VERSION "V5.0.0"

NS_ :

BS_:

BU_: SGW_SG CGW_SG

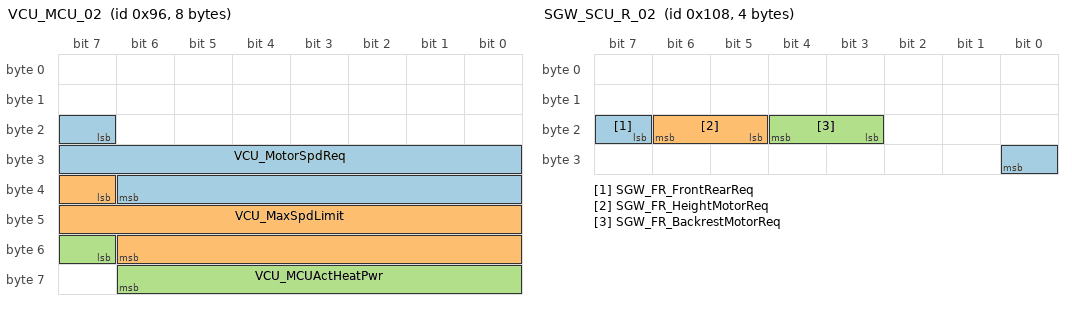
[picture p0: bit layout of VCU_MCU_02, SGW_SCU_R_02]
BO_ 150 VCU_MCU_02: 8 CGW_SG
 SG_ VCU_MotorSpdReq : 23|16@1+ (1,-32767) [-32767|32767] ""  SGW_SG
 SG_ VCU_MaxSpdLimit : 39|16@1+ (1,-32767) [-32767|32767] ""  SGW_SG
 SG_ VCU_MCUActHeatPwr : 55|8@1+ (0,0) [0|10] "kW"  SGW_SG

BO_ 194 BMS_status_02: 9 CGW_SG
 SG_ BMS_BattVolt : 23|14@1+ (0,0) [0|1000] "V"  SGW_SG
 SG_ BMS_BattCurr : 39|15@1+ (0,-1024) [-1024|1023] "A"  SGW_SG
 SG_ BMS_Heatcurrent : 55|16@1+ (0,-1024) [-1024|1023] "A"  SGW_SG

BO_ 257 CBM_request_01: 4 SGW_SG
 SG_ CBM_BLE_CarSearchReq : 26|1@1+ (1,0) [0|1] ""  CGW_SG

BO_ 259 SGW_SCU_L_01: 9 SGW_SG
 SG_ IVI_L_DsSeatBackPos : 23|8@1+ (1,0) [0|100] "percent"  CGW_SG
 SG_ IVI_L_DsSeatHeightPos : 31|8@1+ (1,0) [0|100] "percent"  CGW_SG
 SG_ IVI_L_DsSeatSlidePos : 39|8@1+ (1,0) [0|100] "percent"  CGW_SG
 SG_ IVI_DrSeatHeatLevelSet : 51|3@1+ (1,0) [0|7] ""  CGW_SG
 SG_ IVI_DrSeatWelcomeLevelSet : 63|2@1+ (1,0) [0|3] ""  CGW_SG

BO_ 260 SGW_SCU_R_01: 9 SGW_SG
 SG_ IVI_R_DsSeatSlidePos : 23|8@1+ (1,0) [0|100] "percent"  CGW_SG
 SG_ IVI_R_DsSeatHeightPos : 31|8@1+ (1,0) [0|100] "percent"  CGW_SG
 SG_ IVI_R_DsSeatBackPos : 39|8@1+ (1,0) [0|100] "percent"  CGW_SG
 SG_ IVI_PassSeatHeatLevelSet : 51|3@1+ (1,0) [0|7] ""  CGW_SG
 SG_ IVI_PsSeatWelcomeLevelSet : 63|2@1+ (1,0) [0|3] ""  CGW_SG

BO_ 262 SGW_RemoteCmd_02: 5 SGW_SG
 SG_ IVI_HUDScreenBrightnessSet : 31|5@1+ (1,0) [0|31] ""  CGW_SG

BO_ 264 SGW_SCU_R_02: 4 SGW_SG
 SG_ SGW_FR_FrontRearReq : 23|2@1+ (1,0) [0|2] ""  CGW_SG
 SG_ SGW_FR_HeightMotorReq : 21|2@1+ (1,0) [0|2] ""  CGW_SG
 SG_ SGW_FR_BackrestMotorReq : 19|2@1+ (1,0) [0|2] ""  CGW_SG

BO_ 267 BCM_10: 5 CGW_SG
 SG_ BCM_CentralLockFeedback : 38|2@1+ (1,0) [0|3] ""  SGW_SG
 SG_ BCM_LVonReqKeyNotInCar : 36|1@1+ (1,0) [0|1] ""  SGW_SG

BO_ 268 SGW_10: 9 SGW_SG
 SG_ SGW_PENFCAuthSt : 5|1@1+ (1,0) [0|1] ""  CGW_SG
 SG_ SGW_GetNFCKeyCardsReq : 4|1@1+ (1,0) [0|1] ""  CGW_SG
 SG_ SGW_NFCPairModeReq : 3|1@1+ (1,0) [0|1] ""  CGW_SG
 SG_ SGW_SecOCFV_10C : 23|16@1+ (1,0) [0|65535] ""  CGW_SG
 SG_ SGW_SecOCMAC_10C : 39|32@1+ (1,0) [0|4294967295] ""  CGW_SG

BO_ 271 Switches_03: 1 CGW_SG
 SG_ Switches_L_SWipe_Cmd : 0|4@1+ (1,0) [0|15] ""  SGW_SG

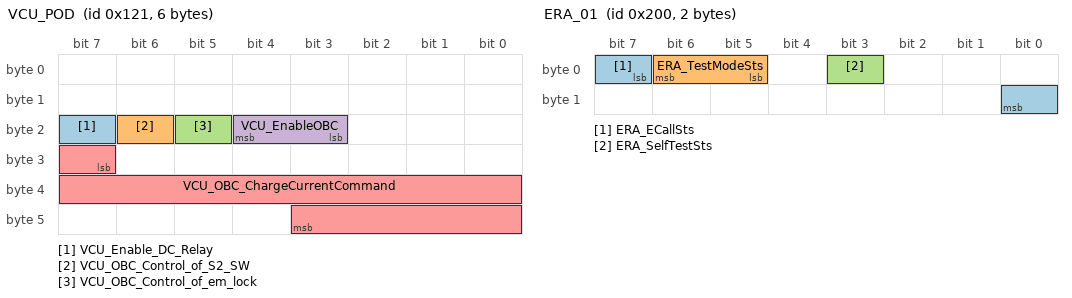
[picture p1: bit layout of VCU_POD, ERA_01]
BO_ 289 VCU_POD: 6 CGW_SG
 SG_ VCU_Enable_DC_Relay : 23|1@1+ (1,0) [0|1] ""  SGW_SG
 SG_ VCU_OBC_Control_of_S2_SW : 22|1@1+ (1,0) [0|1] ""  SGW_SG
 SG_ VCU_OBC_Control_of_em_lock : 21|1@1+ (1,0) [0|1] ""  SGW_SG
 SG_ VCU_EnableOBC : 19|2@1+ (1,0) [0|3] ""  SGW_SG
 SG_ VCU_OBC_ChargeCurrentCommand : 31|13@1+ (0,0) [0|500] "A"  SGW_SG

BO_ 311 DCM_RL_02: 1 CGW_SG
 SG_ DCM_RL_PriorSoundReq : 7|1@1+ (1,0) [0|1] ""  SGW_SG

BO_ 312 DCM_RR_02: 1 CGW_SG
 SG_ DCM_RR_PriorSoundReq : 7|1@1+ (1,0) [0|1] ""  SGW_SG

BO_ 316 SGW_RemoteCmd_04: 9 SGW_SG
 SG_ SGW_L_MirrorMainHorizontalPos : 7|8@1+ (1,0) [0|100] "percent"  CGW_SG
 SG_ SGW_L_MirrorMainVerticalPos : 15|8@1+ (1,0) [0|100] "percent"  CGW_SG
 SG_ SGW_R_MirrorMainHorizontalPos : 23|8@1+ (1,0) [0|100] "percent"  CGW_SG
 SG_ SGW_R_MirrorMainVerticalPos : 31|8@1+ (1,0) [0|100] "percent"  CGW_SG
 SG_ SGW_L_MirrorTiltHorizontalPos : 39|8@1+ (1,0) [0|100] "percent"  CGW_SG
 SG_ SGW_L_MirrorTiltVerticalPos : 47|8@1+ (1,0) [0|100] "percent"  CGW_SG
 SG_ SGW_R_MirrorTiltHorizontalPos : 55|8@1+ (1,0) [0|100] "percent"  CGW_SG
 SG_ SGW_R_MirrorTiltVerticalPos : 63|8@1+ (1,0) [0|100] "percent"  CGW_SG

BO_ 317 BCM_SynReq_01: 4 CGW_SG
 SG_ BCM_SynRequest : 7|24@1+ (1,0) [0|16777215] ""  SGW_SG

BO_ 319 VCU_SynReq_01: 4 CGW_SG
 SG_ VCU_SynRequest : 7|24@1+ (1,0) [0|16777215] ""  SGW_SG

BO_ 512 ERA_01: 2 SGW_SG
 SG_ ERA_ECallSts : 7|2@1+ (1,0) [0|3] ""  CGW_SG
 SG_ ERA_TestModeSts : 5|2@1+ (1,0) [0|3] ""  CGW_SG
 SG_ ERA_SelfTestSts : 3|1@1+ (1,0) [0|1] ""  CGW_SG

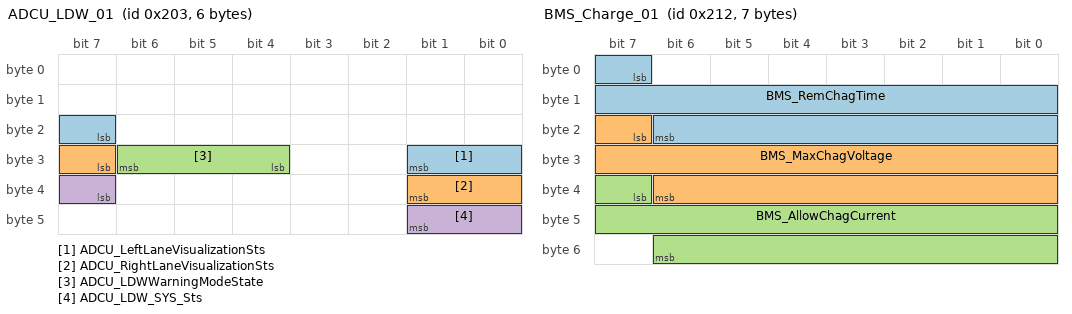
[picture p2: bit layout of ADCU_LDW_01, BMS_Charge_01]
BO_ 515 ADCU_LDW_01: 6 CGW_SG
 SG_ ADCU_LeftLaneVisualizationSts : 23|3@1+ (1,0) [0|5] ""  CGW_SG
 SG_ ADCU_RightLaneVisualizationSts : 31|3@1+ (1,0) [0|5] ""  CGW_SG
 SG_ ADCU_LDWWarningModeState : 28|3@1+ (1,0) [0|7] ""  CGW_SG
 SG_ ADCU_LDW_SYS_Sts : 39|3@1+ (1,0) [0|7] ""  SGW_SG

BO_ 530 BMS_Charge_01: 7 CGW_SG
 SG_ BMS_RemChagTime : 7|16@1+ (1,0) [0|3600] "min"  SGW_SG
 SG_ BMS_MaxChagVoltage : 23|16@1+ (0,0) [0|6553] "V"  SGW_SG
 SG_ BMS_AllowChagCurrent : 39|16@1+ (0,-1000) [-1000|1000] "A"  SGW_SG

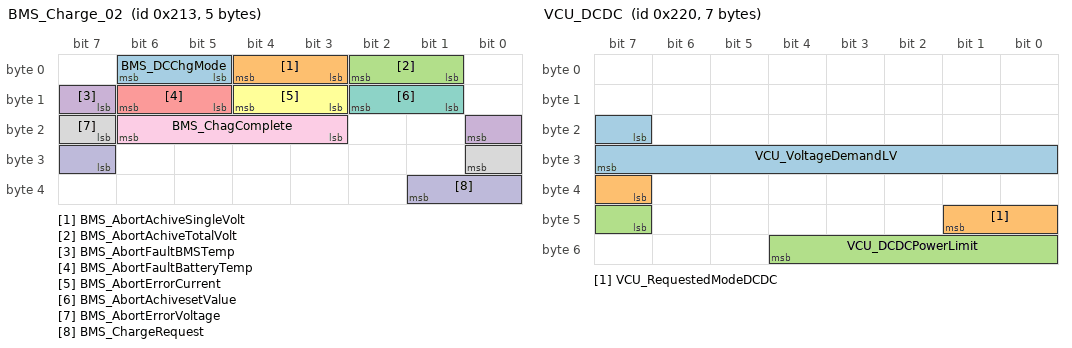
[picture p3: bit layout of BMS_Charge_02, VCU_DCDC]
BO_ 531 BMS_Charge_02: 5 CGW_SG
 SG_ BMS_DCChgMode : 5|2@1+ (1,0) [0|2] ""  SGW_SG
 SG_ BMS_AbortAchiveSingleVolt : 3|2@1+ (1,0) [0|2] ""  SGW_SG
 SG_ BMS_AbortAchiveTotalVolt : 1|2@1+ (1,0) [0|2] ""  SGW_SG
 SG_ BMS_AbortFaultBMSTemp : 15|2@1+ (1,0) [0|2] ""  SGW_SG
 SG_ BMS_AbortFaultBatteryTemp : 13|2@1+ (1,0) [0|2] ""  SGW_SG
 SG_ BMS_AbortErrorCurrent : 11|2@1+ (1,0) [0|2] ""  SGW_SG
 SG_ BMS_AbortAchivesetValue : 9|2@1+ (1,0) [0|2] ""  SGW_SG
 SG_ BMS_AbortErrorVoltage : 23|2@1+ (1,0) [0|2] ""  SGW_SG
 SG_ BMS_ChagComplete : 19|4@1+ (1,0) [0|3] ""  SGW_SG
 SG_ BMS_ChargeRequest : 31|3@1+ (1,0) [0|4] ""  SGW_SG

BO_ 532 BMS_status_03: 9 CGW_SG
 SG_ BMS_PackVoltage : 7|16@1+ (0,0) [0|6553] "V"  SGW_SG
 SG_ BMS_LinkVoltage : 23|16@1+ (0,0) [0|6553] "V"  SGW_SG
 SG_ BMS_SOC : 39|16@1+ (0,0) [0|100] "percent"  SGW_SG
 SG_ BMS_DisplaySOC : 55|16@1+ (0,0) [0|100] "percent"  SGW_SG

BO_ 536 BMS_CellTemp: 9 CGW_SG
 SG_ BMS_ThermometerProbes : 7|8@1+ (1,0) [0|255] ""  SGW_SG
 SG_ BMS_AverageCellTemp : 15|8@1+ (1,-40) [-40|215] "celsius"  SGW_SG
 SG_ BMS_MaxCellTemp : 23|8@1+ (1,-40) [-40|215] "celsius"  SGW_SG
 SG_ BMS_MinCellTemp : 31|8@1+ (1,-40) [-40|215] "celsius"  SGW_SG
 SG_ BMS_MaxCellTempModuleNO : 39|8@1+ (1,0) [0|255] ""  SGW_SG
 SG_ BMS_MinCellTempModuleNO : 47|8@1+ (1,0) [0|255] ""  SGW_SG
 SG_ BMS_MaxCellTempNO : 55|8@1+ (1,0) [0|255] ""  SGW_SG
 SG_ BMS_MinCellTempNO : 63|8@1+ (1,0) [0|255] ""  SGW_SG

BO_ 544 VCU_DCDC: 7 CGW_SG
 SG_ VCU_VoltageDemandLV : 23|9@1+ (0,0) [0|63] "V"  SGW_SG
 SG_ VCU_RequestedModeDCDC : 39|3@1+ (1,0) [0|2] ""  SGW_SG
 SG_ VCU_DCDCPowerLimit : 47|6@1+ (0,0) [0|6] "kW"  SGW_SG

BO_ 547 VCU_04: 2 CGW_SG
 SG_ VCU_ForwardVmaxlimitStatus : 15|1@1+ (1,0) [0|1] ""  SGW_SG
 SG_ VCU_ManuallyUnlockComment : 14|1@1+ (1,0) [0|1] ""  SGW_SG

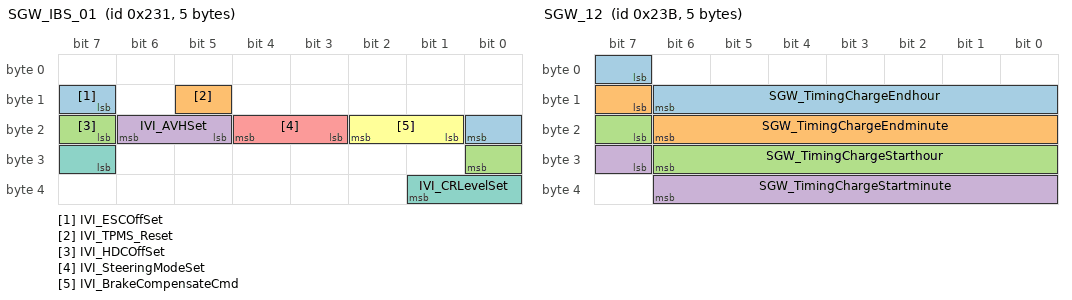
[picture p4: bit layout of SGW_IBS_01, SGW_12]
BO_ 561 SGW_IBS_01: 5 SGW_SG
 SG_ IVI_ESCOffSet : 15|2@1+ (1,0) [0|3] ""  CGW_SG
 SG_ IVI_TPMS_Reset : 13|1@1+ (1,0) [0|1] ""  CGW_SG
 SG_ IVI_HDCOffSet : 23|2@1+ (1,0) [0|3] ""  CGW_SG
 SG_ IVI_AVHSet : 21|2@1+ (1,0) [0|3] ""  CGW_SG
 SG_ IVI_SteeringModeSet : 19|2@1+ (1,0) [0|3] ""  CGW_SG
 SG_ IVI_BrakeCompensateCmd : 17|2@1+ (1,0) [0|3] ""  CGW_SG
 SG_ IVI_CRLevelSet : 31|3@1+ (1,0) [0|7] ""  CGW_SG

BO_ 569 SGW_BCM_03: 9 SGW_SG
 SG_ SGW_RoleAccessSts : 7|1@1+ (1,0) [0|1] ""  CGW_SG
 SG_ SGW_FaceIDAuthenticationSuccess : 5|1@1+ (1,0) [0|1] ""  CGW_SG
 SG_ SGW_ImmobilizingEnable : 1|2@1+ (1,0) [0|2] ""  CGW_SG
 SG_ SGW_SecOCFV_239 : 23|16@1+ (1,0) [0|65535] ""  CGW_SG
 SG_ SGW_SecOCMAC_239 : 39|32@1+ (1,0) [0|4294967295] ""  CGW_SG

BO_ 571 SGW_12: 5 SGW_SG
 SG_ SGW_TimingChargeEndhour : 7|8@1+ (1,0) [0|31] "h"  CGW_SG
 SG_ SGW_TimingChargeEndminute : 15|8@1+ (1,0) [0|63] "min"  CGW_SG
 SG_ SGW_TimingChargeStarthour : 23|8@1+ (1,0) [0|31] "h"  CGW_SG
 SG_ SGW_TimingChargeStartminute : 31|8@1+ (1,0) [0|63] "min"  CGW_SG

BO_ 574 SGW_DCM_02: 9 SGW_SG
 SG_ IVI_FLDoorLockSet : 45|2@1+ (1,0) [0|3] ""  CGW_SG
 SG_ IVI_FRDoorLockSet : 43|2@1+ (1,0) [0|3] ""  CGW_SG
 SG_ IVI_RLDoorLockSet : 41|2@1+ (1,0) [0|3] ""  CGW_SG
 SG_ IVI_RRDoorLockSet : 55|2@1+ (1,0) [0|3] ""  CGW_SG
 SG_ IVI_PassWindowLockSet : 63|2@1+ (1,0) [0|3] ""  CGW_SG
 SG_ IVI_ModeEnterReq : 35|4@1+ (1,0) [0|15] ""  CGW_SG

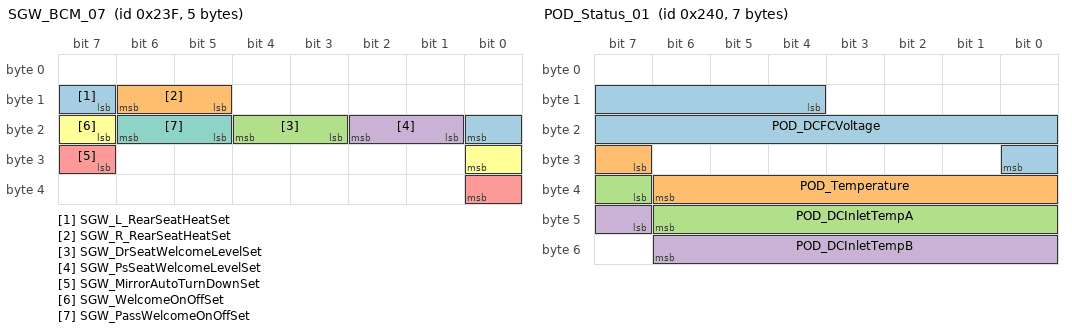
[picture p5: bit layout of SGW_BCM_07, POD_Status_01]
BO_ 575 SGW_BCM_07: 5 SGW_SG
 SG_ SGW_L_RearSeatHeatSet : 15|2@1+ (1,0) [0|3] ""  CGW_SG
 SG_ SGW_R_RearSeatHeatSet : 13|2@1+ (1,0) [0|3] ""  CGW_SG
 SG_ SGW_DrSeatWelcomeLevelSet : 19|2@1+ (1,0) [0|3] ""  CGW_SG
 SG_ SGW_PsSeatWelcomeLevelSet : 17|2@1+ (1,0) [0|3] ""  CGW_SG
 SG_ SGW_MirrorAutoTurnDownSet : 31|2@1+ (1,0) [0|3] ""  CGW_SG
 SG_ SGW_WelcomeOnOffSet : 23|2@1+ (1,0) [0|3] ""  CGW_SG
 SG_ SGW_PassWelcomeOnOffSet : 21|2@1+ (1,0) [0|3] ""  CGW_SG

BO_ 576 POD_Status_01: 7 CGW_SG
 SG_ POD_DCFCVoltage : 12|13@1+ (0,0) [0|819] "V"  SGW_SG
 SG_ POD_Temperature : 31|8@1+ (1,-40) [-40|215] "celsius"  SGW_SG
 SG_ POD_DCInletTempA : 39|8@1+ (1,-40) [-40|215] "celsius"  SGW_SG
 SG_ POD_DCInletTempB : 47|8@1+ (1,-40) [-40|215] "celsius"  SGW_SG

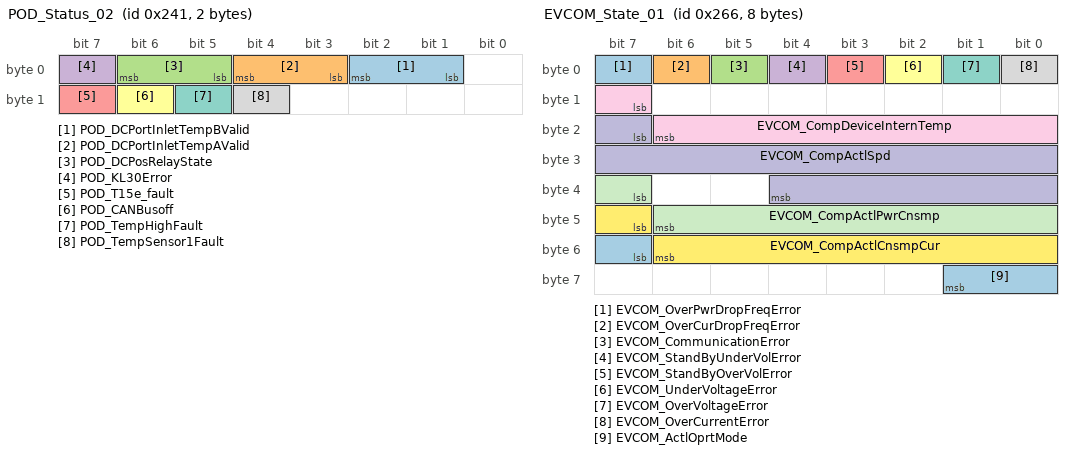
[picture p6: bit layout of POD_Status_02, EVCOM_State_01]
BO_ 577 POD_Status_02: 2 CGW_SG
 SG_ POD_DCPortInletTempBValid : 1|2@1+ (1,0) [0|2] ""  SGW_SG
 SG_ POD_DCPortInletTempAValid : 3|2@1+ (1,0) [0|2] ""  SGW_SG
 SG_ POD_DCPosRelayState : 5|2@1+ (1,0) [0|2] ""  SGW_SG
 SG_ POD_KL30Error : 7|1@1+ (1,0) [0|1] ""  SGW_SG
 SG_ POD_T15e_fault : 15|1@1+ (1,0) [0|1] ""  SGW_SG
 SG_ POD_CANBusoff : 14|1@1+ (1,0) [0|1] ""  SGW_SG
 SG_ POD_TempHighFault : 13|1@1+ (1,0) [0|1] ""  SGW_SG
 SG_ POD_TempSensor1Fault : 12|1@1+ (1,0) [0|1] ""  SGW_SG

BO_ 578 POD_DCDC_01: 9 CGW_SG
 SG_ POD_DCDC_HVInputVoltage : 9|13@1+ (0,0) [0|800] "V"  SGW_SG
 SG_ POD_DCDC_WorkMode : 28|3@1+ (1,0) [0|4] ""  SGW_SG
 SG_ POD_DCDC_LVOutputCurrent : 39|12@1+ (0,0) [0|400] "A"  SGW_SG
 SG_ POD_DCDC_HVInputCurrent : 55|8@1+ (0,0) [0|25] "A"  SGW_SG
 SG_ POD_DCDC_LVOutputVoltage : 63|8@1+ (0,0) [0|25] "V"  SGW_SG

BO_ 580 POD_OBC_STATUS_02: 9 CGW_SG
 SG_ POD_OBC_ChrgOutpPwrAvl : 7|8@1+ (0,-7) [-7|13] "kW"  SGW_SG
 SG_ POD_OBC_OutputDCChargeCurrent : 15|13@1+ (0,-250) [-250|250] "A"  SGW_SG
 SG_ POD_OBC_ACPortTempA : 31|8@1+ (1,-40) [-40|215] "celsius"  SGW_SG
 SG_ POD_OBC_ACPortTempB : 39|8@1+ (1,-40) [-40|215] "celsius"  SGW_SG
 SG_ POD_OBC_ACFrequencyStatus : 47|8@1+ (1,0) [0|255] "Hz"  SGW_SG
 SG_ POD_OBC_OutputDCChargeVoltage : 55|14@1+ (0,-800) [-800|800] "V"  SGW_SG

BO_ 610 TCU_03: 4 CGW_SG
 SG_ TCU_CabinTemperature : 23|8@1+ (1,-50) [-50|205] "celsius"  SGW_SG
 SG_ TCU_CabinTemperatureValid : 31|1@1+ (1,0) [0|1] ""  SGW_SG

BO_ 614 EVCOM_State_01: 8 CGW_SG
 SG_ EVCOM_OverPwrDropFreqError : 7|1@1+ (1,0) [0|1] ""  SGW_SG
 SG_ EVCOM_OverCurDropFreqError : 6|1@1+ (1,0) [0|1] ""  SGW_SG
 SG_ EVCOM_CommunicationError : 5|1@1+ (1,0) [0|1] ""  SGW_SG
 SG_ EVCOM_StandByUnderVolError : 4|1@1+ (1,0) [0|1] ""  SGW_SG
 SG_ EVCOM_StandByOverVolError : 3|1@1+ (1,0) [0|1] ""  SGW_SG
 SG_ EVCOM_UnderVoltageError : 2|1@1+ (1,0) [0|1] ""  SGW_SG
 SG_ EVCOM_OverVoltageError : 1|1@1+ (1,0) [0|1] ""  SGW_SG
 SG_ EVCOM_OverCurrentError : 0|1@1+ (1,0) [0|1] ""  SGW_SG
 SG_ EVCOM_CompDeviceInternTemp : 15|8@1+ (1,-40) [-40|215] "celsius"  SGW_SG
 SG_ EVCOM_CompActlSpd : 23|14@1+ (1,0) [0|9200] "rpm"  SGW_SG
 SG_ EVCOM_CompActlPwrCnsmp : 39|8@1+ (0,0) [0|10] "KW"  SGW_SG
 SG_ EVCOM_CompActlCnsmpCur : 47|8@1+ (0,0) [0|51] "A"  SGW_SG
 SG_ EVCOM_ActlOprtMode : 55|3@1+ (1,0) [0|7] ""  SGW_SG

BO_ 624 BCM_ALM: 1 CGW_SG
 SG_ BCM_ALM1_MusicFrequencySts : 5|1@1+ (1,0) [0|1] ""  SGW_SG
 SG_ BCM_ALM2_MusicFrequencySts : 4|1@1+ (1,0) [0|1] ""  SGW_SG

BO_ 626 BCM_11: 9 CGW_SG
 SG_ BCM_Immo_State : 7|1@1+ (1,0) [0|1] ""  SGW_SG
 SG_ BCM_SecOCFV_272 : 23|16@1+ (1,0) [0|65535] ""  SGW_SG
 SG_ BCM_SecOCMAC_272 : 39|32@1+ (1,0) [0|4294967295] ""  SGW_SG

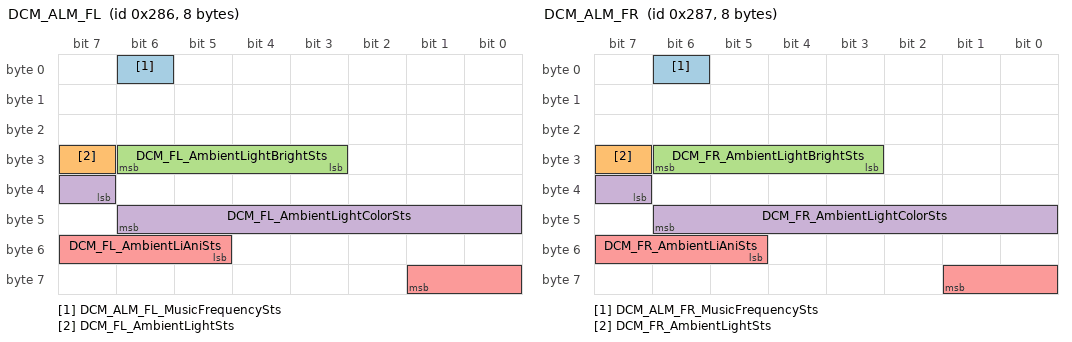
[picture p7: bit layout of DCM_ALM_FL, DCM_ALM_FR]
BO_ 646 DCM_ALM_FL: 8 CGW_SG
 SG_ DCM_ALM_FL_MusicFrequencySts : 6|1@1+ (1,0) [0|1] ""  SGW_SG
 SG_ DCM_FL_AmbientLightSts : 31|1@1+ (1,0) [0|1] ""  SGW_SG
 SG_ DCM_FL_AmbientLightBrightSts : 27|4@1+ (1,0) [0|10] ""  SGW_SG
 SG_ DCM_FL_AmbientLightColorSts : 39|8@1+ (1,0) [0|255] ""  SGW_SG
 SG_ DCM_FL_AmbientLiAniSts : 53|5@1+ (1,0) [0|25] ""  SGW_SG

BO_ 647 DCM_ALM_FR: 8 CGW_SG
 SG_ DCM_ALM_FR_MusicFrequencySts : 6|1@1+ (1,0) [0|1] ""  SGW_SG
 SG_ DCM_FR_AmbientLightSts : 31|1@1+ (1,0) [0|1] ""  SGW_SG
 SG_ DCM_FR_AmbientLightBrightSts : 27|4@1+ (1,0) [0|10] ""  SGW_SG
 SG_ DCM_FR_AmbientLightColorSts : 39|8@1+ (1,0) [0|255] ""  SGW_SG
 SG_ DCM_FR_AmbientLiAniSts : 53|5@1+ (1,0) [0|25] ""  SGW_SG

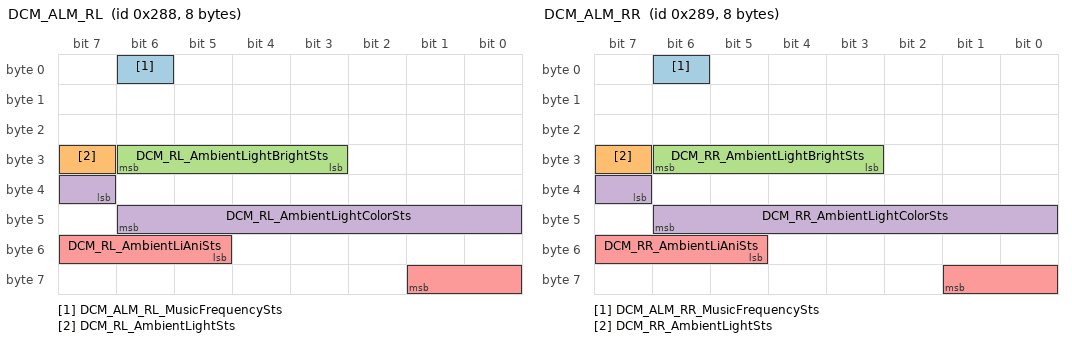
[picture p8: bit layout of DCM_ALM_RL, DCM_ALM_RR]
BO_ 648 DCM_ALM_RL: 8 CGW_SG
 SG_ DCM_ALM_RL_MusicFrequencySts : 6|1@1+ (1,0) [0|1] ""  SGW_SG
 SG_ DCM_RL_AmbientLightSts : 31|1@1+ (1,0) [0|1] ""  SGW_SG
 SG_ DCM_RL_AmbientLightBrightSts : 27|4@1+ (1,0) [0|10] ""  SGW_SG
 SG_ DCM_RL_AmbientLightColorSts : 39|8@1+ (1,0) [0|255] ""  SGW_SG
 SG_ DCM_RL_AmbientLiAniSts : 53|5@1+ (1,0) [0|25] ""  SGW_SG

BO_ 649 DCM_ALM_RR: 8 CGW_SG
 SG_ DCM_ALM_RR_MusicFrequencySts : 6|1@1+ (1,0) [0|1] ""  SGW_SG
 SG_ DCM_RR_AmbientLightSts : 31|1@1+ (1,0) [0|1] ""  SGW_SG
 SG_ DCM_RR_AmbientLightBrightSts : 27|4@1+ (1,0) [0|10] ""  SGW_SG
 SG_ DCM_RR_AmbientLightColorSts : 39|8@1+ (1,0) [0|255] ""  SGW_SG
 SG_ DCM_RR_AmbientLiAniSts : 53|5@1+ (1,0) [0|25] ""  SGW_SG

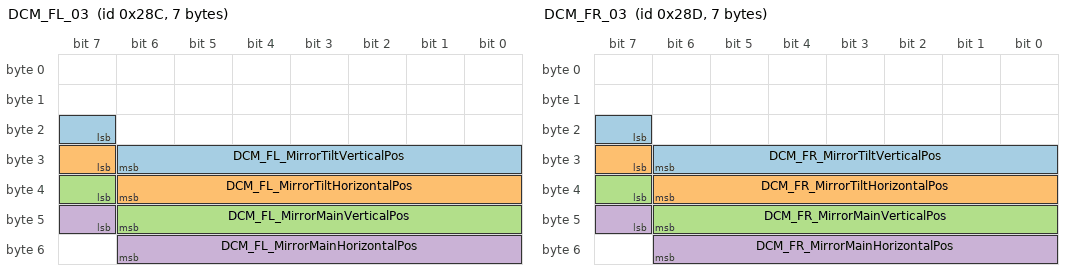
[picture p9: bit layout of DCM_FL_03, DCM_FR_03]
BO_ 652 DCM_FL_03: 7 CGW_SG
 SG_ DCM_FL_MirrorTiltVerticalPos : 23|8@1+ (1,0) [0|100] "percent"  SGW_SG
 SG_ DCM_FL_MirrorTiltHorizontalPos : 31|8@1+ (1,0) [0|100] "percent"  SGW_SG
 SG_ DCM_FL_MirrorMainVerticalPos : 39|8@1+ (1,0) [0|100] "percent"  SGW_SG
 SG_ DCM_FL_MirrorMainHorizontalPos : 47|8@1+ (1,0) [0|100] "percent"  SGW_SG

BO_ 653 DCM_FR_03: 7 CGW_SG
 SG_ DCM_FR_MirrorTiltVerticalPos : 23|8@1+ (1,0) [0|100] "percent"  SGW_SG
 SG_ DCM_FR_MirrorTiltHorizontalPos : 31|8@1+ (1,0) [0|100] "percent"  SGW_SG
 SG_ DCM_FR_MirrorMainVerticalPos : 39|8@1+ (1,0) [0|100] "percent"  SGW_SG
 SG_ DCM_FR_MirrorMainHorizontalPos : 47|8@1+ (1,0) [0|100] "percent"  SGW_SG

BO_ 663 WCBS_01: 1 CGW_SG
 SG_ WCBS1_Reminder : 0|1@1+ (1,0) [0|1] ""  SGW_SG
 SG_ WCBS1_ReminderSts : 1|1@1+ (1,0) [0|1] ""  SGW_SG

BO_ 664 WCBS_02: 1 CGW_SG
 SG_ WCBS2_Reminder : 0|1@1+ (1,0) [0|1] ""  SGW_SG
 SG_ WCBS2_ReminderSts : 1|1@1+ (1,0) [0|1] ""  SGW_SG

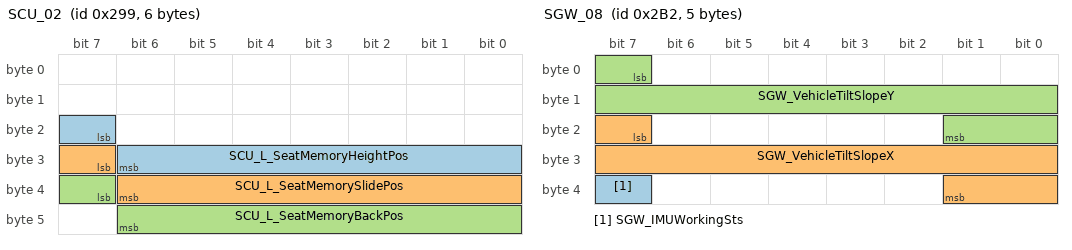
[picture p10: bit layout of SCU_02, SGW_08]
BO_ 665 SCU_02: 6 CGW_SG
 SG_ SCU_L_SeatMemoryHeightPos : 23|8@1+ (1,0) [0|100] "percent"  SGW_SG
 SG_ SCU_L_SeatMemorySlidePos : 31|8@1+ (1,0) [0|100] "percent"  SGW_SG
 SG_ SCU_L_SeatMemoryBackPos : 39|8@1+ (1,0) [0|100] "percent"  SGW_SG

BO_ 689 SGW_HUD_01: 3 SGW_SG
 SG_ IVI_HUDALTITUDESet : 7|8@1+ (1,0) [0|255] ""  CGW_SG
 SG_ IVI_HUDOnOffSet : 15|2@1+ (1,0) [0|3] ""  CGW_SG

BO_ 690 SGW_08: 5 SGW_SG
 SG_ SGW_IMUWorkingSts : 39|1@1+ (1,0) [0|1] ""  CGW_SG
 SG_ SGW_VehicleTiltSlopeX : 23|11@1+ (0,-1) [-1|1] ""  CGW_SG
 SG_ SGW_VehicleTiltSlopeY : 7|11@1+ (0,-1) [-1|1] ""  CGW_SG

BO_ 692 SGW_16: 5 SGW_SG
 SG_ IVI_MirrorInterfaceMode : 21|1@1+ (1,0) [0|1] ""  CGW_SG
 SG_ IVI_VrState : 33|1@1+ (1,0) [0|1] ""  CGW_SG

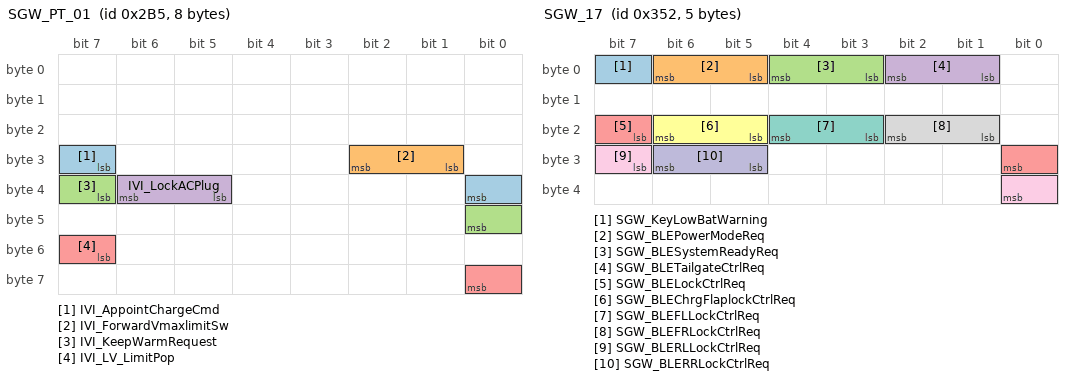
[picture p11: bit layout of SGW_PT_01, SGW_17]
BO_ 693 SGW_PT_01: 8 SGW_SG
 SG_ IVI_AppointChargeCmd : 31|2@1+ (1,0) [0|2] ""  CGW_SG
 SG_ IVI_ForwardVmaxlimitSw : 25|2@1+ (1,0) [0|3] ""  CGW_SG
 SG_ IVI_KeepWarmRequest : 39|2@1+ (1,0) [0|2] ""  CGW_SG
 SG_ IVI_LockACPlug : 37|2@1+ (1,0) [0|2] ""  CGW_SG
 SG_ IVI_LV_LimitPop : 55|2@1+ (1,0) [0|2] ""  CGW_SG

BO_ 694 IVI_01: 3 CGW_SG
 SG_ IVI_GearRequest : 15|3@1+ (1,0) [0|5] ""  SGW_SG

BO_ 710 SGW_SteerWhPos: 6 SGW_SG
 SG_ IVI_StWAnglePos : 31|8@1+ (1,-100) [-100|100] "percent"  CGW_SG
 SG_ IVI_StWLengthPos : 39|8@1+ (1,-100) [-100|100] "percent"  CGW_SG

BO_ 721 CBM_13: 9 SGW_SG
 SG_ CBM_PhoneLocation : 15|8@1+ (1,0) [0|8] ""  CGW_SG
 SG_ CBM_BlePairingSetSts : 7|2@1+ (1,0) [0|2] ""  CGW_SG
 SG_ CBM_SecOCFV_2D1 : 23|16@1+ (1,0) [0|65535] ""  CGW_SG
 SG_ CBM_SecOCMAC_2D1 : 39|32@1+ (1,0) [0|4294967295] ""  CGW_SG

BO_ 795 VCU_HMIsignals_03: 5 CGW_SG
 SG_ VCU_Display_voltage : 23|10@1+ (1,0) [0|1023] "V"  SGW_SG

BO_ 850 SGW_17: 5 SGW_SG
 SG_ SGW_KeyLowBatWarning : 7|1@1+ (1,0) [0|1] ""  CGW_SG
 SG_ SGW_BLEPowerModeReq : 5|2@1+ (1,0) [0|3] ""  CGW_SG
 SG_ SGW_BLESystemReadyReq : 3|2@1+ (1,0) [0|3] ""  CGW_SG
 SG_ SGW_BLETailgateCtrlReq : 1|2@1+ (1,0) [0|3] ""  CGW_SG
 SG_ SGW_BLELockCtrlReq : 23|2@1+ (1,0) [0|3] ""  CGW_SG
 SG_ SGW_BLEChrgFlaplockCtrlReq : 21|2@1+ (1,0) [0|3] ""  CGW_SG
 SG_ SGW_BLEFLLockCtrlReq : 19|2@1+ (1,0) [0|3] ""  CGW_SG
 SG_ SGW_BLEFRLockCtrlReq : 17|2@1+ (1,0) [0|3] ""  CGW_SG
 SG_ SGW_BLERLLockCtrlReq : 31|2@1+ (1,0) [0|3] ""  CGW_SG
 SG_ SGW_BLERRLockCtrlReq : 29|2@1+ (1,0) [0|3] ""  CGW_SG

BO_ 857 SGW_06: 3 SGW_SG
 SG_ SGW_SGWSts : 0|1@1+ (1,0) [0|1] ""  CGW_SG
 SG_ SGW_CGWSts : 1|1@1+ (1,0) [0|1] ""  CGW_SG
 SG_ SGW_CBMSts : 2|1@1+ (1,0) [0|1] ""  CGW_SG
 SG_ SGW_DCM_FLSts : 3|1@1+ (1,0) [0|1] ""  CGW_SG
 SG_ SGW_DCM_FRSts : 4|1@1+ (1,0) [0|1] ""  CGW_SG
 SG_ SGW_DCM_RLSts : 5|1@1+ (1,0) [0|1] ""  CGW_SG
 SG_ SGW_DCM_RRSts : 6|1@1+ (1,0) [0|1] ""  CGW_SG
 SG_ SGW_SCU_LSts : 7|1@1+ (1,0) [0|1] ""  CGW_SG
 SG_ SGW_SCU_RSts : 8|1@1+ (1,0) [0|1] ""  CGW_SG
 SG_ SGW_HLRSts : 9|1@1+ (1,0) [0|1] ""  CGW_SG
 SG_ SGW_HLLSts : 10|1@1+ (1,0) [0|1] ""  CGW_SG
 SG_ SGW_MFP_RCSts : 11|1@1+ (1,0) [0|1] ""  CGW_SG
 SG_ SGW_MFP_FCSts : 12|1@1+ (1,0) [0|1] ""  CGW_SG
 SG_ SGW_IVISts : 13|1@1+ (1,0) [0|1] ""  CGW_SG
 SG_ SGW_ADCUSts : 14|1@1+ (1,0) [0|1] ""  CGW_SG
 SG_ SGW_VCUSts : 15|1@1+ (1,0) [0|1] ""  CGW_SG
 SG_ SGW_BMSSts : 16|1@1+ (1,0) [0|1] ""  CGW_SG
 SG_ SGW_BCMSts : 17|1@1+ (1,0) [0|1] ""  CGW_SG
 SG_ SGW_SWPSts : 18|1@1+ (1,0) [0|1] ""  CGW_SG
 SG_ SGW_HOD_HeatingSts : 19|1@1+ (1,0) [0|1] ""  CGW_SG
 SG_ SGW_SwichesSts : 20|1@1+ (1,0) [0|1] ""  CGW_SG
 SG_ SGW_PRNDSts : 21|1@1+ (1,0) [0|1] ""  CGW_SG

BO_ 858 CGW_02: 3 CGW_SG
 SG_ CGW_SGWSts : 0|1@1+ (1,0) [0|1] ""  SGW_SG
 SG_ CGW_CGWSts : 1|1@1+ (1,0) [0|1] ""  SGW_SG
 SG_ CGW_CBMSts : 2|1@1+ (1,0) [0|1] ""  SGW_SG
 SG_ CGW_DCM_FLSts : 3|1@1+ (1,0) [0|1] ""  SGW_SG
 SG_ CGW_DCM_FRSts : 4|1@1+ (1,0) [0|1] ""  SGW_SG
 SG_ CGW_DCM_RLSts : 5|1@1+ (1,0) [0|1] ""  SGW_SG
 SG_ CGW_DCM_RRSts : 6|1@1+ (1,0) [0|1] ""  SGW_SG
 SG_ CGW_SCU_LSts : 7|1@1+ (1,0) [0|1] ""  SGW_SG
 SG_ CGW_SCU_RSts : 8|1@1+ (1,0) [0|1] ""  SGW_SG
 SG_ CGW_HLRSts : 9|1@1+ (1,0) [0|1] ""  SGW_SG
 SG_ CGW_HLLSts : 10|1@1+ (1,0) [0|1] ""  SGW_SG
 SG_ CGW_MFP_RCSts : 11|1@1+ (1,0) [0|1] ""  SGW_SG
 SG_ CGW_MFP_FCSts : 12|1@1+ (1,0) [0|1] ""  SGW_SG
 SG_ CGW_IVISts : 13|1@1+ (1,0) [0|1] ""  SGW_SG
 SG_ CGW_ADCUSts : 14|1@1+ (1,0) [0|1] ""  SGW_SG
 SG_ CGW_VCUSts : 15|1@1+ (1,0) [0|1] ""  SGW_SG
 SG_ CGW_BMSSts : 16|1@1+ (1,0) [0|1] ""  SGW_SG
 SG_ CGW_BCMSts : 17|1@1+ (1,0) [0|1] ""  SGW_SG
 SG_ CGW_SWPSts : 18|1@1+ (1,0) [0|1] ""  SGW_SG
 SG_ CGW_HOD_HeatingSts : 19|1@1+ (1,0) [0|1] ""  SGW_SG
 SG_ CGW_SwichesSts : 20|1@1+ (1,0) [0|1] ""  SGW_SG
 SG_ CGW_PRNDSts : 21|1@1+ (1,0) [0|1] ""  SGW_SG

BO_ 880 DCM_FL_SDS_01: 3 CGW_SG
 SG_ DCM_SDS_FL_SensorWorksts : 15|3@1+ (1,0) [0|5] ""  SGW_SG

BO_ 881 DCM_FR_SDS_01: 3 CGW_SG
 SG_ DCM_SDS_FR_SensorWorksts : 15|3@1+ (1,0) [0|5] ""  SGW_SG

BO_ 882 DCM_RL_SDS_01: 3 CGW_SG
 SG_ DCM_SDS_RL_SensorWorksts : 15|3@1+ (1,0) [0|5] ""  SGW_SG

BO_ 883 DCM_RR_SDS_01: 3 CGW_SG
 SG_ DCM_SDS_RR_SensorWorksts : 15|3@1+ (1,0) [0|5] ""  SGW_SG

BO_ 896 CGW_VIN1: 9 CGW_SG
 SG_ CGW_VIN0 : 7|8@1+ (1,0) [0|255] ""  SGW_SG
 SG_ CGW_VIN1 : 15|8@1+ (1,0) [0|255] ""  SGW_SG
 SG_ CGW_VIN2 : 23|8@1+ (1,0) [0|255] ""  SGW_SG
 SG_ CGW_VIN3 : 31|8@1+ (1,0) [0|255] ""  SGW_SG
 SG_ CGW_VIN4 : 39|8@1+ (1,0) [0|255] ""  SGW_SG
 SG_ CGW_VIN5 : 47|8@1+ (1,0) [0|255] ""  SGW_SG
 SG_ CGW_VIN6 : 55|8@1+ (1,0) [0|255] ""  SGW_SG
 SG_ CGW_VIN7 : 63|8@1+ (1,0) [0|255] ""  SGW_SG

BO_ 897 CGW_VIN2: 9 CGW_SG
 SG_ CGW_VIN8 : 7|8@1+ (1,0) [0|255] ""  SGW_SG
 SG_ CGW_VIN9 : 15|8@1+ (1,0) [0|255] ""  SGW_SG
 SG_ CGW_VIN10 : 23|8@1+ (1,0) [0|255] ""  SGW_SG
 SG_ CGW_VIN11 : 31|8@1+ (1,0) [0|255] ""  SGW_SG
 SG_ CGW_VIN12 : 39|8@1+ (1,0) [0|255] ""  SGW_SG
 SG_ CGW_VIN13 : 47|8@1+ (1,0) [0|255] ""  SGW_SG
 SG_ CGW_VIN14 : 55|8@1+ (1,0) [0|255] ""  SGW_SG
 SG_ CGW_VIN15 : 63|8@1+ (1,0) [0|255] ""  SGW_SG

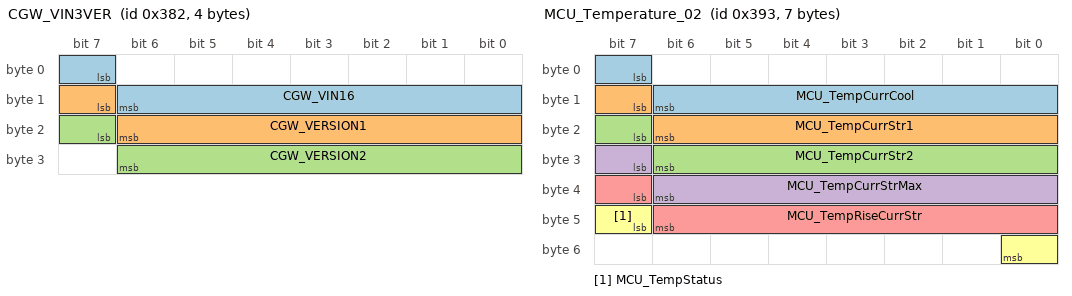
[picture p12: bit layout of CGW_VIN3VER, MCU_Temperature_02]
BO_ 898 CGW_VIN3VER: 4 CGW_SG
 SG_ CGW_VIN16 : 7|8@1+ (1,0) [0|255] ""  SGW_SG
 SG_ CGW_VERSION1 : 15|8@1+ (1,0) [0|5] ""  SGW_SG
 SG_ CGW_VERSION2 : 23|8@1+ (1,0) [0|255] ""  SGW_SG

BO_ 914 MCU_Temperature_01: 9 CGW_SG
 SG_ MCU_IGBTTempU : 7|8@1+ (1,-50) [-50|200] ""  SGW_SG
 SG_ MCU_IGBTTempV : 15|8@1+ (1,-50) [-50|200] ""  SGW_SG
 SG_ MCU_IGBTTempW : 23|8@1+ (1,-50) [-50|200] ""  SGW_SG
 SG_ MCU_IGBTTempMax : 31|8@1+ (1,-50) [-50|200] ""  SGW_SG
 SG_ MCU_IGBTTempRiseU : 39|8@1+ (1,0) [0|200] ""  SGW_SG
 SG_ MCU_IGBTTempRiseV : 47|8@1+ (1,0) [0|200] ""  SGW_SG
 SG_ MCU_IGBTTempRiseW : 55|8@1+ (1,0) [0|200] ""  SGW_SG
 SG_ MCU_IGBTTempRiseMax : 63|8@1+ (1,0) [0|200] ""  SGW_SG

BO_ 915 MCU_Temperature_02: 7 CGW_SG
 SG_ MCU_TempCurrCool : 7|8@1+ (1,-50) [-50|200] ""  SGW_SG
 SG_ MCU_TempCurrStr1 : 15|8@1+ (1,-50) [-50|200] ""  SGW_SG
 SG_ MCU_TempCurrStr2 : 23|8@1+ (1,-50) [-50|200] ""  SGW_SG
 SG_ MCU_TempCurrStrMax : 31|8@1+ (1,-50) [-50|200] ""  SGW_SG
 SG_ MCU_TempRiseCurrStr : 39|8@1+ (1,0) [0|250] ""  SGW_SG
 SG_ MCU_TempStatus : 47|2@1+ (1,0) [0|3] ""  SGW_SG

BO_ 928 MCU_SoftwareNumber: 9 CGW_SG
 SG_ MCU_CodeVer : 7|16@1+ (1,0) [0|65535] ""  SGW_SG
 SG_ MCU_DataVer : 23|16@1+ (1,0) [0|65535] ""  SGW_SG
 SG_ MCU_CpldVer : 39|16@1+ (1,0) [0|65535] ""  SGW_SG
 SG_ MCU_HvMcuVer : 55|16@1+ (1,0) [0|65535] ""  SGW_SG

BO_ 929 MCU_HardwareNumber: 3 CGW_SG
 SG_ MCU_HwVer : 7|16@1+ (1,0) [0|65535] ""  SGW_SG

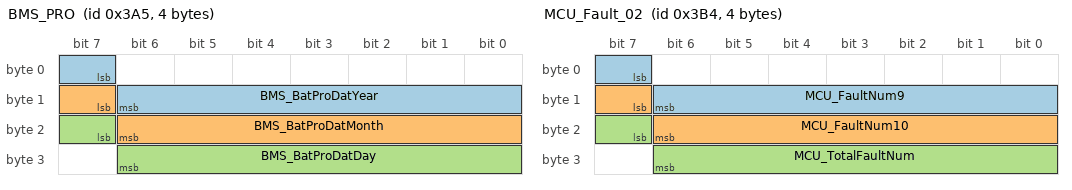
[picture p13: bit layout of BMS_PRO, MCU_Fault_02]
BO_ 933 BMS_PRO: 4 CGW_SG
 SG_ BMS_BatProDatYear : 7|8@1+ (1,0) [0|1] ""  SGW_SG
 SG_ BMS_BatProDatMonth : 15|8@1+ (1,0) [0|1] ""  SGW_SG
 SG_ BMS_BatProDatDay : 23|8@1+ (1,0) [0|1] ""  SGW_SG

BO_ 934 BMS_BatInfor_01: 9 CGW_SG
 SG_ BMS_BatType : 7|8@1+ (1,0) [0|255] ""  CGW_SG
 SG_ BMS_CellNumbers : 15|8@1+ (1,0) [0|255] ""  SGW_SG
 SG_ BMS_RatCapacity : 23|16@1+ (0,0) [0|6553] "Ah"  CGW_SG
 SG_ BMS_RatEnergy : 39|16@1+ (0,0) [0|6553] "KWH"  CGW_SG
 SG_ BMS_RatBatVoltage : 55|16@1+ (0,0) [0|6553] "V"  CGW_SG

BO_ 945 SGW_OdometerInfor_02: 6 SGW_SG
 SG_ SGW_OdometerInfor : 23|24@1+ (0,0) [0|999999] ""  CGW_SG
 SG_ SGW_OdometerInforValid : 47|1@1+ (1,0) [0|1] ""  CGW_SG

BO_ 946 SGW_OdometerInfor_03: 9 SGW_SG
 SG_ SGW_VIN : 7|64@1+ (1,0) [0|6510615555426899968] ""  CGW_SG

BO_ 947 MCU_Fault_01: 9 CGW_SG
 SG_ MCU_FaultNum1 : 7|8@1+ (1,0) [0|255] ""  SGW_SG
 SG_ MCU_FaultNum2 : 15|8@1+ (1,0) [0|255] ""  SGW_SG
 SG_ MCU_FaultNum3 : 23|8@1+ (1,0) [0|255] ""  SGW_SG
 SG_ MCU_FaultNum4 : 31|8@1+ (1,0) [0|255] ""  SGW_SG
 SG_ MCU_FaultNum5 : 39|8@1+ (1,0) [0|255] ""  SGW_SG
 SG_ MCU_FaultNum6 : 47|8@1+ (1,0) [0|255] ""  SGW_SG
 SG_ MCU_FaultNum7 : 55|8@1+ (1,0) [0|255] ""  SGW_SG
 SG_ MCU_FaultNum8 : 63|8@1+ (1,0) [0|255] ""  SGW_SG

BO_ 948 MCU_Fault_02: 4 CGW_SG
 SG_ MCU_FaultNum9 : 7|8@1+ (1,0) [0|255] ""  SGW_SG
 SG_ MCU_FaultNum10 : 15|8@1+ (1,0) [0|255] ""  SGW_SG
 SG_ MCU_TotalFaultNum : 23|8@1+ (1,0) [0|255] ""  SGW_SG

BO_ 960 SGW_FVSynchronization_01: 9 SGW_SG
 SG_ SGW_TripCounter : 7|24@1+ (1,0) [0|16777215] ""  CGW_SG
 SG_ SGW_ResetCounter : 31|16@1+ (1,0) [0|65535] ""  CGW_SG
 SG_ SGW_SynMsgAuthenticator : 47|24@1+ (1,0) [0|16777215] ""  CGW_SG

BO_ 992 BMS_SGW_01: 6 CGW_SG
 SG_ BMS_FeedEnergySts : 7|17@1+ (0,0) [0|9999] ""  SGW_SG
 SG_ BMS_DirveDiscSts : 31|17@1+ (0,0) [0|9999] ""  SGW_SG

BO_ 1025 BCM1_DiagInfor: 2 CGW_SG
 SG_ BCM1_DTC_Number : 7|8@1+ (1,0) [0|255] ""  SGW_SG

BO_ 1026 CGW_DiagInfor: 2 CGW_SG
 SG_ CGW_DTC_Number : 7|8@1+ (1,0) [0|255] ""  SGW_SG

BO_ 1027 SGW_DiagInfor: 2 SGW_SG
 SG_ SGW_DTC_Number : 7|8@1+ (1,0) [0|255] ""  CGW_SG

BO_ 1029 ERA_DiagInfor: 2 SGW_SG
 SG_ ERA_DTC_Number : 7|8@1+ (1,0) [0|255] ""  CGW_SG

BO_ 1030 Switches_DiagInfor: 2 CGW_SG
 SG_ Switches_DTC_Number : 7|8@1+ (1,0) [0|255] ""  SGW_SG

BO_ 1031 SWP_DiagInfor: 2 CGW_SG
 SG_ SWP_DTC_Number : 7|8@1+ (1,0) [0|255] ""  SGW_SG

BO_ 1032 NDT_DiagInfor: 2 CGW_SG
 SG_ NDT_DTC_Number : 7|8@1+ (1,0) [0|255] ""  SGW_SG

BO_ 1033 HOD_heating_DiagInfor: 2 CGW_SG
 SG_ HOD_heating_DTC_Number : 7|8@1+ (1,0) [0|255] ""  SGW_SG

BO_ 1034 CBM_DiagInfor: 2 SGW_SG
 SG_ CBM_DTC_Number : 7|8@1+ (1,0) [0|255] ""  CGW_SG

BO_ 1037 HUD_DiagInfor: 2 CGW_SG
 SG_ HUD_DTC_Number : 7|8@1+ (1,0) [0|255] ""  SGW_SG

BO_ 1038 DIM_DiagInfor: 2 CGW_SG
 SG_ DIM_DTC_Number : 7|8@1+ (1,0) [0|255] ""  SGW_SG

BO_ 1043 BMS_DiagInfor: 2 CGW_SG
 SG_ BMS_DTC_Number : 7|8@1+ (1,0) [0|255] ""  SGW_SG

BO_ 1046 MFP_FC_DiagInfor: 2 CGW_SG
 SG_ MFP_FC_DTC_Number : 7|8@1+ (1,0) [0|255] ""  SGW_SG

BO_ 1049 MFP_RC_DiagInfor: 2 CGW_SG
 SG_ MFP_RC_DTC_Number : 7|8@1+ (1,0) [0|255] ""  SGW_SG

BO_ 1050 BCM2_DiagInfor: 2 CGW_SG
 SG_ BCM2_DTC_Number : 7|8@1+ (1,0) [0|255] ""  SGW_SG

BO_ 1051 SCUL_DiagInfor: 2 CGW_SG
 SG_ SCUL_DTC_Number : 7|8@1+ (1,0) [0|255] ""  SGW_SG

BO_ 1052 SCUR_DiagInfor: 2 CGW_SG
 SG_ SCUR_DTC_Number : 7|8@1+ (1,0) [0|255] ""  SGW_SG

BO_ 1053 HLL_DiagInfor: 2 CGW_SG
 SG_ HLL_DTC_Number : 7|8@1+ (1,0) [0|255] ""  SGW_SG

BO_ 1055 WCBS1_DiagInfor: 2 CGW_SG
 SG_ WCBS1_DTC_Number : 7|8@1+ (1,0) [0|255] ""  SGW_SG

BO_ 1056 WCBS2_DiagInfor: 2 CGW_SG
 SG_ WCBS2_DTC_Number : 7|8@1+ (1,0) [0|255] ""  SGW_SG

BO_ 1062 IBS_DiagInfor: 2 CGW_SG
 SG_ IBS_DTC_Number : 7|8@1+ (1,0) [0|255] ""  SGW_SG

BO_ 1065 EPS_DiagInfor: 2 CGW_SG
 SG_ EPS_DTC_Number : 7|8@1+ (1,0) [0|255] ""  SGW_SG

BO_ 1067 PAT_DiagInfor: 2 CGW_SG
 SG_ PAT_DTC_Number : 7|8@1+ (1,0) [0|255] ""  SGW_SG

BO_ 1068 VCU_DiagInfor: 2 CGW_SG
 SG_ VCU_DTC_Number : 7|8@1+ (1,0) [0|255] ""  SGW_SG

BO_ 1071 DCM_FL_DiagInfor: 2 CGW_SG
 SG_ DCM_FL_DTC_Number : 7|8@1+ (1,0) [0|255] ""  SGW_SG

BO_ 1079 DCM_RL_DiagInfor: 2 CGW_SG
 SG_ DCM_RL_DTC_Number : 7|8@1+ (1,0) [0|255] ""  SGW_SG

BO_ 1083 DCM_FR_DiagInfor: 2 CGW_SG
 SG_ DCM_FR_DTC_Number : 7|8@1+ (1,0) [0|255] ""  SGW_SG

BO_ 1084 DCM_RR_DiagInfor: 2 CGW_SG
 SG_ DCM_RR_DTC_Number : 7|8@1+ (1,0) [0|255] ""  SGW_SG

BO_ 1086 HLR_DiagInfor: 2 CGW_SG
 SG_ HLR_DTC_Number : 7|8@1+ (1,0) [0|255] ""  SGW_SG

BO_ 1088 ADCU_DiagInfor: 2 CGW_SG
 SG_ ADCU_DTC_Number : 7|8@1+ (1,0) [0|255] ""  SGW_SG

BO_ 1090 MCU_DiagInfor: 2 CGW_SG
 SG_ MCU_DTC_Number : 7|8@1+ (1,0) [0|255] ""  SGW_SG

BO_ 1091 AVAS_DiagInfor: 2 CGW_SG
 SG_ AVAS_DTC_Number : 7|8@1+ (1,0) [0|255] ""  SGW_SG

BO_ 1092 IVI_DiagInfor: 2 CGW_SG
 SG_ IVI_DTC_Number : 7|8@1+ (1,0) [0|255] ""  SGW_SG

BO_ 1095 POD_DiagInfor: 2 CGW_SG
 SG_ POD_DTC_Number : 7|8@1+ (1,0) [0|255] ""  SGW_SG

BO_ 1096 TCU_DiagInfor: 2 CGW_SG
 SG_ TCU_DTC_Number : 7|8@1+ (1,0) [0|255] ""  SGW_SG

BO_ 1097 EVCOM_DiagInfor: 2 CGW_SG
 SG_ EVCOM_DTC_Number : 7|8@1+ (1,0) [0|255] ""  SGW_SG

BO_ 1102 APTC_DiagInfor: 2 CGW_SG
 SG_ AIRPTC_DTC_Number : 7|8@1+ (1,0) [0|255] ""  SGW_SG

BO_ 1103 PRND_DiagInfor: 2 CGW_SG
 SG_ PRND_DTC_Number : 7|8@1+ (1,0) [0|255] ""  SGW_SG

BO_ 1273 ACU_DiagInfor: 2 CGW_SG
 SG_ ACU_DTC_Number : 7|8@1+ (1,0) [0|255] ""  SGW_SG

BO_ 1282 NM_CGW: 8 CGW_SG
 SG_ CGW_RMR : 8|1@1+ (1,0) [0|1] ""  SGW_SG
 SG_ CGW_AWB : 12|1@1+ (1,0) [0|1] ""  SGW_SG
 SG_ CGW_PNI : 14|1@1+ (1,0) [0|1] ""  SGW_SG
 SG_ CGW_PNC0 : 24|1@1+ (1,0) [0|1] ""  SGW_SG
 SG_ CGW_PNC1 : 25|1@1+ (1,0) [0|1] ""  SGW_SG
 SG_ CGW_PNC2 : 26|1@1+ (1,0) [0|1] ""  SGW_SG
 SG_ CGW_PNC3 : 27|1@1+ (1,0) [0|1] ""  SGW_SG
 SG_ CGW_PNC4 : 28|1@1+ (1,0) [0|1] ""  SGW_SG
 SG_ CGW_PNC5 : 29|1@1+ (1,0) [0|1] ""  SGW_SG
 SG_ CGW_PNC6 : 30|1@1+ (1,0) [0|1] ""  SGW_SG
 SG_ CGW_PNC7 : 31|1@1+ (1,0) [0|1] ""  SGW_SG
 SG_ CGW_PNC8 : 32|1@1+ (1,0) [0|1] ""  SGW_SG
 SG_ CGW_PNC9 : 33|1@1+ (1,0) [0|1] ""  SGW_SG
 SG_ CGW_PNC10 : 34|1@1+ (1,0) [0|1] ""  SGW_SG
 SG_ CGW_PNC11 : 35|1@1+ (1,0) [0|1] ""  SGW_SG
 SG_ CGW_PNC12 : 36|1@1+ (1,0) [0|1] ""  SGW_SG
 SG_ CGW_PNC13 : 37|1@1+ (1,0) [0|1] ""  SGW_SG
 SG_ CGW_PNC14 : 38|1@1+ (1,0) [0|1] ""  SGW_SG
 SG_ CGW_PNC15 : 39|1@1+ (1,0) [0|1] ""  SGW_SG
 SG_ CGW_PNC16 : 40|1@1+ (1,0) [0|1] ""  SGW_SG
 SG_ CGW_PNC17 : 41|1@1+ (1,0) [0|1] ""  SGW_SG
 SG_ CGW_PNC18 : 42|1@1+ (1,0) [0|1] ""  SGW_SG
 SG_ CGW_PNC19 : 43|1@1+ (1,0) [0|1] ""  SGW_SG
 SG_ CGW_PNC20 : 44|1@1+ (1,0) [0|1] ""  SGW_SG
 SG_ CGW_PNC21 : 45|1@1+ (1,0) [0|1] ""  SGW_SG
 SG_ CGW_PNC22 : 46|1@1+ (1,0) [0|1] ""  SGW_SG
 SG_ CGW_PNC23 : 47|1@1+ (1,0) [0|1] ""  SGW_SG
 SG_ CGW_PNC24 : 48|1@1+ (1,0) [0|1] ""  SGW_SG
 SG_ CGW_PNC25 : 49|1@1+ (1,0) [0|1] ""  SGW_SG
 SG_ CGW_PNC26 : 50|1@1+ (1,0) [0|1] ""  SGW_SG
 SG_ CGW_PNC27 : 51|1@1+ (1,0) [0|1] ""  SGW_SG
 SG_ CGW_PNC28 : 52|1@1+ (1,0) [0|1] ""  SGW_SG
 SG_ CGW_PNC29 : 53|1@1+ (1,0) [0|1] ""  SGW_SG
 SG_ CGW_PNC30 : 54|1@1+ (1,0) [0|1] ""  SGW_SG
 SG_ CGW_PNC31 : 55|1@1+ (1,0) [0|1] ""  SGW_SG
 SG_ CGW_PNC32 : 56|1@1+ (1,0) [0|1] ""  SGW_SG
 SG_ CGW_PNC33 : 57|1@1+ (1,0) [0|1] ""  SGW_SG
 SG_ CGW_PNC34 : 58|1@1+ (1,0) [0|1] ""  SGW_SG
 SG_ CGW_PNC35 : 59|1@1+ (1,0) [0|1] ""  SGW_SG
 SG_ CGW_PNC36 : 60|1@1+ (1,0) [0|1] ""  SGW_SG
 SG_ CGW_PNC37 : 61|1@1+ (1,0) [0|1] ""  SGW_SG
 SG_ CGW_PNC38 : 62|1@1+ (1,0) [0|1] ""  SGW_SG
 SG_ CGW_PNC39 : 63|1@1+ (1,0) [0|1] ""  SGW_SG

BO_ 1283 NM_SGW: 8 SGW_SG
 SG_ SGW_RMR : 8|1@1+ (1,0) [0|1] ""  CGW_SG
 SG_ SGW_AWB : 12|1@1+ (1,0) [0|1] ""  CGW_SG
 SG_ SGW_PNI : 14|1@1+ (1,0) [0|1] ""  CGW_SG
 SG_ SGW_PNC0 : 24|1@1+ (1,0) [0|1] ""  CGW_SG
 SG_ SGW_PNC1 : 25|1@1+ (1,0) [0|1] ""  CGW_SG
 SG_ SGW_PNC2 : 26|1@1+ (1,0) [0|1] ""  CGW_SG
 SG_ SGW_PNC3 : 27|1@1+ (1,0) [0|1] ""  CGW_SG
 SG_ SGW_PNC4 : 28|1@1+ (1,0) [0|1] ""  CGW_SG
 SG_ SGW_PNC5 : 29|1@1+ (1,0) [0|1] ""  CGW_SG
 SG_ SGW_PNC6 : 30|1@1+ (1,0) [0|1] ""  CGW_SG
 SG_ SGW_PNC7 : 31|1@1+ (1,0) [0|1] ""  CGW_SG
 SG_ SGW_PNC8 : 32|1@1+ (1,0) [0|1] ""  CGW_SG
 SG_ SGW_PNC9 : 33|1@1+ (1,0) [0|1] ""  CGW_SG
 SG_ SGW_PNC10 : 34|1@1+ (1,0) [0|1] ""  CGW_SG
 SG_ SGW_PNC11 : 35|1@1+ (1,0) [0|1] ""  CGW_SG
 SG_ SGW_PNC12 : 36|1@1+ (1,0) [0|1] ""  CGW_SG
 SG_ SGW_PNC13 : 37|1@1+ (1,0) [0|1] ""  CGW_SG
 SG_ SGW_PNC14 : 38|1@1+ (1,0) [0|1] ""  CGW_SG
 SG_ SGW_PNC15 : 39|1@1+ (1,0) [0|1] ""  CGW_SG
 SG_ SGW_PNC16 : 40|1@1+ (1,0) [0|1] ""  CGW_SG
 SG_ SGW_PNC17 : 41|1@1+ (1,0) [0|1] ""  CGW_SG
 SG_ SGW_PNC18 : 42|1@1+ (1,0) [0|1] ""  CGW_SG
 SG_ SGW_PNC19 : 43|1@1+ (1,0) [0|1] ""  CGW_SG
 SG_ SGW_PNC20 : 44|1@1+ (1,0) [0|1] ""  CGW_SG
 SG_ SGW_PNC21 : 45|1@1+ (1,0) [0|1] ""  CGW_SG
 SG_ SGW_PNC22 : 46|1@1+ (1,0) [0|1] ""  CGW_SG
 SG_ SGW_PNC23 : 47|1@1+ (1,0) [0|1] ""  CGW_SG
 SG_ SGW_PNC24 : 48|1@1+ (1,0) [0|1] ""  CGW_SG
 SG_ SGW_PNC25 : 49|1@1+ (1,0) [0|1] ""  CGW_SG
 SG_ SGW_PNC26 : 50|1@1+ (1,0) [0|1] ""  CGW_SG
 SG_ SGW_PNC27 : 51|1@1+ (1,0) [0|1] ""  CGW_SG
 SG_ SGW_PNC28 : 52|1@1+ (1,0) [0|1] ""  CGW_SG
 SG_ SGW_PNC29 : 53|1@1+ (1,0) [0|1] ""  CGW_SG
 SG_ SGW_PNC30 : 54|1@1+ (1,0) [0|1] ""  CGW_SG
 SG_ SGW_PNC31 : 55|1@1+ (1,0) [0|1] ""  CGW_SG
 SG_ SGW_PNC32 : 56|1@1+ (1,0) [0|1] ""  CGW_SG
 SG_ SGW_PNC33 : 57|1@1+ (1,0) [0|1] ""  CGW_SG
 SG_ SGW_PNC34 : 58|1@1+ (1,0) [0|1] ""  CGW_SG
 SG_ SGW_PNC35 : 59|1@1+ (1,0) [0|1] ""  CGW_SG
 SG_ SGW_PNC36 : 60|1@1+ (1,0) [0|1] ""  CGW_SG
 SG_ SGW_PNC37 : 61|1@1+ (1,0) [0|1] ""  CGW_SG
 SG_ SGW_PNC38 : 62|1@1+ (1,0) [0|1] ""  CGW_SG
 SG_ SGW_PNC39 : 63|1@1+ (1,0) [0|1] ""  CGW_SG

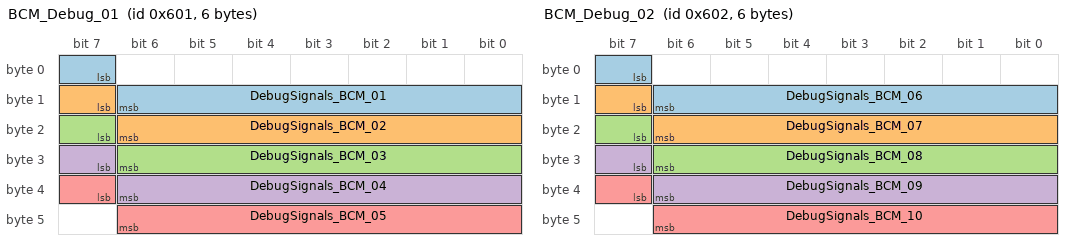
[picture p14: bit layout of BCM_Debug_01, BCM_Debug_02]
BO_ 1537 BCM_Debug_01: 6 CGW_SG
 SG_ DebugSignals_BCM_01 : 7|8@1+ (1,0) [0|255] ""  SGW_SG
 SG_ DebugSignals_BCM_02 : 15|8@1+ (1,0) [0|255] ""  SGW_SG
 SG_ DebugSignals_BCM_03 : 23|8@1+ (1,0) [0|255] ""  SGW_SG
 SG_ DebugSignals_BCM_04 : 31|8@1+ (1,0) [0|255] ""  SGW_SG
 SG_ DebugSignals_BCM_05 : 39|8@1+ (1,0) [0|255] ""  SGW_SG

BO_ 1538 BCM_Debug_02: 6 CGW_SG
 SG_ DebugSignals_BCM_06 : 7|8@1+ (1,0) [0|255] ""  SGW_SG
 SG_ DebugSignals_BCM_07 : 15|8@1+ (1,0) [0|255] ""  SGW_SG
 SG_ DebugSignals_BCM_08 : 23|8@1+ (1,0) [0|255] ""  SGW_SG
 SG_ DebugSignals_BCM_09 : 31|8@1+ (1,0) [0|255] ""  SGW_SG
 SG_ DebugSignals_BCM_10 : 39|8@1+ (1,0) [0|255] ""  SGW_SG

BO_ 1793 DiagResp_BCM1: 9 CGW_SG
 SG_ BCM1_DiagResp : 7|64@1+ (1,0) [0|1] ""  SGW_SG

BO_ 1794 DiagResp_CGW: 9 CGW_SG
 SG_ CGW_DiagResp : 7|64@1+ (1,0) [0|1] ""  SGW_SG

BO_ 1796 DiagResp_IVI: 9 CGW_SG
 SG_ IVI_DiagResp : 7|64@1+ (1,0) [0|1] ""  SGW_SG

BO_ 1798 DiagResp_Switches: 9 CGW_SG
 SG_ Switches_DiagResp : 7|64@1+ (1,0) [0|1] ""  SGW_SG

BO_ 1799 DiagResp_SWP: 9 CGW_SG
 SG_ SWP_DiagResp : 7|64@1+ (1,0) [0|1] ""  SGW_SG

BO_ 1800 DiagResp_NDT: 9 CGW_SG
 SG_ NDT_DiagResp : 7|64@1+ (1,0) [0|1] ""  SGW_SG

BO_ 1801 DiagResp_HOD_heating: 9 CGW_SG
 SG_ HOD_heating_DiagResp : 7|64@1+ (1,0) [0|1] ""  SGW_SG

BO_ 1805 DiagResp_HUD: 9 CGW_SG
 SG_ HUD_DiagResp : 7|64@1+ (1,0) [0|1] ""  SGW_SG

BO_ 1806 DiagResp_DIM: 9 CGW_SG
 SG_ DIM_DiagResp : 7|64@1+ (1,0) [0|1] ""  SGW_SG

BO_ 1811 DiagResp_BMS: 9 CGW_SG
 SG_ BMS_DiagResp : 7|64@1+ (1,0) [0|1] ""  SGW_SG

BO_ 1812 DiagResp_Switches2: 9 CGW_SG
 SG_ Switches2_DiagResp : 7|64@1+ (1,0) [0|1] ""  SGW_SG

BO_ 1814 DiagResp_MFP_FC: 9 CGW_SG
 SG_ MFP_FC_DiagResp : 7|64@1+ (1,0) [0|1] ""  SGW_SG

BO_ 1817 DiagResp_MFP_RC: 9 CGW_SG
 SG_ MFP_RC_DiagResp : 7|64@1+ (1,0) [0|1] ""  SGW_SG

BO_ 1818 DiagResp_BCM2: 9 CGW_SG
 SG_ BCM2_DiagResp : 7|64@1+ (1,0) [0|1] ""  SGW_SG

BO_ 1819 DiagResp_SCUL: 9 CGW_SG
 SG_ SCUL_DiagResp : 7|64@1+ (1,0) [0|1] ""  SGW_SG

BO_ 1820 DiagResp_SCUR: 9 CGW_SG
 SG_ SCUR_DiagResp : 7|64@1+ (1,0) [0|1] ""  SGW_SG

BO_ 1821 DiagResp_HLL: 9 CGW_SG
 SG_ HLL_DiagResp : 7|64@1+ (1,0) [0|1] ""  SGW_SG

BO_ 1822 DiagResp_HLR: 9 CGW_SG
 SG_ HLR_DiagResp : 7|64@1+ (1,0) [0|1] ""  SGW_SG

BO_ 1823 DiagResp_WCBS1: 9 CGW_SG
 SG_ WCBS1_DiagResp : 7|64@1+ (1,0) [0|1] ""  SGW_SG

BO_ 1824 DiagResp_WCBS2: 9 CGW_SG
 SG_ WCBS2_DiagResp : 7|64@1+ (1,0) [0|1] ""  SGW_SG

BO_ 1830 DiagResp_IBS: 9 CGW_SG
 SG_ IBS_DiagResp : 7|64@1+ (1,0) [0|1] ""  SGW_SG

BO_ 1833 DiagResp_EPS: 9 CGW_SG
 SG_ EPS_DiagResp : 7|64@1+ (1,0) [0|1] ""  SGW_SG

BO_ 1835 DiagResp_PAT: 9 CGW_SG
 SG_ PAT_DiagResp : 7|64@1+ (1,0) [0|1] ""  SGW_SG

BO_ 1836 DiagResp_VCU: 9 CGW_SG
 SG_ VCU_DiagResp : 7|64@1+ (1,0) [0|1] ""  SGW_SG

BO_ 1839 DiagResp_DCM_FL: 9 CGW_SG
 SG_ DCM_FL_DiagResp : 7|64@1+ (1,0) [0|1] ""  SGW_SG

BO_ 1843 DiagReq_OBD: 9 SGW_SG
 SG_ OBD_DiagReq : 7|64@1+ (1,0) [0|1] ""  CGW_SG

BO_ 1847 DiagResp_DCM_FR: 9 CGW_SG
 SG_ DCM_FR_DiagResp : 7|64@1+ (1,0) [0|1] ""  SGW_SG

BO_ 1851 DiagResp_DCM_RL: 9 CGW_SG
 SG_ DCM_RL_DiagResp : 7|64@1+ (1,0) [0|1] ""  SGW_SG

BO_ 1852 DiagResp_DCM_RR: 9 CGW_SG
 SG_ DCM_RR_DiagResp : 7|64@1+ (1,0) [0|1] ""  SGW_SG

BO_ 1856 DiagResp_ADCU: 9 CGW_SG
 SG_ ADCU_DiagResp : 7|64@1+ (1,0) [0|1] ""  SGW_SG

BO_ 1858 DiagResp_MCU: 9 CGW_SG
 SG_ MCU_DiagResp : 7|64@1+ (1,0) [0|1] ""  SGW_SG

BO_ 1859 DiagResp_AVAS: 9 CGW_SG
 SG_ AVAS_DiagResp : 7|64@1+ (1,0) [0|1] ""  SGW_SG

BO_ 1863 DiagResp_POD: 9 CGW_SG
 SG_ POD_DiagResp : 7|64@1+ (1,0) [0|1] ""  SGW_SG

BO_ 1864 DiagResp_TCU: 9 CGW_SG
 SG_ TCU_DiagResp : 7|64@1+ (1,0) [0|1] ""  SGW_SG

BO_ 1865 DiagResp_EVCOM: 9 CGW_SG
 SG_ EVCOM_DiagResp : 7|64@1+ (1,0) [0|1] ""  SGW_SG

BO_ 1870 DiagResp_APTC: 9 CGW_SG
 SG_ AIRPTC_DiagResp : 7|64@1+ (1,0) [0|1] ""  SGW_SG

BO_ 1871 DiagResp_PRND: 9 CGW_SG
 SG_ PRND_DiagResp : 7|64@1+ (1,0) [0|1] ""  SGW_SG

BO_ 1921 DiagReq_BCM1: 9 SGW_SG
 SG_ BCM1_DiagReq : 7|64@1+ (1,0) [0|1] ""  CGW_SG

BO_ 1922 DiagReq_CGW: 9 SGW_SG
 SG_ CGW_DiagReq : 7|64@1+ (1,0) [0|1] ""  CGW_SG

BO_ 1924 DiagReq_IVI: 9 SGW_SG
 SG_ IVI_DiagReq : 7|64@1+ (1,0) [0|1] ""  CGW_SG

BO_ 1926 DiagReq_Switches: 9 SGW_SG
 SG_ Switches_DiagReq : 7|64@1+ (1,0) [0|1] ""  CGW_SG

BO_ 1927 DiagReq_SWP: 9 SGW_SG
 SG_ SWP_DiagReq : 7|64@1+ (1,0) [0|1] ""  CGW_SG

BO_ 1928 DiagReq_NDT: 9 SGW_SG
 SG_ NDT_DiagReq : 7|64@1+ (1,0) [0|1] ""  CGW_SG

BO_ 1929 DiagReq_HOD_heating: 9 SGW_SG
 SG_ HOD_heating_DiagReq : 7|64@1+ (1,0) [0|1] ""  CGW_SG

BO_ 1933 DiagReq_HUD: 9 SGW_SG
 SG_ HUD_DiagReq : 7|64@1+ (1,0) [0|1] ""  CGW_SG

BO_ 1934 DiagReq_DIM: 9 SGW_SG
 SG_ DIM_DiagReq : 7|64@1+ (1,0) [0|1] ""  CGW_SG

BO_ 1939 DiagReq_BMS: 9 SGW_SG
 SG_ BMS_DiagReq : 7|64@1+ (1,0) [0|1] ""  CGW_SG

BO_ 1940 DiagReq_Switches2: 9 SGW_SG
 SG_ Switches2_DiagReq : 7|64@1+ (1,0) [0|1] ""  CGW_SG

BO_ 1942 DiagReq_MFP_FC: 9 SGW_SG
 SG_ MFP_FC_DiagReq : 7|64@1+ (1,0) [0|1] ""  CGW_SG

BO_ 1945 DiagReq_MFP_RC: 9 SGW_SG
 SG_ MFP_RC_DiagReq : 7|64@1+ (1,0) [0|1] ""  CGW_SG

BO_ 1946 DiagReq_BCM2: 9 SGW_SG
 SG_ BCM2_DiagReq : 7|64@1+ (1,0) [0|1] ""  CGW_SG

BO_ 1947 DiagReq_SCUL: 9 SGW_SG
 SG_ SCUL_DiagReq : 7|64@1+ (1,0) [0|1] ""  CGW_SG

BO_ 1948 DiagReq_SCUR: 9 SGW_SG
 SG_ SCUR_DiagReq : 7|64@1+ (1,0) [0|1] ""  CGW_SG

BO_ 1949 DiagReq_HLL: 9 SGW_SG
 SG_ HLL_DiagReq : 7|64@1+ (1,0) [0|1] ""  CGW_SG

BO_ 1950 DiagReq_HLR: 9 SGW_SG
 SG_ HLR_DiagReq : 7|64@1+ (1,0) [0|1] ""  CGW_SG

BO_ 1951 DiagReq_WCBS_01: 9 SGW_SG
 SG_ WCBS1_DiagReq : 7|64@1+ (1,0) [0|1] ""  CGW_SG

BO_ 1952 DiagReq_WCBS_02: 9 SGW_SG
 SG_ WCBS2_DiagReq : 7|64@1+ (1,0) [0|1] ""  CGW_SG

BO_ 1958 DiagReq_IBS: 9 SGW_SG
 SG_ IBS_DiagReq : 7|64@1+ (1,0) [0|1] ""  CGW_SG

BO_ 1961 DiagReq_EPS: 9 SGW_SG
 SG_ EPS_DiagReq : 7|64@1+ (1,0) [0|1] ""  CGW_SG

BO_ 1963 DiagReq_PAT: 9 SGW_SG
 SG_ PAT_DiagReq : 7|64@1+ (1,0) [0|1] ""  CGW_SG

BO_ 1964 DiagReq_VCU: 9 SGW_SG
 SG_ VCU_DiagReq : 7|64@1+ (1,0) [0|1] ""  CGW_SG

BO_ 1967 DiagReq_DCM_FL: 9 SGW_SG
 SG_ DCM_FL_DiagReq : 7|64@1+ (1,0) [0|1] ""  CGW_SG

BO_ 1975 DiagReq_DCM_FR: 9 SGW_SG
 SG_ DCM_FR_DiagReq : 7|64@1+ (1,0) [0|1] ""  CGW_SG

BO_ 1979 DiagReq_DCM_RL: 9 SGW_SG
 SG_ DCM_RL_DiagReq : 7|64@1+ (1,0) [0|1] ""  CGW_SG

BO_ 1980 DiagReq_DCM_RR: 9 SGW_SG
 SG_ DCM_RR_DiagReq : 7|64@1+ (1,0) [0|1] ""  CGW_SG

BO_ 1984 DiagReq_ADCU: 9 SGW_SG
 SG_ ADCU_DiagReq : 7|64@1+ (1,0) [0|1] ""  CGW_SG

BO_ 1986 DiagReq_MCU: 9 SGW_SG
 SG_ MCU_DiagReq : 7|64@1+ (1,0) [0|1] ""  CGW_SG

BO_ 1987 DiagReq_AVAS: 9 SGW_SG
 SG_ AVAS_DiagReq : 7|64@1+ (1,0) [0|1] ""  CGW_SG

BO_ 1991 DiagReq_POD: 9 SGW_SG
 SG_ POD_DiagReq : 7|64@1+ (1,0) [0|1] ""  CGW_SG

BO_ 1992 DiagReq_TCU: 9 SGW_SG
 SG_ TCU_DiagReq : 7|64@1+ (1,0) [0|1] ""  CGW_SG

BO_ 1993 DiagReq_EVCOM: 9 SGW_SG
 SG_ EVCOM_DiagReq : 7|64@1+ (1,0) [0|1] ""  CGW_SG

BO_ 1998 DiagReq_AIRPTC: 9 SGW_SG
 SG_ AIRPTC_DiagReq : 7|64@1+ (1,0) [0|1] ""  CGW_SG

BO_ 1999 DiagReq_PRND: 9 SGW_SG
 SG_ PRND_DiagReq : 7|64@1+ (1,0) [0|1] ""  CGW_SG

BO_ 2015 DiagReq_FUN: 9 SGW_SG
 SG_ FUN_DiagReq : 7|64@1+ (1,0) [0|1] ""  CGW_SG

BO_ 2016 DiagReq_VCU_OBD: 9 SGW_SG
 SG_ VCU_OBD_DiagReq : 7|64@1+ (1,0) [0|1] ""  CGW_SG

BO_ 2024 DiagResp_VCU_OBD: 9 CGW_SG
 SG_ VCU_OBD_DiagResp : 7|64@1+ (1,0) [0|1] ""  SGW_SG

BO_ 2025 DiagReq_BD: 9 SGW_SG
 SG_ BD_DiagReq : 7|64@1+ (1,0) [0|1] ""  CGW_SG

BO_ 2026 DiagReq_PT: 9 SGW_SG
 SG_ PT_DiagReq : 7|64@1+ (1,0) [0|1] ""  CGW_SG

BO_ 2027 DiagReq_CH: 9 SGW_SG
 SG_ CH_DiagReq : 7|64@1+ (1,0) [0|1] ""  CGW_SG

BO_ 2029 DiagReq_ET: 9 SGW_SG
 SG_ ET_DiagReq : 7|64@1+ (1,0) [0|1] ""  CGW_SG

BO_ 2033 DiagReq_ACU: 9 SGW_SG
 SG_ ACU_DiagReq : 7|64@1+ (1,0) [0|1] ""  CGW_SG

BO_ 2041 DiagResp_ACU: 9 CGW_SG
 SG_ ACU_DiagResp : 7|64@1+ (1,0) [0|1] ""  SGW_SG

BO_ 2047 DiagReq_ALL: 9 SGW_SG
 SG_ ALL_DiagReq : 7|64@1+ (1,0) [0|1] ""  CGW_SG

CM_ SG_ 150 VCU_MCUActHeatPwr "Desired heating power of electric machine";
CM_ SG_ 150 VCU_MaxSpdLimit "Upper limit output speed of electric machine";
CM_ SG_ 150 VCU_MotorSpdReq "Desired speed electric machine";
CM_ SG_ 194 BMS_Heatcurrent "Heat current";
CM_ SG_ 194 BMS_BattCurr "the current of dclink from BMS side";
CM_ SG_ 194 BMS_BattVolt "the voltage of dclink from BMS side";
CM_ SG_ 257 CBM_BLE_CarSearchReq "Bluetooth remote search request";
CM_ SG_ 259 IVI_DrSeatWelcomeLevelSet "Driver Seat welcome position level setting";
CM_ SG_ 259 IVI_DrSeatHeatLevelSet "Driver seat heating level setting signal";
CM_ SG_ 259 IVI_L_DsSeatSlidePos "Driver seat slide percentage request";
CM_ SG_ 259 IVI_L_DsSeatHeightPos "Driver seat height percentage request";
CM_ SG_ 259 IVI_L_DsSeatBackPos "Driver seat backrest percentage request";
CM_ SG_ 260 IVI_PsSeatWelcomeLevelSet "Passenger Seat welcome position level setting";
CM_ SG_ 260 IVI_PassSeatHeatLevelSet "passenger seat heating control signal";
CM_ SG_ 260 IVI_R_DsSeatBackPos "Passenger seat backrest percentage request";
CM_ SG_ 260 IVI_R_DsSeatHeightPos "Passenger seat height percentage request";
CM_ SG_ 260 IVI_R_DsSeatSlidePos "Passenger seat slide percentage request";
CM_ SG_ 262 IVI_HUDScreenBrightnessSet "Set HUD Screen backlight brightness";
CM_ SG_ 264 SGW_FR_FrontRearReq "Passenger forward and backward request";
CM_ SG_ 264 SGW_FR_HeightMotorReq "Passenger height request";
CM_ SG_ 264 SGW_FR_BackrestMotorReq "Passenger backrest request";
CM_ SG_ 267 BCM_CentralLockFeedback "Feedback of the central locking or unlocking result";
CM_ SG_ 267 BCM_LVonReqKeyNotInCar "DK is not in the car when powered on";
CM_ SG_ 268 SGW_SecOCMAC_10C "Message authentication code";
CM_ SG_ 268 SGW_SecOCFV_10C "Freshness value";
CM_ SG_ 268 SGW_PENFCAuthSt "NFC authorizes state event";
CM_ SG_ 268 SGW_GetNFCKeyCardsReq "SGW get all NFC ket card info request";
CM_ SG_ 268 SGW_NFCPairModeReq "NFC Paring mode Request";
CM_ SG_ 271 Switches_L_SWipe_Cmd "Left sliding signal of steering wheel";
CM_ SG_ 289 VCU_OBC_ChargeCurrentCommand "OBC output charging current according to this signal.";
CM_ SG_ 289 VCU_Enable_DC_Relay "enable: Request for closing DC charging relay";
CM_ SG_ 289 VCU_OBC_Control_of_S2_SW "OBC should accept the control signal from VCU to switch the S2 inside the OBC";
CM_ SG_ 289 VCU_OBC_Control_of_em_lock "OBC should accept the control signal from VCU to lock or unlock the actuator in the Inlet for locking or unlocking the charging plug";
CM_ SG_ 289 VCU_EnableOBC "When VCU receiving OBC Charge Status= Ready and detecting the status of S2 is closed,VCU send enable
When VCU detect that the stop charging condition is met, VUC send disable.";
CM_ SG_ 311 DCM_RL_PriorSoundReq "Require of sound reminder prior RL door automatic via speaker";
CM_ SG_ 312 DCM_RR_PriorSoundReq "Require of sound reminder prior RR door automatic via speaker";
CM_ SG_ 316 SGW_R_MirrorTiltVerticalPos "Right exterior mirror vertical automatic adjustment request in tilt mode";
CM_ SG_ 316 SGW_R_MirrorTiltHorizontalPos "Right exterior mirror horizontal automatic adjustment request in tilt mode";
CM_ SG_ 316 SGW_L_MirrorTiltVerticalPos "Left exterior mirror vertical automatic adjustment request in tilt mode";
CM_ SG_ 316 SGW_L_MirrorTiltHorizontalPos "Left exterior mirror horizontal automatic adjustment request in tilt mode";
CM_ SG_ 316 SGW_R_MirrorMainVerticalPos "Right exterior mirror vertical automatic adjustment request in main mode";
CM_ SG_ 316 SGW_R_MirrorMainHorizontalPos "Right exterior mirror horizontal automatic adjustment request in main mode";
CM_ SG_ 316 SGW_L_MirrorMainVerticalPos "Left exterior mirror vertical automatic adjustment request in main mode";
CM_ SG_ 316 SGW_L_MirrorMainHorizontalPos "Left exterior mirror horizontal automatic adjustment request in main mode";
CM_ SG_ 317 BCM_SynRequest "Counter sychronization request message";
CM_ SG_ 319 VCU_SynRequest "Counter sychronization request message";
CM_ SG_ 512 ERA_ECallSts "E-Call call status";
CM_ SG_ 512 ERA_TestModeSts "ERA test mode";
CM_ SG_ 512 ERA_SelfTestSts "ERA self-test status";
CM_ SG_ 515 ADCU_LDW_SYS_Sts "LDW system symbol state";
CM_ SG_ 515 ADCU_RightLaneVisualizationSts "Right lane display status";
CM_ SG_ 515 ADCU_LDWWarningModeState "LDW warning mode setting";
CM_ SG_ 515 ADCU_LeftLaneVisualizationSts "Left lane display status";
CM_ SG_ 530 BMS_AllowChagCurrent "Maximum allowable charging current";
CM_ SG_ 530 BMS_MaxChagVoltage "Maximum allowable charging voltage";
CM_ SG_ 530 BMS_RemChagTime "Remaining charging time prediction in minute";
CM_ SG_ 531 BMS_ChargeRequest "BMS charging request";
CM_ SG_ 531 BMS_AbortErrorVoltage "Abnormal voltage suspends charging";
CM_ SG_ 531 BMS_ChagComplete "Charging completion status";
CM_ SG_ 531 BMS_AbortFaultBMSTemp "BMS over temperature suspension charging";
CM_ SG_ 531 BMS_AbortFaultBatteryTemp "Battery pack over temperature stops charging";
CM_ SG_ 531 BMS_AbortErrorCurrent "Overcurrent suspension charging";
CM_ SG_ 531 BMS_AbortAchivesetValue "Abort charging when reaching the required SOC target value";
CM_ SG_ 531 BMS_DCChgMode "DC charging mode";
CM_ SG_ 531 BMS_AbortAchiveSingleVolt "Abort charging when reaching the set value of unit voltage";
CM_ SG_ 531 BMS_AbortAchiveTotalVolt "Stop charging when the total voltage setting is reached";
CM_ SG_ 532 BMS_DisplaySOC "BMS Display SOC";
CM_ SG_ 532 BMS_SOC "BMS Real SOC";
CM_ SG_ 532 BMS_LinkVoltage "Pack Outside Volt";
CM_ SG_ 532 BMS_PackVoltage "Pack Inside Volt";
CM_ SG_ 536 BMS_MinCellTempNO "Minimal Cell TemperatureInlet NO";
CM_ SG_ 536 BMS_MaxCellTempNO "Maximal Cell TemperatureInlet NO";
CM_ SG_ 536 BMS_MinCellTempModuleNO "Minimal Cell TemperatureInlet module NO";
CM_ SG_ 536 BMS_MaxCellTempModuleNO "Maximal Cell TemperatureInlet module NO";
CM_ SG_ 536 BMS_MinCellTemp "Minimal Cell TemperatureInlet value";
CM_ SG_ 536 BMS_MaxCellTemp "Maximal Cell TemperatureInlet value";
CM_ SG_ 536 BMS_AverageCellTemp "Average battery cell temperature";
CM_ SG_ 536 BMS_ThermometerProbes "Sum of Temperature Probe in PACK";
CM_ SG_ 544 VCU_DCDCPowerLimit "DCDC power limit";
CM_ SG_ 544 VCU_RequestedModeDCDC "Requested state of the DCDC converter";
CM_ SG_ 544 VCU_VoltageDemandLV "Desired voltage of the DCDC converter LV side (buck mode 14.1v)";
CM_ SG_ 547 VCU_ForwardVmaxlimitStatus "maximum speed limit status in D gear";
CM_ SG_ 547 VCU_ManuallyUnlockComment "Manual unlock electronic lock reminder signal";
CM_ SG_ 561 IVI_CRLevelSet "The user specified  energy recovery level";
CM_ SG_ 561 IVI_HDCOffSet "HDC On/Off switch setting signal";
CM_ SG_ 561 IVI_AVHSet "AVH On/Off switch setting signal";
CM_ SG_ 561 IVI_SteeringModeSet "Steering mode set";
CM_ SG_ 561 IVI_BrakeCompensateCmd "Brake compensation setting instruction";
CM_ SG_ 561 IVI_ESCOffSet "ESC On/Off switch setting signal";
CM_ SG_ 561 IVI_TPMS_Reset "Reset TPMS";
CM_ SG_ 569 SGW_SecOCMAC_239 "Message authentication code";
CM_ SG_ 569 SGW_SecOCFV_239 "Freshness value";
CM_ SG_ 569 SGW_RoleAccessSts "Role access state";
CM_ SG_ 569 SGW_FaceIDAuthenticationSuccess "FaceID Authentication Success";
CM_ SG_ 569 SGW_ImmobilizingEnable "Remote APP/Atom HUB setting Immobilizing";
CM_ SG_ 571 SGW_TimingChargeStartminute "Feedback charging start time for appointment charging: minute";
CM_ SG_ 571 SGW_TimingChargeStarthour "Feedbackt charging start time for appointment charging: hour";
CM_ SG_ 571 SGW_TimingChargeEndminute "Feedback charging stop time for appointment charging: minute";
CM_ SG_ 571 SGW_TimingChargeEndhour "Feedback charging stop time for appointment charging: hour";
CM_ SG_ 574 IVI_PassWindowLockSet "Passenger window lock control";
CM_ SG_ 574 IVI_RRDoorLockSet "RR unlocked request";
CM_ SG_ 574 IVI_FLDoorLockSet "FL unlocked request";
CM_ SG_ 574 IVI_FRDoorLockSet "FR unlocked request";
CM_ SG_ 574 IVI_RLDoorLockSet "RL unlocked request";
CM_ SG_ 574 IVI_ModeEnterReq "IVI mode entry request";
CM_ SG_ 575 SGW_MirrorAutoTurnDownSet "Automatic rearview mirror down control signal";
CM_ SG_ 575 SGW_WelcomeOnOffSet "Welcome set signal";
CM_ SG_ 575 SGW_PassWelcomeOnOffSet "Passenger welcome set signal";
CM_ SG_ 575 SGW_DrSeatWelcomeLevelSet "Driver Seat welcome position level setting";
CM_ SG_ 575 SGW_PsSeatWelcomeLevelSet "Passenger Seat welcome position level setting";
CM_ SG_ 575 SGW_L_RearSeatHeatSet "Rear left seat heating level setting";
CM_ SG_ 575 SGW_R_RearSeatHeatSet "Rear right seat heating level setting";
CM_ SG_ 576 POD_DCInletTempB "Actual DC - temperatur connector";
CM_ SG_ 576 POD_DCInletTempA "Actual DC + temperatur connector";
CM_ SG_ 576 POD_Temperature "This signal reflects the temperature of Coolant outlet";
CM_ SG_ 576 POD_DCFCVoltage "DC relay out side voltage";
CM_ SG_ 577 POD_T15e_fault "Give feedback of T15e status";
CM_ SG_ 577 POD_CANBusoff "CAN  Busoff error";
CM_ SG_ 577 POD_TempHighFault "PCB overtemperature fault?environmental overtemprerature)";
CM_ SG_ 577 POD_TempSensor1Fault "POD temperature fault of the temporature Coolant outlet or structure";
CM_ SG_ 577 POD_KL30Error "KL30 error";
CM_ SG_ 577 POD_DCPosRelayState "Give feedback of DC charge positive relay state";
CM_ SG_ 577 POD_DCPortInletTempAValid "Error state for the temperature sensor. E.g. damaged or short circuit at the temperature sensor in the inlet.";
CM_ SG_ 577 POD_DCPortInletTempBValid "Error state for the temperature sensor. E.g. damaged or short circuit at the temperature sensor in the inlet.";
CM_ SG_ 578 POD_DCDC_LVOutputVoltage "Voltage on low voltage side";
CM_ SG_ 578 POD_DCDC_HVInputCurrent "Current at high voltage side";
CM_ SG_ 578 POD_DCDC_LVOutputCurrent "Current on low voltage side";
CM_ SG_ 578 POD_DCDC_WorkMode "State DCDC converter";
CM_ SG_ 578 POD_DCDC_HVInputVoltage "Voltage at high voltage side";
CM_ SG_ 580 POD_OBC_OutputDCChargeVoltage "OutputDCChargeVoltage,Positive is charge, negative is discharge";
CM_ SG_ 580 POD_OBC_ACFrequencyStatus "AC side frequency when charge and discharge";
CM_ SG_ 580 POD_OBC_ACPortTempB "Actual temperatur connector B";
CM_ SG_ 580 POD_OBC_ACPortTempA "Actual temperatur connector A";
CM_ SG_ 580 POD_OBC_OutputDCChargeCurrent "OBC output current when charge.Positive is charge, negative is discharge.";
CM_ SG_ 580 POD_OBC_ChrgOutpPwrAvl "Report the maximum output power at present.Positive is charge, negative is discharge.";
CM_ SG_ 610 TCU_CabinTemperatureValid "Cabin temperature Valid";
CM_ SG_ 610 TCU_CabinTemperature "Cabin temperature";
CM_ SG_ 614 EVCOM_ActlOprtMode "Air Conditioning Compressor Actual Operation Mode";
CM_ SG_ 614 EVCOM_CompActlCnsmpCur "Compressor Run Current";
CM_ SG_ 614 EVCOM_CompActlPwrCnsmp "Compressor Actual Power Consumption";
CM_ SG_ 614 EVCOM_CompActlSpd "Compressor Actual Speed";
CM_ SG_ 614 EVCOM_CompDeviceInternTemp "Device Internal Temperature";
CM_ SG_ 614 EVCOM_OverPwrDropFreqError "EVCOM Over Power Drop Frequency Error";
CM_ SG_ 614 EVCOM_OverCurDropFreqError "EVCOM Over Current Drop Frequency Error";
CM_ SG_ 614 EVCOM_CommunicationError "EVCOM Communication Error";
CM_ SG_ 614 EVCOM_StandByUnderVolError "EVCOM Stand By Under Voltage Error";
CM_ SG_ 614 EVCOM_StandByOverVolError "EVCOM Stand By Over Voltage Error";
CM_ SG_ 614 EVCOM_UnderVoltageError "EVCOM Under Voltage Error LV";
CM_ SG_ 614 EVCOM_OverVoltageError "EVCOM Over Voltage Error LV";
CM_ SG_ 614 EVCOM_OverCurrentError "EVCOM Over Current Error";
CM_ SG_ 624 BCM_ALM1_MusicFrequencySts "atmosphere light music rhythm state";
CM_ SG_ 624 BCM_ALM2_MusicFrequencySts "atmosphere light music rhythm state";
CM_ SG_ 626 BCM_SecOCMAC_272 "Message authentication code";
CM_ SG_ 626 BCM_SecOCFV_272 "Freshness value";
CM_ SG_ 626 BCM_Immo_State "BCM-VCU Immobilizing state";
CM_ SG_ 646 DCM_FL_AmbientLiAniSts "Ambient light animation state signal";
CM_ SG_ 646 DCM_FL_AmbientLightColorSts "DCM_FL ambient light color set state";
CM_ SG_ 646 DCM_FL_AmbientLightSts "DCM_FL ambient lamp state signal";
CM_ SG_ 646 DCM_FL_AmbientLightBrightSts "DCM_FL ambient light brightness state";
CM_ SG_ 646 DCM_ALM_FL_MusicFrequencySts "atmosphere light music rhythm state";
CM_ SG_ 647 DCM_FR_AmbientLiAniSts "Ambient light animation state signal";
CM_ SG_ 647 DCM_FR_AmbientLightColorSts "DCM_FR ambient light color set state";
CM_ SG_ 647 DCM_FR_AmbientLightSts "DCM_FR ambient lamp state signal";
CM_ SG_ 647 DCM_FR_AmbientLightBrightSts "DCM_FR ambient light brightness state";
CM_ SG_ 647 DCM_ALM_FR_MusicFrequencySts "atmosphere light music rhythm state";
CM_ SG_ 648 DCM_RL_AmbientLiAniSts "Ambient light animation state signal";
CM_ SG_ 648 DCM_RL_AmbientLightColorSts "DCM_RL ambient light color set state";
CM_ SG_ 648 DCM_RL_AmbientLightSts "DCM_RL ambient lamp state signal";
CM_ SG_ 648 DCM_RL_AmbientLightBrightSts "DCM_RL ambient light brightness state";
CM_ SG_ 648 DCM_ALM_RL_MusicFrequencySts "atmosphere light music rhythm state";
CM_ SG_ 649 DCM_RR_AmbientLiAniSts "Ambient light animation state signal";
CM_ SG_ 649 DCM_RR_AmbientLightColorSts "DCM_RR ambient light color set state";
CM_ SG_ 649 DCM_RR_AmbientLightSts "DCM_RR ambient lamp state signal";
CM_ SG_ 649 DCM_RR_AmbientLightBrightSts "DCM_RR ambient light brightness state";
CM_ SG_ 649 DCM_ALM_RR_MusicFrequencySts "atmosphere light music rhythm state";
CM_ SG_ 652 DCM_FL_MirrorMainHorizontalPos "Locally stored left exterior mirror horizontal position in main mode";
CM_ SG_ 652 DCM_FL_MirrorMainVerticalPos "Locally stored left exterior mirror vertical position in main mode";
CM_ SG_ 652 DCM_FL_MirrorTiltHorizontalPos "Locally stored left exterior mirror horizontal position in tilt mode";
CM_ SG_ 652 DCM_FL_MirrorTiltVerticalPos "Locally stored left exterior mirror vertical position in tilt mode";
CM_ SG_ 653 DCM_FR_MirrorMainHorizontalPos "Locally stored right exterior mirror horizontal position in main mode";
CM_ SG_ 653 DCM_FR_MirrorMainVerticalPos "Locally stored right exterior mirror vertical position in main mode";
CM_ SG_ 653 DCM_FR_MirrorTiltHorizontalPos "Locally stored right exterior mirror horizontal position in tilt mode";
CM_ SG_ 653 DCM_FR_MirrorTiltVerticalPos "Locally stored right exterior mirror vertical position in tilt mode";
CM_ SG_ 663 WCBS1_ReminderSts "Forgetting reminder setting status";
CM_ SG_ 663 WCBS1_Reminder "Forgotten Reminder";
CM_ SG_ 664 WCBS2_ReminderSts "Forgetting reminder setting status";
CM_ SG_ 664 WCBS2_Reminder "Forgotten Reminder";
CM_ SG_ 665 SCU_L_SeatMemoryBackPos "Locally stored driver seat backrest position";
CM_ SG_ 665 SCU_L_SeatMemorySlidePos "Locally stored driver seat slide position";
CM_ SG_ 665 SCU_L_SeatMemoryHeightPos "Locally stored driver seat height position";
CM_ SG_ 689 IVI_HUDOnOffSet "HUD switch control";
CM_ SG_ 689 IVI_HUDALTITUDESet "height setting signal";
CM_ SG_ 690 SGW_IMUWorkingSts "IMU working state";
CM_ SG_ 690 SGW_VehicleTiltSlopeX "Vehicle X-axis tilt slope";
CM_ SG_ 690 SGW_VehicleTiltSlopeY "Vehicle Y-axis tilt slope";
CM_ SG_ 692 IVI_VrState "Voice assistant Active/Inactive";
CM_ SG_ 692 IVI_MirrorInterfaceMode "Exterior mirrors adjustment interface mode";
CM_ SG_ 693 IVI_LV_LimitPop "Operation pop-up prompt";
CM_ SG_ 693 IVI_KeepWarmRequest "Keeping warm function opening instruction";
CM_ SG_ 693 IVI_LockACPlug "Unlock electronic lock by IVI";
CM_ SG_ 693 IVI_AppointChargeCmd "Charging end command";
CM_ SG_ 693 IVI_ForwardVmaxlimitSw "maximum speed limit in D gear setting";
CM_ SG_ 694 IVI_GearRequest "Gear request";
CM_ SG_ 710 IVI_StWLengthPos "Steering wheel length position request";
CM_ SG_ 710 IVI_StWAnglePos "Steering wheel angle position request";
CM_ SG_ 721 CBM_SecOCMAC_2D1 "Message authentication code";
CM_ SG_ 721 CBM_SecOCFV_2D1 "Freshness value";
CM_ SG_ 721 CBM_PhoneLocation "Bluetooth key location information";
CM_ SG_ 721 CBM_BlePairingSetSts "BLE pairing enable state";
CM_ SG_ 795 VCU_Display_voltage "Charge and discharge voltage (display)";
CM_ SG_ 850 SGW_BLERLLockCtrlReq "Bluetooth key RL lock control command";
CM_ SG_ 850 SGW_BLERRLockCtrlReq "Bluetooth key RR lock control command";
CM_ SG_ 850 SGW_BLELockCtrlReq "Bluetooth key lock control command";
CM_ SG_ 850 SGW_BLEChrgFlaplockCtrlReq "Bluetooth key charging flap lock control command";
CM_ SG_ 850 SGW_BLEFLLockCtrlReq "Bluetooth key FL lock control command";
CM_ SG_ 850 SGW_BLEFRLockCtrlReq "Bluetooth key FR lock control command";
CM_ SG_ 850 SGW_KeyLowBatWarning "Fob battery low warning.";
CM_ SG_ 850 SGW_BLEPowerModeReq "CBM request Power ON";
CM_ SG_ 850 SGW_BLESystemReadyReq "CBM request ready";
CM_ SG_ 850 SGW_BLETailgateCtrlReq "Bluetoot control back door command";
CM_ SG_ 857 SGW_PRNDSts "PRND status at this time";
CM_ SG_ 857 SGW_SwichesSts "Swiches status at this time";
CM_ SG_ 857 SGW_HOD_HeatingSts "HOD_Heating status at this time";
CM_ SG_ 857 SGW_SWPSts "SWP status at this time";
CM_ SG_ 857 SGW_BCMSts "BCM status at this time";
CM_ SG_ 857 SGW_BMSSts "BMS status at this time";
CM_ SG_ 857 SGW_VCUSts "VCU  status at this time";
CM_ SG_ 857 SGW_ADCUSts "ADCU status at this time";
CM_ SG_ 857 SGW_IVISts "IVI  status at this time";
CM_ SG_ 857 SGW_MFP_FCSts "MFP_FC status at this time";
CM_ SG_ 857 SGW_MFP_RCSts "MFP_RC status at this time";
CM_ SG_ 857 SGW_HLLSts "HLL status at this time";
CM_ SG_ 857 SGW_HLRSts "HLR status at this time";
CM_ SG_ 857 SGW_SCU_RSts "SCU_R status at this time";
CM_ SG_ 857 SGW_SCU_LSts "SCU_L status at this time";
CM_ SG_ 857 SGW_DCM_RRSts "DCM_RR status at this time";
CM_ SG_ 857 SGW_DCM_RLSts "DCM_RL status at this time";
CM_ SG_ 857 SGW_DCM_FRSts "DCM_FR status at this time";
CM_ SG_ 857 SGW_DCM_FLSts "DCM_FL status at this time";
CM_ SG_ 857 SGW_CBMSts "CBM status at this time";
CM_ SG_ 857 SGW_CGWSts "CGW status at this time";
CM_ SG_ 857 SGW_SGWSts "SGW status at this time";
CM_ SG_ 858 CGW_PRNDSts "PRND status at this time";
CM_ SG_ 858 CGW_SwichesSts "Swiches status at this time";
CM_ SG_ 858 CGW_HOD_HeatingSts "HOD_Heating status at this time";
CM_ SG_ 858 CGW_SWPSts "SWP status at this time";
CM_ SG_ 858 CGW_BCMSts "BCM status at this time";
CM_ SG_ 858 CGW_BMSSts "BMS status at this time";
CM_ SG_ 858 CGW_VCUSts "VCU  status at this time";
CM_ SG_ 858 CGW_ADCUSts "ADCU status at this time";
CM_ SG_ 858 CGW_IVISts "IVI  status at this time";
CM_ SG_ 858 CGW_MFP_FCSts "MFP_FC status at this time";
CM_ SG_ 858 CGW_MFP_RCSts "MFP_RC status at this time";
CM_ SG_ 858 CGW_HLLSts "HLL status at this time";
CM_ SG_ 858 CGW_HLRSts "HLR status at this time";
CM_ SG_ 858 CGW_SCU_RSts "SCU_R status at this time";
CM_ SG_ 858 CGW_SCU_LSts "SCU_L status at this time";
CM_ SG_ 858 CGW_DCM_RRSts "DCM_RR status at this time";
CM_ SG_ 858 CGW_DCM_RLSts "DCM_RL status at this time";
CM_ SG_ 858 CGW_DCM_FRSts "DCM_FR status at this time";
CM_ SG_ 858 CGW_DCM_FLSts "DCM_FL status at this time";
CM_ SG_ 858 CGW_CBMSts "CBM status at this time";
CM_ SG_ 858 CGW_CGWSts "CGW status at this time";
CM_ SG_ 858 CGW_SGWSts "SGW status at this time";
CM_ SG_ 880 DCM_SDS_FL_SensorWorksts "Front left door radar working status";
CM_ SG_ 881 DCM_SDS_FR_SensorWorksts "Front right door radar working status";
CM_ SG_ 882 DCM_SDS_RL_SensorWorksts "Rear left door radar working status";
CM_ SG_ 883 DCM_SDS_RR_SensorWorksts "Rear right door radar working status";
CM_ SG_ 896 CGW_VIN7 "Vehicle Description Section";
CM_ SG_ 896 CGW_VIN6 "Vehicle Description Section";
CM_ SG_ 896 CGW_VIN5 "Vehicle Description Section";
CM_ SG_ 896 CGW_VIN4 "Vehicle Description Section";
CM_ SG_ 896 CGW_VIN3 "Vehicle Description Section";
CM_ SG_ 896 CGW_VIN2 "World Manufacturers Identification";
CM_ SG_ 896 CGW_VIN1 "World Manufacturers Identification";
CM_ SG_ 896 CGW_VIN0 "World Manufacturers Identification";
CM_ SG_ 897 CGW_VIN15 "Vehicle Identification Section";
CM_ SG_ 897 CGW_VIN14 "Vehicle Identification Section";
CM_ SG_ 897 CGW_VIN13 "Vehicle Identification Section";
CM_ SG_ 897 CGW_VIN12 "Vehicle Identification Section";
CM_ SG_ 897 CGW_VIN11 "Vehicle Identification Section";
CM_ SG_ 897 CGW_VIN10 "Vehicle Identification Section";
CM_ SG_ 897 CGW_VIN9 "Vehicle Identification Section";
CM_ SG_ 897 CGW_VIN8 "Vehicle Identification Section";
CM_ SG_ 898 CGW_VERSION2 "Minor Release";
CM_ SG_ 898 CGW_VERSION1 "Major Release";
CM_ SG_ 898 CGW_VIN16 "Vehicle Identification Section";
CM_ SG_ 914 MCU_IGBTTempRiseMax "the temperature rise of Max phase IGBT";
CM_ SG_ 914 MCU_IGBTTempRiseW "the temperature rise of W phase IGBT";
CM_ SG_ 914 MCU_IGBTTempRiseV "the temperature rise of V phase IGBT";
CM_ SG_ 914 MCU_IGBTTempRiseU "the temperature rise of U phase IGBT";
CM_ SG_ 914 MCU_IGBTTempMax "the temperature of Max phase IGBT";
CM_ SG_ 914 MCU_IGBTTempW "the temperature of W phase IGBT";
CM_ SG_ 914 MCU_IGBTTempV "the temperature of V phase IGBT";
CM_ SG_ 914 MCU_IGBTTempU "the temperature of U phase IGBT";
CM_ SG_ 915 MCU_TempStatus "The E-motor temperature state";
CM_ SG_ 915 MCU_TempRiseCurrStr "the temperature of stator NTC1";
CM_ SG_ 915 MCU_TempCurrStrMax "the temperature of Max stator NTC";
CM_ SG_ 915 MCU_TempCurrStr2 "the temperature of stator NTC2";
CM_ SG_ 915 MCU_TempCurrStr1 "the temperature of stator NTC1";
CM_ SG_ 915 MCU_TempCurrCool "the temperature of coolant";
CM_ SG_ 928 MCU_HvMcuVer "the version of Hv Mcu software";
CM_ SG_ 928 MCU_CpldVer "the version of CPLD software";
CM_ SG_ 928 MCU_DataVer "the version of TC275 software calibration data";
CM_ SG_ 928 MCU_CodeVer "the version of TC275 software code";
CM_ SG_ 929 MCU_HwVer "the version of hardware";
CM_ SG_ 933 BMS_BatProDatDay "Battery pack production date day";
CM_ SG_ 933 BMS_BatProDatMonth "Battery pack production date month";
CM_ SG_ 933 BMS_BatProDatYear "Battery pack production date year";
CM_ SG_ 934 BMS_RatBatVoltage "Rated Voltage of power battery system";
CM_ SG_ 934 BMS_RatEnergy "Nominal total energy of power battery";
CM_ SG_ 934 BMS_RatCapacity "Rated capacity of power battery system";
CM_ SG_ 934 BMS_CellNumbers "Sum of cell in pack";
CM_ SG_ 934 BMS_BatType "Battery type";
CM_ SG_ 945 SGW_OdometerInforValid "SGW external total mileage effective marker signal";
CM_ SG_ 945 SGW_OdometerInfor "SGW sends backup total mileage signal";
CM_ SG_ 946 SGW_VIN "SGW sends the last eight digits of the VIN";
CM_ SG_ 947 MCU_FaultNum8 "Real-time fault code of number 8";
CM_ SG_ 947 MCU_FaultNum7 "Real-time fault code of number 7";
CM_ SG_ 947 MCU_FaultNum6 "Real-time fault code of number 6";
CM_ SG_ 947 MCU_FaultNum5 "Real-time fault code of number 5";
CM_ SG_ 947 MCU_FaultNum4 "Real-time fault code of number 4";
CM_ SG_ 947 MCU_FaultNum3 "Real-time fault code of number 3";
CM_ SG_ 947 MCU_FaultNum2 "Real-time fault code of number 2";
CM_ SG_ 947 MCU_FaultNum1 "Real-time fault code of number 1";
CM_ SG_ 948 MCU_TotalFaultNum "Total number of current faults";
CM_ SG_ 948 MCU_FaultNum10 "Real-time fault code of number 10";
CM_ SG_ 948 MCU_FaultNum9 "Real-time fault code of number 9";
CM_ SG_ 960 SGW_SynMsgAuthenticator "Synchronization message authenticator";
CM_ SG_ 960 SGW_ResetCounter "Reset counter";
CM_ SG_ 960 SGW_TripCounter "Trip counter";
CM_ SG_ 992 BMS_DirveDiscSts "Accumulated actual discharge energy during this operation";
CM_ SG_ 992 BMS_FeedEnergySts "Accumulated actual feedback energy for this operation";
CM_ SG_ 1025 BCM1_DTC_Number "Number of current failures";
CM_ SG_ 1026 CGW_DTC_Number "Number of current failures";
CM_ SG_ 1027 SGW_DTC_Number "Number of current failures";
CM_ SG_ 1029 ERA_DTC_Number "Number of current failures";
CM_ SG_ 1030 Switches_DTC_Number "Number of current failures";
CM_ SG_ 1031 SWP_DTC_Number "Number of current failures";
CM_ SG_ 1032 NDT_DTC_Number "Number of current failures";
CM_ SG_ 1033 HOD_heating_DTC_Number "Number of current failures";
CM_ SG_ 1034 CBM_DTC_Number "Number of current failures";
CM_ SG_ 1037 HUD_DTC_Number "Number of current failures";
CM_ SG_ 1038 DIM_DTC_Number "Number of current failures";
CM_ SG_ 1043 BMS_DTC_Number "Number of current failures";
CM_ SG_ 1046 MFP_FC_DTC_Number "Number of current failures";
CM_ SG_ 1049 MFP_RC_DTC_Number "Number of current failures";
CM_ SG_ 1050 BCM2_DTC_Number "Number of current failures";
CM_ SG_ 1051 SCUL_DTC_Number "Number of current failures";
CM_ SG_ 1052 SCUR_DTC_Number "Number of current failures";
CM_ SG_ 1053 HLL_DTC_Number "Number of current failures";
CM_ SG_ 1055 WCBS1_DTC_Number "Number of current failures";
CM_ SG_ 1056 WCBS2_DTC_Number "Number of current failures";
CM_ SG_ 1062 IBS_DTC_Number "Number of current failures";
CM_ SG_ 1065 EPS_DTC_Number "Number of current failures";
CM_ SG_ 1067 PAT_DTC_Number "Number of current failures";
CM_ SG_ 1068 VCU_DTC_Number "Number of current failures";
CM_ SG_ 1071 DCM_FL_DTC_Number "Number of current failures";
CM_ SG_ 1079 DCM_RL_DTC_Number "Number of current failures";
CM_ SG_ 1083 DCM_FR_DTC_Number "Number of current failures";
CM_ SG_ 1084 DCM_RR_DTC_Number "Number of current failures";
CM_ SG_ 1086 HLR_DTC_Number "Number of current failures";
CM_ SG_ 1088 ADCU_DTC_Number "Number of current failures";
CM_ SG_ 1090 MCU_DTC_Number "Number of current failures";
CM_ SG_ 1091 AVAS_DTC_Number "Number of current failures";
CM_ SG_ 1092 IVI_DTC_Number "Number of current failures";
CM_ SG_ 1095 POD_DTC_Number "Number of current failures";
CM_ SG_ 1096 TCU_DTC_Number "Number of current failures";
CM_ SG_ 1097 EVCOM_DTC_Number "Number of current failures";
CM_ SG_ 1102 AIRPTC_DTC_Number "Number of current failures";
CM_ SG_ 1103 PRND_DTC_Number "Number of current failures";
CM_ SG_ 1273 ACU_DTC_Number "Number of current failures";
CM_ SG_ 1282 CGW_PNC39 "Partial Network Cluster";
CM_ SG_ 1282 CGW_PNC38 "Partial Network Cluster";
CM_ SG_ 1282 CGW_PNC37 "Partial Network Cluster";
CM_ SG_ 1282 CGW_PNC36 "Partial Network Cluster";
CM_ SG_ 1282 CGW_PNC35 "Partial Network Cluster";
CM_ SG_ 1282 CGW_PNC34 "Partial Network Cluster";
CM_ SG_ 1282 CGW_PNC33 "Partial Network Cluster";
CM_ SG_ 1282 CGW_PNC32 "Partial Network Cluster";
CM_ SG_ 1282 CGW_PNC31 "Partial Network Cluster";
CM_ SG_ 1282 CGW_PNC30 "Partial Network Cluster";
CM_ SG_ 1282 CGW_PNC29 "Partial Network Cluster";
CM_ SG_ 1282 CGW_PNC28 "Partial Network Cluster";
CM_ SG_ 1282 CGW_PNC27 "Partial Network Cluster";
CM_ SG_ 1282 CGW_PNC26 "Partial Network Cluster";
CM_ SG_ 1282 CGW_PNC25 "Partial Network Cluster";
CM_ SG_ 1282 CGW_PNC24 "Partial Network Cluster";
CM_ SG_ 1282 CGW_PNC23 "Partial Network Cluster";
CM_ SG_ 1282 CGW_PNC22 "Partial Network Cluster";
CM_ SG_ 1282 CGW_PNC21 "Partial Network Cluster-PRND";
CM_ SG_ 1282 CGW_PNC20 "Partial Network Cluster-Swiches";
CM_ SG_ 1282 CGW_PNC19 "Partial Network Cluster-HOD_Heating";
CM_ SG_ 1282 CGW_PNC18 "Partial Network Cluster-SWP";
CM_ SG_ 1282 CGW_PNC17 "Partial Network Cluster-BCM";
CM_ SG_ 1282 CGW_PNC16 "Partial Network Cluster-BMS";
CM_ SG_ 1282 CGW_PNC15 "Partial Network Cluster-VCU";
CM_ SG_ 1282 CGW_PNC14 "Partial Network Cluster-ADCU";
CM_ SG_ 1282 CGW_PNC13 "Partial Network Cluster-IVI";
CM_ SG_ 1282 CGW_PNC12 "Partial Network Cluster-MFP_FC";
CM_ SG_ 1282 CGW_PNC11 "Partial Network Cluster-MFP_RC";
CM_ SG_ 1282 CGW_PNC10 "Partial Network Cluster-HLL";
CM_ SG_ 1282 CGW_PNC9 "Partial Network Cluster-HLR";
CM_ SG_ 1282 CGW_PNC8 "Partial Network Cluster-SCU_R";
CM_ SG_ 1282 CGW_PNC7 "Partial Network Cluster-SCU_L";
CM_ SG_ 1282 CGW_PNC6 "Partial Network Cluster-DCM_RR";
CM_ SG_ 1282 CGW_PNC5 "Partial Network Cluster-DCM_RL";
CM_ SG_ 1282 CGW_PNC4 "Partial Network Cluster-DCM_FR";
CM_ SG_ 1282 CGW_PNC3 "Partial Network Cluster-DCM_FL";
CM_ SG_ 1282 CGW_PNC2 "Partial Network Cluster-CBM";
CM_ SG_ 1282 CGW_PNC1 "Partial Network Cluster-CGW";
CM_ SG_ 1282 CGW_PNC0 "Partial Network Cluster-SGW";
CM_ SG_ 1282 CGW_PNI "Partial network information Bit";
CM_ SG_ 1282 CGW_AWB "Active Wakeup Bit";
CM_ SG_ 1282 CGW_RMR "Repeat Message Request";
CM_ SG_ 1283 SGW_PNC39 "Partial Network Cluster";
CM_ SG_ 1283 SGW_PNC38 "Partial Network Cluster";
CM_ SG_ 1283 SGW_PNC37 "Partial Network Cluster";
CM_ SG_ 1283 SGW_PNC36 "Partial Network Cluster";
CM_ SG_ 1283 SGW_PNC35 "Partial Network Cluster";
CM_ SG_ 1283 SGW_PNC34 "Partial Network Cluster";
CM_ SG_ 1283 SGW_PNC33 "Partial Network Cluster";
CM_ SG_ 1283 SGW_PNC32 "Partial Network Cluster";
CM_ SG_ 1283 SGW_PNC31 "Partial Network Cluster";
CM_ SG_ 1283 SGW_PNC30 "Partial Network Cluster";
CM_ SG_ 1283 SGW_PNC29 "Partial Network Cluster";
CM_ SG_ 1283 SGW_PNC28 "Partial Network Cluster";
CM_ SG_ 1283 SGW_PNC27 "Partial Network Cluster";
CM_ SG_ 1283 SGW_PNC26 "Partial Network Cluster";
CM_ SG_ 1283 SGW_PNC25 "Partial Network Cluster";
CM_ SG_ 1283 SGW_PNC24 "Partial Network Cluster";
CM_ SG_ 1283 SGW_PNC23 "Partial Network Cluster";
CM_ SG_ 1283 SGW_PNC22 "Partial Network Cluster";
CM_ SG_ 1283 SGW_PNC21 "Partial Network Cluster-PRND";
CM_ SG_ 1283 SGW_PNC20 "Partial Network Cluster-Swiches";
CM_ SG_ 1283 SGW_PNC19 "Partial Network Cluster-HOD_Heating";
CM_ SG_ 1283 SGW_PNC18 "Partial Network Cluster-SWP";
CM_ SG_ 1283 SGW_PNC17 "Partial Network Cluster-BCM";
CM_ SG_ 1283 SGW_PNC16 "Partial Network Cluster-BMS";
CM_ SG_ 1283 SGW_PNC15 "Partial Network Cluster-VCU";
CM_ SG_ 1283 SGW_PNC14 "Partial Network Cluster-ADCU";
CM_ SG_ 1283 SGW_PNC13 "Partial Network Cluster-IVI";
CM_ SG_ 1283 SGW_PNC12 "Partial Network Cluster-MFP_FC";
CM_ SG_ 1283 SGW_PNC11 "Partial Network Cluster-MFP_RC";
CM_ SG_ 1283 SGW_PNC10 "Partial Network Cluster-HLL";
CM_ SG_ 1283 SGW_PNC9 "Partial Network Cluster-HLR";
CM_ SG_ 1283 SGW_PNC8 "Partial Network Cluster-SCU_R";
CM_ SG_ 1283 SGW_PNC7 "Partial Network Cluster-SCU_L";
CM_ SG_ 1283 SGW_PNC6 "Partial Network Cluster-DCM_RR";
CM_ SG_ 1283 SGW_PNC5 "Partial Network Cluster-DCM_RL";
CM_ SG_ 1283 SGW_PNC4 "Partial Network Cluster-DCM_FR";
CM_ SG_ 1283 SGW_PNC3 "Partial Network Cluster-DCM_FL";
CM_ SG_ 1283 SGW_PNC2 "Partial Network Cluster-CBM";
CM_ SG_ 1283 SGW_PNC1 "Partial Network Cluster-CGW";
CM_ SG_ 1283 SGW_PNC0 "Partial Network Cluster-SGW";
CM_ SG_ 1283 SGW_PNI "Partial network information Bit";
CM_ SG_ 1283 SGW_AWB "Active Wakeup Bit";
CM_ SG_ 1283 SGW_RMR "Repeat Message Request";
CM_ SG_ 1793 BCM1_DiagResp "Diagnostic response";
CM_ SG_ 1794 CGW_DiagResp "Diagnostic response";
CM_ SG_ 1796 IVI_DiagResp "Diagnostic response";
CM_ SG_ 1798 Switches_DiagResp "Diagnostic response";
CM_ SG_ 1799 SWP_DiagResp "Diagnostic response";
CM_ SG_ 1800 NDT_DiagResp "Diagnostic response";
CM_ SG_ 1801 HOD_heating_DiagResp "Diagnostic response";
CM_ SG_ 1805 HUD_DiagResp "Diagnostic response";
CM_ SG_ 1806 DIM_DiagResp "Diagnostic response";
CM_ SG_ 1811 BMS_DiagResp "Diagnostic response";
CM_ SG_ 1812 Switches2_DiagResp "Diagnostic response";
CM_ SG_ 1814 MFP_FC_DiagResp "Diagnostic response";
CM_ SG_ 1817 MFP_RC_DiagResp "Diagnostic response";
CM_ SG_ 1818 BCM2_DiagResp "Diagnostic response";
CM_ SG_ 1819 SCUL_DiagResp "Diagnostic response";
CM_ SG_ 1820 SCUR_DiagResp "Diagnostic response";
CM_ SG_ 1821 HLL_DiagResp "Diagnostic response";
CM_ SG_ 1822 HLR_DiagResp "Diagnostic response";
CM_ SG_ 1823 WCBS1_DiagResp "Diagnostic response";
CM_ SG_ 1824 WCBS2_DiagResp "Diagnostic response";
CM_ SG_ 1830 IBS_DiagResp "Diagnostic response";
CM_ SG_ 1833 EPS_DiagResp "Diagnostic response";
CM_ SG_ 1835 PAT_DiagResp "Diagnostic response";
CM_ SG_ 1836 VCU_DiagResp "Diagnostic response";
CM_ SG_ 1839 DCM_FL_DiagResp "Diagnostic response";
CM_ SG_ 1843 OBD_DiagReq "OBD Diagnostic request";
CM_ SG_ 1847 DCM_FR_DiagResp "Diagnostic response";
CM_ SG_ 1851 DCM_RL_DiagResp "Diagnostic response";
CM_ SG_ 1852 DCM_RR_DiagResp "Diagnostic response";
CM_ SG_ 1856 ADCU_DiagResp "Diagnostic response";
CM_ SG_ 1858 MCU_DiagResp "Diagnostic response";
CM_ SG_ 1859 AVAS_DiagResp "Diagnostic response";
CM_ SG_ 1863 POD_DiagResp "Diagnostic response";
CM_ SG_ 1864 TCU_DiagResp "Diagnostic response";
CM_ SG_ 1865 EVCOM_DiagResp "Diagnostic response";
CM_ SG_ 1870 AIRPTC_DiagResp "Diagnostic response";
CM_ SG_ 1871 PRND_DiagResp "Diagnostic response";
CM_ SG_ 1921 BCM1_DiagReq "Diagnostic request";
CM_ SG_ 1922 CGW_DiagReq "Diagnostic request";
CM_ SG_ 1924 IVI_DiagReq "Diagnostic request";
CM_ SG_ 1926 Switches_DiagReq "Diagnostic request";
CM_ SG_ 1927 SWP_DiagReq "Diagnostic request";
CM_ SG_ 1928 NDT_DiagReq "Diagnostic request";
CM_ SG_ 1929 HOD_heating_DiagReq "Diagnostic request";
CM_ SG_ 1933 HUD_DiagReq "Diagnostic request";
CM_ SG_ 1934 DIM_DiagReq "Diagnostic request";
CM_ SG_ 1939 BMS_DiagReq "Diagnostic request";
CM_ SG_ 1940 Switches2_DiagReq "Diagnostic request";
CM_ SG_ 1942 MFP_FC_DiagReq "Diagnostic request";
CM_ SG_ 1945 MFP_RC_DiagReq "Diagnostic request";
CM_ SG_ 1946 BCM2_DiagReq "Diagnostic request";
CM_ SG_ 1947 SCUL_DiagReq "Diagnostic request";
CM_ SG_ 1948 SCUR_DiagReq "Diagnostic request";
CM_ SG_ 1949 HLL_DiagReq "Diagnostic request";
CM_ SG_ 1950 HLR_DiagReq "Diagnostic request";
CM_ SG_ 1951 WCBS1_DiagReq "Diagnostic request";
CM_ SG_ 1952 WCBS2_DiagReq "Diagnostic request";
CM_ SG_ 1958 IBS_DiagReq "Diagnostic request";
CM_ SG_ 1961 EPS_DiagReq "Diagnostic request";
CM_ SG_ 1963 PAT_DiagReq "Diagnostic request";
CM_ SG_ 1964 VCU_DiagReq "Diagnostic request";
CM_ SG_ 1967 DCM_FL_DiagReq "Diagnostic request";
CM_ SG_ 1975 DCM_FR_DiagReq "Diagnostic request";
CM_ SG_ 1979 DCM_RL_DiagReq "Diagnostic request";
CM_ SG_ 1980 DCM_RR_DiagReq "Diagnostic request";
CM_ SG_ 1984 ADCU_DiagReq "Diagnostic request";
CM_ SG_ 1986 MCU_DiagReq "Diagnostic request";
CM_ SG_ 1987 AVAS_DiagReq "Diagnostic request";
CM_ SG_ 1991 POD_DiagReq "Diagnostic request";
CM_ SG_ 1992 TCU_DiagReq "Diagnostic request";
CM_ SG_ 1993 EVCOM_DiagReq "Diagnostic request";
CM_ SG_ 1998 AIRPTC_DiagReq "Diagnostic request";
CM_ SG_ 1999 PRND_DiagReq "Diagnostic request";
CM_ SG_ 2015 FUN_DiagReq "Diagnostic request";
CM_ SG_ 2016 VCU_OBD_DiagReq "VCU_OBD_Diagnostic request";
CM_ SG_ 2024 VCU_OBD_DiagResp "VCU_OBD_Diagnostic response";
CM_ SG_ 2025 BD_DiagReq "Body-CAN Diagnostic request";
CM_ SG_ 2026 PT_DiagReq "Powertrain-CAN Diagnostic request";
CM_ SG_ 2027 CH_DiagReq "Chassis-CAN Diagnostic request";
CM_ SG_ 2029 ET_DiagReq "Entertainment-CAN Diagnostic request";
CM_ SG_ 2033 ACU_DiagReq "Diagnostic request";
CM_ SG_ 2041 ACU_DiagResp "Diagnostic response";
CM_ SG_ 2047 ALL_DiagReq "Diagnostic request";
BA_DEF_ SG_  "GenSigStartValue" FLOAT 0 100000000000;
BA_DEF_DEF_  "GenSigStartValue" 0;
BA_ "GenSigStartValue" SG_ 150 VCU_MaxSpdLimit 32767;
BA_ "GenSigStartValue" SG_ 150 VCU_MotorSpdReq 32767;
BA_ "GenSigStartValue" SG_ 259 IVI_L_DsSeatSlidePos 254;
BA_ "GenSigStartValue" SG_ 259 IVI_L_DsSeatHeightPos 254;
BA_ "GenSigStartValue" SG_ 259 IVI_L_DsSeatBackPos 254;
BA_ "GenSigStartValue" SG_ 260 IVI_R_DsSeatBackPos 254;
BA_ "GenSigStartValue" SG_ 260 IVI_R_DsSeatHeightPos 254;
BA_ "GenSigStartValue" SG_ 260 IVI_R_DsSeatSlidePos 254;
BA_ "GenSigStartValue" SG_ 262 IVI_HUDScreenBrightnessSet 31;
BA_ "GenSigStartValue" SG_ 289 VCU_Enable_DC_Relay 1;
BA_ "GenSigStartValue" SG_ 289 VCU_OBC_Control_of_S2_SW 1;
BA_ "GenSigStartValue" SG_ 289 VCU_OBC_Control_of_em_lock 1;
BA_ "GenSigStartValue" SG_ 316 SGW_R_MirrorTiltVerticalPos 254;
BA_ "GenSigStartValue" SG_ 316 SGW_R_MirrorTiltHorizontalPos 254;
BA_ "GenSigStartValue" SG_ 316 SGW_L_MirrorTiltVerticalPos 254;
BA_ "GenSigStartValue" SG_ 316 SGW_L_MirrorTiltHorizontalPos 254;
BA_ "GenSigStartValue" SG_ 316 SGW_R_MirrorMainVerticalPos 254;
BA_ "GenSigStartValue" SG_ 316 SGW_R_MirrorMainHorizontalPos 254;
BA_ "GenSigStartValue" SG_ 316 SGW_L_MirrorMainVerticalPos 254;
BA_ "GenSigStartValue" SG_ 316 SGW_L_MirrorMainHorizontalPos 254;
BA_ "GenSigStartValue" SG_ 317 BCM_SynRequest 16777215;
BA_ "GenSigStartValue" SG_ 319 VCU_SynRequest 16777215;
BA_ "GenSigStartValue" SG_ 536 BMS_MinCellTemp 255;
BA_ "GenSigStartValue" SG_ 536 BMS_MaxCellTemp 255;
BA_ "GenSigStartValue" SG_ 536 BMS_AverageCellTemp 255;
BA_ "GenSigStartValue" SG_ 577 POD_DCPosRelayState 1;
BA_ "GenSigStartValue" SG_ 610 TCU_CabinTemperature 70;
BA_ "GenSigStartValue" SG_ 646 DCM_FL_AmbientLiAniSts 1;
BA_ "GenSigStartValue" SG_ 646 DCM_FL_AmbientLightColorSts 32;
BA_ "GenSigStartValue" SG_ 646 DCM_FL_AmbientLightBrightSts 5;
BA_ "GenSigStartValue" SG_ 647 DCM_FR_AmbientLiAniSts 1;
BA_ "GenSigStartValue" SG_ 647 DCM_FR_AmbientLightColorSts 32;
BA_ "GenSigStartValue" SG_ 647 DCM_FR_AmbientLightBrightSts 5;
BA_ "GenSigStartValue" SG_ 648 DCM_RL_AmbientLiAniSts 1;
BA_ "GenSigStartValue" SG_ 648 DCM_RL_AmbientLightColorSts 32;
BA_ "GenSigStartValue" SG_ 648 DCM_RL_AmbientLightBrightSts 5;
BA_ "GenSigStartValue" SG_ 649 DCM_RR_AmbientLiAniSts 1;
BA_ "GenSigStartValue" SG_ 649 DCM_RR_AmbientLightColorSts 32;
BA_ "GenSigStartValue" SG_ 649 DCM_RR_AmbientLightBrightSts 5;
BA_ "GenSigStartValue" SG_ 652 DCM_FL_MirrorMainHorizontalPos 254;
BA_ "GenSigStartValue" SG_ 652 DCM_FL_MirrorMainVerticalPos 254;
BA_ "GenSigStartValue" SG_ 652 DCM_FL_MirrorTiltHorizontalPos 254;
BA_ "GenSigStartValue" SG_ 652 DCM_FL_MirrorTiltVerticalPos 254;
BA_ "GenSigStartValue" SG_ 653 DCM_FR_MirrorMainHorizontalPos 254;
BA_ "GenSigStartValue" SG_ 653 DCM_FR_MirrorMainVerticalPos 254;
BA_ "GenSigStartValue" SG_ 653 DCM_FR_MirrorTiltHorizontalPos 254;
BA_ "GenSigStartValue" SG_ 653 DCM_FR_MirrorTiltVerticalPos 254;
BA_ "GenSigStartValue" SG_ 665 SCU_L_SeatMemoryBackPos 254;
BA_ "GenSigStartValue" SG_ 665 SCU_L_SeatMemorySlidePos 254;
BA_ "GenSigStartValue" SG_ 665 SCU_L_SeatMemoryHeightPos 254;
BA_ "GenSigStartValue" SG_ 710 IVI_StWLengthPos 254;
BA_ "GenSigStartValue" SG_ 710 IVI_StWAnglePos 254;
BA_ "GenSigStartValue" SG_ 915 MCU_TempCurrStrMax 255;
BA_ "GenSigStartValue" SG_ 915 MCU_TempCurrStr2 255;
BA_ "GenSigStartValue" SG_ 915 MCU_TempCurrStr1 255;
BA_ "GenSigStartValue" SG_ 915 MCU_TempCurrCool 255;
BA_ "GenSigStartValue" SG_ 992 BMS_DirveDiscSts 255;
BA_ "GenSigStartValue" SG_ 992 BMS_FeedEnergySts 255;
VAL_ 150 VCU_MCUActHeatPwr 254 "Init" 255 "Error" ;
VAL_ 257 CBM_BLE_CarSearchReq 0 "No Request" 1 "Request" ;
VAL_ 259 IVI_DrSeatWelcomeLevelSet 0 "NO Request" 1 "Low" 2 "High" 3 "Reserved" ;
VAL_ 259 IVI_DrSeatHeatLevelSet 0 "No Request" 1 "Seat Heat Off" 2 "Level1" 3 "Level2" 4 "Level3 0x5" 5 "Reserved" 6 "Reserved" 7 "Reserved" ;
VAL_ 259 IVI_L_DsSeatSlidePos 254 "No Request" 255 "OFF" ;
VAL_ 259 IVI_L_DsSeatHeightPos 254 "No Request" 255 "OFF" ;
VAL_ 259 IVI_L_DsSeatBackPos 254 "No Request" 255 "OFF" ;
VAL_ 260 IVI_PsSeatWelcomeLevelSet 0 "NO Request" 1 "Low" 2 "High" 3 "Reserved" ;
VAL_ 260 IVI_PassSeatHeatLevelSet 0 "No Request" 1 "Seat Heat Off" 2 "Level1" 3 "Level2" 4 "Level3 0x5" 5 "Reserved" 6 "Reserved" 7 "Reserved" ;
VAL_ 260 IVI_R_DsSeatBackPos 254 "No Request" 255 "OFF" ;
VAL_ 260 IVI_R_DsSeatHeightPos 254 "No Request" 255 "OFF" ;
VAL_ 260 IVI_R_DsSeatSlidePos 254 "No Request" 255 "OFF" ;
VAL_ 262 IVI_HUDScreenBrightnessSet 0 "0Level" 1 "1Level" 2 "2Level" 3 "3Level" 4 "4Level" 5 "5Level" 6 "6Level" 7 "7Level" 8 "8Level" 9 "9Level" 10 "10Level 0xB" 11 "Reserved 0x1F: Invalid" 12 "Reserved 0x1F: Invalid" 13 "Reserved 0x1F: Invalid" 14 "Reserved 0x1F: Invalid" 15 "Reserved 0x1F: Invalid" 16 "Reserved 0x1F: Invalid" 17 "Reserved 0x1F: Invalid" 18 "Reserved 0x1F: Invalid" 19 "Reserved 0x1F: Invalid" 20 "Reserved 0x1F: Invalid" 21 "Reserved 0x1F: Invalid" 22 "Reserved 0x1F: Invalid" 23 "Reserved 0x1F: Invalid" 24 "Reserved 0x1F: Invalid" 25 "Reserved 0x1F: Invalid" 26 "Reserved 0x1F: Invalid" 27 "Reserved 0x1F: Invalid" 28 "Reserved 0x1F: Invalid" 29 "Reserved 0x1F: Invalid" 30 "Reserved 0x1F: Invalid" 31 "Invalid" ;
VAL_ 264 SGW_FR_FrontRearReq 0 "Noactive" 1 "Front" 2 "Rear" ;
VAL_ 264 SGW_FR_HeightMotorReq 0 "Noactive" 1 "Up" 2 "Down" ;
VAL_ 264 SGW_FR_BackrestMotorReq 0 "Noactive" 1 "Front" 2 "Rear" ;
VAL_ 267 BCM_CentralLockFeedback 0 "Locking Fail Outside" 1 "Locking Success Outside" 2 "Unlocking Fail Outside" 3 "Unlocking Success Outside" ;
VAL_ 267 BCM_LVonReqKeyNotInCar 0 "NO_WARNING" 1 "WARNING" ;
VAL_ 268 SGW_PENFCAuthSt 0 "NotAutheduthFailed" 1 "AuthSuccessed" ;
VAL_ 268 SGW_GetNFCKeyCardsReq 0 "No Request" 1 "Get_All_KeyInfo" ;
VAL_ 268 SGW_NFCPairModeReq 0 "Disable" 1 "Enable" ;
VAL_ 271 Switches_L_SWipe_Cmd 0 "No Request" 1 "Fully Swipe From Top To Bottomreserved" 2 "Fully Swipe From Bottom To Topreserved" 3 "Semi Swipe From Top To Bottomreserved" 4 "Fully Swipe From Left To Right" 5 "Semi Swipe From Left To Center" 6 "Semi Swipe From Center To Right" 7 "Fully Swipe From Right To Left" 8 "Semi Swipe From Right To Center" 9 "Semi Swipe From Center To Left 0xA" 10 "Reserved" 11 "Reserved" 12 "Reserved" 13 "Reserved" 14 "Reserved" 15 "Reserved" ;
VAL_ 289 VCU_Enable_DC_Relay 0 "Close Request" 1 "Open Request" ;
VAL_ 289 VCU_OBC_Control_of_S2_SW 0 "Close" 1 "Open" ;
VAL_ 289 VCU_OBC_Control_of_em_lock 0 "Close" 1 "Open" ;
VAL_ 289 VCU_EnableOBC 0 "Reserve" 1 "Reserve" 2 "Enable" 3 "Disable" ;
VAL_ 311 DCM_RL_PriorSoundReq 0 "No request" 1 "Enable" ;
VAL_ 312 DCM_RR_PriorSoundReq 0 "No request" 1 "Enable" ;
VAL_ 316 SGW_R_MirrorTiltVerticalPos 254 "No Request 1" 255 "OFF" ;
VAL_ 316 SGW_R_MirrorTiltHorizontalPos 254 "No Request 9xFF OFF" ;
VAL_ 316 SGW_L_MirrorTiltVerticalPos 254 "No Request 8xFF OFF" ;
VAL_ 316 SGW_L_MirrorTiltHorizontalPos 254 "No Request 7xFF OFF" ;
VAL_ 316 SGW_R_MirrorMainVerticalPos 254 "No Request 6xFF OFF" ;
VAL_ 316 SGW_R_MirrorMainHorizontalPos 254 "No Request 5xFF OFF" ;
VAL_ 316 SGW_L_MirrorMainVerticalPos 254 "No Request 4xFF OFF" ;
VAL_ 316 SGW_L_MirrorMainHorizontalPos 254 "No Request 3xFF OFF" ;
VAL_ 512 ERA_ECallSts 0 "No display" 1 "Calling the operator" 2 "Call in progress" 3 "Call ended" ;
VAL_ 512 ERA_TestModeSts 0 "No request" 1 "Test normal mode" 2 "Test abnormal mode" 3 "Reserved" ;
VAL_ 512 ERA_SelfTestSts 0 "Normal" 1 "Abnormal" ;
VAL_ 515 ADCU_LDW_SYS_Sts 0 "Off" 1 "Standby" 2 "Active" 3 "Warning" 4 "Failure 0x5" 5 "Reserved" 6 "Reserved" 7 "Reserved" ;
VAL_ 515 ADCU_RightLaneVisualizationSts 0 "No display" 1 "Line not detected" 2 "Line detected" 3 "Lane Centering Assist" 4 "Warning" 5 "Suppression" ;
VAL_ 515 ADCU_LDWWarningModeState 0 "Only Vision" 1 "VisionVoice" 2 "VisionVibration" 3 "VisionVoiceVibration" 4 "Invalid 0x5" 5 "Reserved" 6 "Reserved" 7 "Reserved" ;
VAL_ 515 ADCU_LeftLaneVisualizationSts 0 "No display" 1 "Line not detected" 2 "Line detected" 3 "Lane Centering Assist" 4 "Warning" 5 "Suppression" ;
VAL_ 531 BMS_ChargeRequest 0 "Invalid" 1 "Heat Request only" 2 "Heat And Charge Request" 3 "Charge Only" 4 "Cool And Charge Request" ;
VAL_ 531 BMS_AbortErrorVoltage 0 "Normal" 1 "Abnormal" 2 "Untrustable" ;
VAL_ 531 BMS_ChagComplete 0 "Normal Completion" 1 "Abnormal completion" 2 "Untrustable" 3 "During Charging" ;
VAL_ 531 BMS_AbortFaultBMSTemp 0 "Normal" 1 "Over temp" 2 "Untrustable" ;
VAL_ 531 BMS_AbortFaultBatteryTemp 0 "Normal" 1 "Over temp" 2 "Untrustable" ;
VAL_ 531 BMS_AbortErrorCurrent 0 "Normal" 1 "Over current" 2 "Untrustable" ;
VAL_ 531 BMS_AbortAchivesetValue 0 "Not reached" 1 "Reached" 2 "Untrustable" ;
VAL_ 531 BMS_DCChgMode 0 "Ready" 1 "Constant voltage" 2 "Constant current" ;
VAL_ 531 BMS_AbortAchiveSingleVolt 0 "Not reached" 1 "Reached" 2 "Untrustable" ;
VAL_ 531 BMS_AbortAchiveTotalVolt 0 "Not reached" 1 "Reached" 2 "Untrustable" ;
VAL_ 544 VCU_RequestedModeDCDC 0 "OFF" 1 "Buck" 2 "Disable" ;
VAL_ 544 VCU_VoltageDemandLV 510 "Init" 511 "Error" ;
VAL_ 547 VCU_ForwardVmaxlimitStatus 0 "Inactive" 1 "Active" ;
VAL_ 547 VCU_ManuallyUnlockComment 0 "False" 1 "True" ;
VAL_ 561 IVI_CRLevelSet 0 "No request" 1 "OFF" 2 "Primary energy recovery weak" 3 "Secondary energy recoverymedium" 4 "Tertiary energy recovery strong 0x5" 5 "Reserved" 6 "Reserved" 7 "Reserved" ;
VAL_ 561 IVI_HDCOffSet 0 "No Request" 1 "OFF" 2 "ON" 3 "RESERVED" ;
VAL_ 561 IVI_AVHSet 0 "No Request" 1 "OFF" 2 "ON" 3 "RESERVED" ;
VAL_ 561 IVI_SteeringModeSet 0 "No Request" 1 "Normal" 2 "Sport" 3 "Comfort" ;
VAL_ 561 IVI_BrakeCompensateCmd 0 "NO Request" 1 "OFF" 2 "ON" 3 "Reserved" ;
VAL_ 561 IVI_ESCOffSet 0 "NO Request" 1 "OFF" 2 "ON" 3 "Reserved" ;
VAL_ 561 IVI_TPMS_Reset 0 "No request" 1 "Active" ;
VAL_ 569 SGW_RoleAccessSts 0 "Driving allowed" 1 "Driving NOT allowed" ;
VAL_ 569 SGW_FaceIDAuthenticationSuccess 0 "AuthenticationFailed" 1 "AuthenticationSuccess" ;
VAL_ 569 SGW_ImmobilizingEnable 0 "No request" 1 "Disable" 2 "Enable" ;
VAL_ 574 IVI_PassWindowLockSet 0 "NO Request" 1 "UNLOCK" 2 "LOCK" 3 "Reserved" ;
VAL_ 574 IVI_RRDoorLockSet 0 "No Request" 1 "UNLOCK" 2 "LOCK" 3 "Reserved" ;
VAL_ 574 IVI_FLDoorLockSet 0 "No Request" 1 "UNLOCK" 2 "LOCK" 3 "Reserved" ;
VAL_ 574 IVI_FRDoorLockSet 0 "No Request" 1 "UNLOCK" 2 "LOCK" 3 "Reserved" ;
VAL_ 574 IVI_RLDoorLockSet 0 "No Request" 1 "UNLOCK" 2 "LOCK" 3 "Reserved" ;
VAL_ 574 IVI_ModeEnterReq 0 "No request" 1 "Ventilation mode" 2 "Close mode 0x3" 3 "Reserved" 4 "Reserved" 5 "Reserved" 6 "Reserved" 7 "Reserved" 8 "Reserved" 9 "Reserved" 10 "Reserved" 11 "Reserved" 12 "Reserved" 13 "Reserved" 14 "Reserved" 15 "Reserved" ;
VAL_ 575 SGW_MirrorAutoTurnDownSet 0 "NO Request" 1 "OFF" 2 "ON" 3 "INVALID" ;
VAL_ 575 SGW_WelcomeOnOffSet 0 "Default" 1 "OFF" 2 "ON" 3 "INVALID" ;
VAL_ 575 SGW_PassWelcomeOnOffSet 0 "Default" 1 "OFF" 2 "ON" 3 "INVALID" ;
VAL_ 575 SGW_DrSeatWelcomeLevelSet 0 "NO Request" 1 "Low" 2 "High" 3 "INVALID" ;
VAL_ 575 SGW_PsSeatWelcomeLevelSet 0 "NO Request" 1 "Low" 2 "High" 3 "INVALID" ;
VAL_ 575 SGW_L_RearSeatHeatSet 0 "No Request" 1 "OFF" 2 "ON" 3 "INVALID" ;
VAL_ 575 SGW_R_RearSeatHeatSet 0 "No Request" 1 "OFF" 2 "ON" 3 "INVALID" ;
VAL_ 577 POD_T15e_fault 0 "No Fault" 1 "Fault" ;
VAL_ 577 POD_CANBusoff 0 "No Fault" 1 "Fault" ;
VAL_ 577 POD_TempHighFault 0 "No Fault" 1 "Fault" ;
VAL_ 577 POD_TempSensor1Fault 0 "No Fault" 1 "Fault" ;
VAL_ 577 POD_KL30Error 0 "No Fault" 1 "Fault" ;
VAL_ 577 POD_DCPosRelayState 0 "Close" 1 "Open" 2 "Error" ;
VAL_ 577 POD_DCPortInletTempAValid 0 "Damage" 1 "Short Circuit" 2 "normal" ;
VAL_ 577 POD_DCPortInletTempBValid 0 "Damage" 1 "Short Circuit" 2 "normal" ;
VAL_ 578 POD_DCDC_WorkMode 0 "Init" 1 "Standby" 2 "Buck" 3 "Fault" 4 "sleep" ;
VAL_ 610 TCU_CabinTemperatureValid 0 "Invalid" 1 "Valid" ;
VAL_ 614 EVCOM_ActlOprtMode 0 "off" 1 "running" 2 "limit" 3 "pre_heat" 4 "fault 0x5" 5 "reserved" 6 "reserved" 7 "reserved" ;
VAL_ 614 EVCOM_OverPwrDropFreqError 0 "No Error" 1 "Error" ;
VAL_ 614 EVCOM_OverCurDropFreqError 0 "No Error" 1 "Error" ;
VAL_ 614 EVCOM_CommunicationError 0 "No Error" 1 "Error" ;
VAL_ 614 EVCOM_StandByUnderVolError 0 "No Error" 1 "Error" ;
VAL_ 614 EVCOM_StandByOverVolError 0 "No Error" 1 "Error" ;
VAL_ 614 EVCOM_UnderVoltageError 0 "No Error" 1 "Error" ;
VAL_ 614 EVCOM_OverVoltageError 0 "No Error" 1 "Error" ;
VAL_ 614 EVCOM_OverCurrentError 0 "No Error" 1 "Error" ;
VAL_ 624 BCM_ALM1_MusicFrequencySts 0 "OFF" 1 "ON" ;
VAL_ 624 BCM_ALM2_MusicFrequencySts 0 "OFF" 1 "ON" ;
VAL_ 626 BCM_Immo_State 0 "Disable immo" 1 "Enable immo" ;
VAL_ 646 DCM_FL_AmbientLiAniSts 0 "Reserved" 1 "Animation 1" 2 "Animation 2" 3 "Animation 3" 4 "Animation 4" 5 "Animation 5" 6 "Animation 6" 7 "Animation 7" 8 "Animation 8" 9 "Animation 9" 10 "Animation 10" 11 "Animation 11" 12 "Animation 12" 13 "Animation 13" 14 "Animation 14" 15 "Animation 15" 16 "Animation 16" 17 "Animation 17" 18 "Animation 18" 19 "Animation 19" 20 "Animation 20" 21 "Animation 21" 22 "Animation 22" 23 "Animation 23" 24 "Animation 24" 25 "Animation 25" ;
VAL_ 646 DCM_FL_AmbientLightColorSts 0 "Colour1" 1 "Colour2" 2 "Colour3" 3 "Colour4" 4 "Colour5" 5 "Colour6" 6 "Colour7" 7 "Colour8" 8 "Colour9" 9 "Colour10" 10 "Colour11" 11 "Colour12" 12 "Colour13" 13 "Colour14" 14 "Colour15" 15 "Colour16" 16 "Colour17" 17 "Colour18" 18 "Colour19" 19 "Colour20" 20 "Colour21" 21 "Colour22" 22 "Colour23" 23 "Colour24" 24 "Colour25" 25 "Colour26" 26 "Colour27" 27 "Colour28" 28 "Colour29" 29 "Colour30" 30 "Colour31" 31 "Colour32" 32 "Colour33" 33 "Colour34" 34 "Colour35" 35 "Colour36" 36 "Colour37" 37 "Colour38" 38 "Colour39" 39 "Colour40" 40 "Colour41" 41 "Colour42" 42 "Colour43" 43 "Colour44" 44 "Colour45" 45 "Colour46" 46 "Colour47" 47 "Colour48" 48 "Colour49" 49 "Colour50" 50 "Colour51" 51 "Colour52" 52 "Colour53" 53 "Colour54" 54 "Colour55" 55 "Colour56" 56 "Colour57" 57 "Colour58" 58 "Colour59" 59 "Colour60" 60 "Colour61" 61 "Colour62" 62 "Colour63" 63 "Colour64 0x40" 64 "Reserved" 65 "Reserved" 66 "Reserved" 67 "Reserved" 68 "Reserved" 69 "Reserved" 70 "Reserved" 71 "Reserved" 72 "Reserved" 73 "Reserved" 74 "Reserved" 75 "Reserved" 76 "Reserved" 77 "Reserved" 78 "Reserved" 79 "Reserved" 80 "Reserved" 81 "Reserved" 82 "Reserved" 83 "Reserved" 84 "Reserved" 85 "Reserved" 86 "Reserved" 87 "Reserved" 88 "Reserved" 89 "Reserved" 90 "Reserved" 91 "Reserved" 92 "Reserved" 93 "Reserved" 94 "Reserved" 95 "Reserved" 96 "Reserved" 97 "Reserved" 98 "Reserved" 99 "Reserved" 100 "Reserved" 101 "Reserved" 102 "Reserved" 103 "Reserved" 104 "Reserved" 105 "Reserved" 106 "Reserved" 107 "Reserved" 108 "Reserved" 109 "Reserved" 110 "Reserved" 111 "Reserved" 112 "Reserved" 113 "Reserved" 114 "Reserved" 115 "Reserved" 116 "Reserved" 117 "Reserved" 118 "Reserved" 119 "Reserved" 120 "Reserved" 121 "Reserved" 122 "Reserved" 123 "Reserved" 124 "Reserved" 125 "Reserved" 126 "Reserved" 127 "Reserved" 128 "Reserved" 129 "Reserved" 130 "Reserved" 131 "Reserved" 132 "Reserved" 133 "Reserved" 134 "Reserved" 135 "Reserved" 136 "Reserved" 137 "Reserved" 138 "Reserved" 139 "Reserved" 140 "Reserved" 141 "Reserved" 142 "Reserved" 143 "Reserved" 144 "Reserved" 145 "Reserved" 146 "Reserved" 147 "Reserved" 148 "Reserved" 149 "Reserved" 150 "Reserved" 151 "Reserved" 152 "Reserved" 153 "Reserved" 154 "Reserved" 155 "Reserved" 156 "Reserved" 157 "Reserved" 158 "Reserved" 159 "Reserved" 160 "Reserved" 161 "Reserved" 162 "Reserved" 163 "Reserved" 164 "Reserved" 165 "Reserved" 166 "Reserved" 167 "Reserved" 168 "Reserved" 169 "Reserved" 170 "Reserved" 171 "Reserved" 172 "Reserved" 173 "Reserved" 174 "Reserved" 175 "Reserved" 176 "Reserved" 177 "Reserved" 178 "Reserved" 179 "Reserved" 180 "Reserved" 181 "Reserved" 182 "Reserved" 183 "Reserved" 184 "Reserved" 185 "Reserved" 186 "Reserved" 187 "Reserved" 188 "Reserved" 189 "Reserved" 190 "Reserved" 191 "Reserved" 192 "Reserved" 193 "Reserved" 194 "Reserved" 195 "Reserved" 196 "Reserved" 197 "Reserved" 198 "Reserved" 199 "Reserved" 200 "Reserved" 201 "Reserved" 202 "Reserved" 203 "Reserved" 204 "Reserved" 205 "Reserved" 206 "Reserved" 207 "Reserved" 208 "Reserved" 209 "Reserved" 210 "Reserved" 211 "Reserved" 212 "Reserved" 213 "Reserved" 214 "Reserved" 215 "Reserved" 216 "Reserved" 217 "Reserved" 218 "Reserved" 219 "Reserved" 220 "Reserved" 221 "Reserved" 222 "Reserved" 223 "Reserved" 224 "Reserved" 225 "Reserved" 226 "Reserved" 227 "Reserved" 228 "Reserved" 229 "Reserved" 230 "Reserved" 231 "Reserved" 232 "Reserved" 233 "Reserved" 234 "Reserved" 235 "Reserved" 236 "Reserved" 237 "Reserved" 238 "Reserved" 239 "Reserved" 240 "Reserved" 241 "Reserved" 242 "Reserved" 243 "Reserved" 244 "Reserved" 245 "Reserved" 246 "Reserved" 247 "Reserved" 248 "Reserved" 249 "Reserved" 250 "Reserved" 251 "Reserved" 252 "Reserved" 253 "Reserved" 254 "Reserved" 255 "Reserved" ;
VAL_ 646 DCM_FL_AmbientLightSts 0 "OFF" 1 "ON" ;
VAL_ 646 DCM_FL_AmbientLightBrightSts 0 "Reserved" 1 "LV1" 2 "LV2" 3 "LV3" 4 "LV4" 5 "LV5_NORMAL" 6 "LV6" 7 "LV7" 8 "LV8" 9 "LV9" 10 "LV10" ;
VAL_ 646 DCM_ALM_FL_MusicFrequencySts 0 "OFF" 1 "ON" ;
VAL_ 647 DCM_FR_AmbientLiAniSts 0 "Reserved" 1 "Animation 1" 2 "Animation 2" 3 "Animation 3" 4 "Animation 4" 5 "Animation 5" 6 "Animation 6" 7 "Animation 7" 8 "Animation 8" 9 "Animation 9" 10 "Animation 10" 11 "Animation 11" 12 "Animation 12" 13 "Animation 13" 14 "Animation 14" 15 "Animation 15" 16 "Animation 16" 17 "Animation 17" 18 "Animation 18" 19 "Animation 19" 20 "Animation 20" 21 "Animation 21" 22 "Animation 22" 23 "Animation 23" 24 "Animation 24" 25 "Animation 25" ;
VAL_ 647 DCM_FR_AmbientLightColorSts 0 "Colour1" 1 "Colour2" 2 "Colour3" 3 "Colour4" 4 "Colour5" 5 "Colour6" 6 "Colour7" 7 "Colour8" 8 "Colour9" 9 "Colour10" 10 "Colour11" 11 "Colour12" 12 "Colour13" 13 "Colour14" 14 "Colour15" 15 "Colour16" 16 "Colour17" 17 "Colour18" 18 "Colour19" 19 "Colour20" 20 "Colour21" 21 "Colour22" 22 "Colour23" 23 "Colour24" 24 "Colour25" 25 "Colour26" 26 "Colour27" 27 "Colour28" 28 "Colour29" 29 "Colour30" 30 "Colour31" 31 "Colour32" 32 "Colour33" 33 "Colour34" 34 "Colour35" 35 "Colour36" 36 "Colour37" 37 "Colour38" 38 "Colour39" 39 "Colour40" 40 "Colour41" 41 "Colour42" 42 "Colour43" 43 "Colour44" 44 "Colour45" 45 "Colour46" 46 "Colour47" 47 "Colour48" 48 "Colour49" 49 "Colour50" 50 "Colour51" 51 "Colour52" 52 "Colour53" 53 "Colour54" 54 "Colour55" 55 "Colour56" 56 "Colour57" 57 "Colour58" 58 "Colour59" 59 "Colour60" 60 "Colour61" 61 "Colour62" 62 "Colour63" 63 "Colour64 0x40" 64 "Reserved" 65 "Reserved" 66 "Reserved" 67 "Reserved" 68 "Reserved" 69 "Reserved" 70 "Reserved" 71 "Reserved" 72 "Reserved" 73 "Reserved" 74 "Reserved" 75 "Reserved" 76 "Reserved" 77 "Reserved" 78 "Reserved" 79 "Reserved" 80 "Reserved" 81 "Reserved" 82 "Reserved" 83 "Reserved" 84 "Reserved" 85 "Reserved" 86 "Reserved" 87 "Reserved" 88 "Reserved" 89 "Reserved" 90 "Reserved" 91 "Reserved" 92 "Reserved" 93 "Reserved" 94 "Reserved" 95 "Reserved" 96 "Reserved" 97 "Reserved" 98 "Reserved" 99 "Reserved" 100 "Reserved" 101 "Reserved" 102 "Reserved" 103 "Reserved" 104 "Reserved" 105 "Reserved" 106 "Reserved" 107 "Reserved" 108 "Reserved" 109 "Reserved" 110 "Reserved" 111 "Reserved" 112 "Reserved" 113 "Reserved" 114 "Reserved" 115 "Reserved" 116 "Reserved" 117 "Reserved" 118 "Reserved" 119 "Reserved" 120 "Reserved" 121 "Reserved" 122 "Reserved" 123 "Reserved" 124 "Reserved" 125 "Reserved" 126 "Reserved" 127 "Reserved" 128 "Reserved" 129 "Reserved" 130 "Reserved" 131 "Reserved" 132 "Reserved" 133 "Reserved" 134 "Reserved" 135 "Reserved" 136 "Reserved" 137 "Reserved" 138 "Reserved" 139 "Reserved" 140 "Reserved" 141 "Reserved" 142 "Reserved" 143 "Reserved" 144 "Reserved" 145 "Reserved" 146 "Reserved" 147 "Reserved" 148 "Reserved" 149 "Reserved" 150 "Reserved" 151 "Reserved" 152 "Reserved" 153 "Reserved" 154 "Reserved" 155 "Reserved" 156 "Reserved" 157 "Reserved" 158 "Reserved" 159 "Reserved" 160 "Reserved" 161 "Reserved" 162 "Reserved" 163 "Reserved" 164 "Reserved" 165 "Reserved" 166 "Reserved" 167 "Reserved" 168 "Reserved" 169 "Reserved" 170 "Reserved" 171 "Reserved" 172 "Reserved" 173 "Reserved" 174 "Reserved" 175 "Reserved" 176 "Reserved" 177 "Reserved" 178 "Reserved" 179 "Reserved" 180 "Reserved" 181 "Reserved" 182 "Reserved" 183 "Reserved" 184 "Reserved" 185 "Reserved" 186 "Reserved" 187 "Reserved" 188 "Reserved" 189 "Reserved" 190 "Reserved" 191 "Reserved" 192 "Reserved" 193 "Reserved" 194 "Reserved" 195 "Reserved" 196 "Reserved" 197 "Reserved" 198 "Reserved" 199 "Reserved" 200 "Reserved" 201 "Reserved" 202 "Reserved" 203 "Reserved" 204 "Reserved" 205 "Reserved" 206 "Reserved" 207 "Reserved" 208 "Reserved" 209 "Reserved" 210 "Reserved" 211 "Reserved" 212 "Reserved" 213 "Reserved" 214 "Reserved" 215 "Reserved" 216 "Reserved" 217 "Reserved" 218 "Reserved" 219 "Reserved" 220 "Reserved" 221 "Reserved" 222 "Reserved" 223 "Reserved" 224 "Reserved" 225 "Reserved" 226 "Reserved" 227 "Reserved" 228 "Reserved" 229 "Reserved" 230 "Reserved" 231 "Reserved" 232 "Reserved" 233 "Reserved" 234 "Reserved" 235 "Reserved" 236 "Reserved" 237 "Reserved" 238 "Reserved" 239 "Reserved" 240 "Reserved" 241 "Reserved" 242 "Reserved" 243 "Reserved" 244 "Reserved" 245 "Reserved" 246 "Reserved" 247 "Reserved" 248 "Reserved" 249 "Reserved" 250 "Reserved" 251 "Reserved" 252 "Reserved" 253 "Reserved" 254 "Reserved" 255 "Reserved" ;
VAL_ 647 DCM_FR_AmbientLightSts 0 "OFF" 1 "ON" ;
VAL_ 647 DCM_FR_AmbientLightBrightSts 0 "Reserved" 1 "LV1" 2 "LV2" 3 "LV3" 4 "LV4" 5 "LV5_NORMAL" 6 "LV6" 7 "LV7" 8 "LV8" 9 "LV9" 10 "LV10" ;
VAL_ 647 DCM_ALM_FR_MusicFrequencySts 0 "OFF" 1 "ON" ;
VAL_ 648 DCM_RL_AmbientLiAniSts 0 "Reserved" 1 "Animation 1" 2 "Animation 2" 3 "Animation 3" 4 "Animation 4" 5 "Animation 5" 6 "Animation 6" 7 "Animation 7" 8 "Animation 8" 9 "Animation 9" 10 "Animation 10" 11 "Animation 11" 12 "Animation 12" 13 "Animation 13" 14 "Animation 14" 15 "Animation 15" 16 "Animation 16" 17 "Animation 17" 18 "Animation 18" 19 "Animation 19" 20 "Animation 20" 21 "Animation 21" 22 "Animation 22" 23 "Animation 23" 24 "Animation 24" 25 "Animation 25" ;
VAL_ 648 DCM_RL_AmbientLightColorSts 0 "Colour1" 1 "Colour2" 2 "Colour3" 3 "Colour4" 4 "Colour5" 5 "Colour6" 6 "Colour7" 7 "Colour8" 8 "Colour9" 9 "Colour10" 10 "Colour11" 11 "Colour12" 12 "Colour13" 13 "Colour14" 14 "Colour15" 15 "Colour16" 16 "Colour17" 17 "Colour18" 18 "Colour19" 19 "Colour20" 20 "Colour21" 21 "Colour22" 22 "Colour23" 23 "Colour24" 24 "Colour25" 25 "Colour26" 26 "Colour27" 27 "Colour28" 28 "Colour29" 29 "Colour30" 30 "Colour31" 31 "Colour32" 32 "Colour33" 33 "Colour34" 34 "Colour35" 35 "Colour36" 36 "Colour37" 37 "Colour38" 38 "Colour39" 39 "Colour40" 40 "Colour41" 41 "Colour42" 42 "Colour43" 43 "Colour44" 44 "Colour45" 45 "Colour46" 46 "Colour47" 47 "Colour48" 48 "Colour49" 49 "Colour50" 50 "Colour51" 51 "Colour52" 52 "Colour53" 53 "Colour54" 54 "Colour55" 55 "Colour56" 56 "Colour57" 57 "Colour58" 58 "Colour59" 59 "Colour60" 60 "Colour61" 61 "Colour62" 62 "Colour63" 63 "Colour64 0x40" 64 "Reserved" 65 "Reserved" 66 "Reserved" 67 "Reserved" 68 "Reserved" 69 "Reserved" 70 "Reserved" 71 "Reserved" 72 "Reserved" 73 "Reserved" 74 "Reserved" 75 "Reserved" 76 "Reserved" 77 "Reserved" 78 "Reserved" 79 "Reserved" 80 "Reserved" 81 "Reserved" 82 "Reserved" 83 "Reserved" 84 "Reserved" 85 "Reserved" 86 "Reserved" 87 "Reserved" 88 "Reserved" 89 "Reserved" 90 "Reserved" 91 "Reserved" 92 "Reserved" 93 "Reserved" 94 "Reserved" 95 "Reserved" 96 "Reserved" 97 "Reserved" 98 "Reserved" 99 "Reserved" 100 "Reserved" 101 "Reserved" 102 "Reserved" 103 "Reserved" 104 "Reserved" 105 "Reserved" 106 "Reserved" 107 "Reserved" 108 "Reserved" 109 "Reserved" 110 "Reserved" 111 "Reserved" 112 "Reserved" 113 "Reserved" 114 "Reserved" 115 "Reserved" 116 "Reserved" 117 "Reserved" 118 "Reserved" 119 "Reserved" 120 "Reserved" 121 "Reserved" 122 "Reserved" 123 "Reserved" 124 "Reserved" 125 "Reserved" 126 "Reserved" 127 "Reserved" 128 "Reserved" 129 "Reserved" 130 "Reserved" 131 "Reserved" 132 "Reserved" 133 "Reserved" 134 "Reserved" 135 "Reserved" 136 "Reserved" 137 "Reserved" 138 "Reserved" 139 "Reserved" 140 "Reserved" 141 "Reserved" 142 "Reserved" 143 "Reserved" 144 "Reserved" 145 "Reserved" 146 "Reserved" 147 "Reserved" 148 "Reserved" 149 "Reserved" 150 "Reserved" 151 "Reserved" 152 "Reserved" 153 "Reserved" 154 "Reserved" 155 "Reserved" 156 "Reserved" 157 "Reserved" 158 "Reserved" 159 "Reserved" 160 "Reserved" 161 "Reserved" 162 "Reserved" 163 "Reserved" 164 "Reserved" 165 "Reserved" 166 "Reserved" 167 "Reserved" 168 "Reserved" 169 "Reserved" 170 "Reserved" 171 "Reserved" 172 "Reserved" 173 "Reserved" 174 "Reserved" 175 "Reserved" 176 "Reserved" 177 "Reserved" 178 "Reserved" 179 "Reserved" 180 "Reserved" 181 "Reserved" 182 "Reserved" 183 "Reserved" 184 "Reserved" 185 "Reserved" 186 "Reserved" 187 "Reserved" 188 "Reserved" 189 "Reserved" 190 "Reserved" 191 "Reserved" 192 "Reserved" 193 "Reserved" 194 "Reserved" 195 "Reserved" 196 "Reserved" 197 "Reserved" 198 "Reserved" 199 "Reserved" 200 "Reserved" 201 "Reserved" 202 "Reserved" 203 "Reserved" 204 "Reserved" 205 "Reserved" 206 "Reserved" 207 "Reserved" 208 "Reserved" 209 "Reserved" 210 "Reserved" 211 "Reserved" 212 "Reserved" 213 "Reserved" 214 "Reserved" 215 "Reserved" 216 "Reserved" 217 "Reserved" 218 "Reserved" 219 "Reserved" 220 "Reserved" 221 "Reserved" 222 "Reserved" 223 "Reserved" 224 "Reserved" 225 "Reserved" 226 "Reserved" 227 "Reserved" 228 "Reserved" 229 "Reserved" 230 "Reserved" 231 "Reserved" 232 "Reserved" 233 "Reserved" 234 "Reserved" 235 "Reserved" 236 "Reserved" 237 "Reserved" 238 "Reserved" 239 "Reserved" 240 "Reserved" 241 "Reserved" 242 "Reserved" 243 "Reserved" 244 "Reserved" 245 "Reserved" 246 "Reserved" 247 "Reserved" 248 "Reserved" 249 "Reserved" 250 "Reserved" 251 "Reserved" 252 "Reserved" 253 "Reserved" 254 "Reserved" 255 "Reserved" ;
VAL_ 648 DCM_RL_AmbientLightSts 0 "OFF" 1 "ON" ;
VAL_ 648 DCM_RL_AmbientLightBrightSts 0 "Reserved" 1 "LV1" 2 "LV2" 3 "LV3" 4 "LV4" 5 "LV5_NORMAL" 6 "LV6" 7 "LV7" 8 "LV8" 9 "LV9" 10 "LV10" ;
VAL_ 648 DCM_ALM_RL_MusicFrequencySts 0 "OFF" 1 "ON" ;
VAL_ 649 DCM_RR_AmbientLiAniSts 0 "Reserved" 1 "Animation 1" 2 "Animation 2" 3 "Animation 3" 4 "Animation 4" 5 "Animation 5" 6 "Animation 6" 7 "Animation 7" 8 "Animation 8" 9 "Animation 9" 10 "Animation 10" 11 "Animation 11" 12 "Animation 12" 13 "Animation 13" 14 "Animation 14" 15 "Animation 15" 16 "Animation 16" 17 "Animation 17" 18 "Animation 18" 19 "Animation 19" 20 "Animation 20" 21 "Animation 21" 22 "Animation 22" 23 "Animation 23" 24 "Animation 24" 25 "Animation 25" ;
VAL_ 649 DCM_RR_AmbientLightColorSts 0 "Colour1" 1 "Colour2" 2 "Colour3" 3 "Colour4" 4 "Colour5" 5 "Colour6" 6 "Colour7" 7 "Colour8" 8 "Colour9" 9 "Colour10" 10 "Colour11" 11 "Colour12" 12 "Colour13" 13 "Colour14" 14 "Colour15" 15 "Colour16" 16 "Colour17" 17 "Colour18" 18 "Colour19" 19 "Colour20" 20 "Colour21" 21 "Colour22" 22 "Colour23" 23 "Colour24" 24 "Colour25" 25 "Colour26" 26 "Colour27" 27 "Colour28" 28 "Colour29" 29 "Colour30" 30 "Colour31" 31 "Colour32" 32 "Colour33" 33 "Colour34" 34 "Colour35" 35 "Colour36" 36 "Colour37" 37 "Colour38" 38 "Colour39" 39 "Colour40" 40 "Colour41" 41 "Colour42" 42 "Colour43" 43 "Colour44" 44 "Colour45" 45 "Colour46" 46 "Colour47" 47 "Colour48" 48 "Colour49" 49 "Colour50" 50 "Colour51" 51 "Colour52" 52 "Colour53" 53 "Colour54" 54 "Colour55" 55 "Colour56" 56 "Colour57" 57 "Colour58" 58 "Colour59" 59 "Colour60" 60 "Colour61" 61 "Colour62" 62 "Colour63" 63 "Colour64 0x40" 64 "Reserved" 65 "Reserved" 66 "Reserved" 67 "Reserved" 68 "Reserved" 69 "Reserved" 70 "Reserved" 71 "Reserved" 72 "Reserved" 73 "Reserved" 74 "Reserved" 75 "Reserved" 76 "Reserved" 77 "Reserved" 78 "Reserved" 79 "Reserved" 80 "Reserved" 81 "Reserved" 82 "Reserved" 83 "Reserved" 84 "Reserved" 85 "Reserved" 86 "Reserved" 87 "Reserved" 88 "Reserved" 89 "Reserved" 90 "Reserved" 91 "Reserved" 92 "Reserved" 93 "Reserved" 94 "Reserved" 95 "Reserved" 96 "Reserved" 97 "Reserved" 98 "Reserved" 99 "Reserved" 100 "Reserved" 101 "Reserved" 102 "Reserved" 103 "Reserved" 104 "Reserved" 105 "Reserved" 106 "Reserved" 107 "Reserved" 108 "Reserved" 109 "Reserved" 110 "Reserved" 111 "Reserved" 112 "Reserved" 113 "Reserved" 114 "Reserved" 115 "Reserved" 116 "Reserved" 117 "Reserved" 118 "Reserved" 119 "Reserved" 120 "Reserved" 121 "Reserved" 122 "Reserved" 123 "Reserved" 124 "Reserved" 125 "Reserved" 126 "Reserved" 127 "Reserved" 128 "Reserved" 129 "Reserved" 130 "Reserved" 131 "Reserved" 132 "Reserved" 133 "Reserved" 134 "Reserved" 135 "Reserved" 136 "Reserved" 137 "Reserved" 138 "Reserved" 139 "Reserved" 140 "Reserved" 141 "Reserved" 142 "Reserved" 143 "Reserved" 144 "Reserved" 145 "Reserved" 146 "Reserved" 147 "Reserved" 148 "Reserved" 149 "Reserved" 150 "Reserved" 151 "Reserved" 152 "Reserved" 153 "Reserved" 154 "Reserved" 155 "Reserved" 156 "Reserved" 157 "Reserved" 158 "Reserved" 159 "Reserved" 160 "Reserved" 161 "Reserved" 162 "Reserved" 163 "Reserved" 164 "Reserved" 165 "Reserved" 166 "Reserved" 167 "Reserved" 168 "Reserved" 169 "Reserved" 170 "Reserved" 171 "Reserved" 172 "Reserved" 173 "Reserved" 174 "Reserved" 175 "Reserved" 176 "Reserved" 177 "Reserved" 178 "Reserved" 179 "Reserved" 180 "Reserved" 181 "Reserved" 182 "Reserved" 183 "Reserved" 184 "Reserved" 185 "Reserved" 186 "Reserved" 187 "Reserved" 188 "Reserved" 189 "Reserved" 190 "Reserved" 191 "Reserved" 192 "Reserved" 193 "Reserved" 194 "Reserved" 195 "Reserved" 196 "Reserved" 197 "Reserved" 198 "Reserved" 199 "Reserved" 200 "Reserved" 201 "Reserved" 202 "Reserved" 203 "Reserved" 204 "Reserved" 205 "Reserved" 206 "Reserved" 207 "Reserved" 208 "Reserved" 209 "Reserved" 210 "Reserved" 211 "Reserved" 212 "Reserved" 213 "Reserved" 214 "Reserved" 215 "Reserved" 216 "Reserved" 217 "Reserved" 218 "Reserved" 219 "Reserved" 220 "Reserved" 221 "Reserved" 222 "Reserved" 223 "Reserved" 224 "Reserved" 225 "Reserved" 226 "Reserved" 227 "Reserved" 228 "Reserved" 229 "Reserved" 230 "Reserved" 231 "Reserved" 232 "Reserved" 233 "Reserved" 234 "Reserved" 235 "Reserved" 236 "Reserved" 237 "Reserved" 238 "Reserved" 239 "Reserved" 240 "Reserved" 241 "Reserved" 242 "Reserved" 243 "Reserved" 244 "Reserved" 245 "Reserved" 246 "Reserved" 247 "Reserved" 248 "Reserved" 249 "Reserved" 250 "Reserved" 251 "Reserved" 252 "Reserved" 253 "Reserved" 254 "Reserved" 255 "Reserved" ;
VAL_ 649 DCM_RR_AmbientLightSts 0 "OFF" 1 "ON" ;
VAL_ 649 DCM_RR_AmbientLightBrightSts 0 "Reserved" 1 "LV1" 2 "LV2" 3 "LV3" 4 "LV4" 5 "LV5_NORMAL" 6 "LV6" 7 "LV7" 8 "LV8" 9 "LV9" 10 "LV10" ;
VAL_ 649 DCM_ALM_RR_MusicFrequencySts 0 "OFF" 1 "ON" ;
VAL_ 663 WCBS1_ReminderSts 0 "Disabled" 1 "Enabled" ;
VAL_ 663 WCBS1_Reminder 0 "no warning" 1 "warning" ;
VAL_ 664 WCBS2_ReminderSts 0 "Disabled" 1 "Enabled" ;
VAL_ 664 WCBS2_Reminder 0 "no warning" 1 "warning" ;
VAL_ 689 IVI_HUDOnOffSet 0 "No Request" 1 "OFF" 2 "ON" 3 "RESERVED" ;
VAL_ 689 IVI_HUDALTITUDESet 0 "No request" 1 "-8 level" 2 "-7 level" 3 "-6 level" 4 "-5 level" 5 "-4 level" 6 "-3 level" 7 "-2 level" 8 "-1 level" 9 "0 level" 10 "1 level" 11 "2 level" 12 "3 level" 13 "4 level" 14 "5 level" 15 "6 level" 16 "7 level" 17 "8 level 0x12" 18 "reserved" 19 "reserved" 20 "reserved" 21 "reserved" 22 "reserved" 23 "reserved" 24 "reserved" 25 "reserved" 26 "reserved" 27 "reserved" 28 "reserved" 29 "reserved" 30 "reserved" 31 "reserved" 32 "reserved" 33 "reserved" 34 "reserved" 35 "reserved" 36 "reserved" 37 "reserved" 38 "reserved" 39 "reserved" 40 "reserved" 41 "reserved" 42 "reserved" 43 "reserved" 44 "reserved" 45 "reserved" 46 "reserved" 47 "reserved" 48 "reserved" 49 "reserved" 50 "reserved" 51 "reserved" 52 "reserved" 53 "reserved" 54 "reserved" 55 "reserved" 56 "reserved" 57 "reserved" 58 "reserved" 59 "reserved" 60 "reserved" 61 "reserved" 62 "reserved" 63 "reserved" 64 "reserved" 65 "reserved" 66 "reserved" 67 "reserved" 68 "reserved" 69 "reserved" 70 "reserved" 71 "reserved" 72 "reserved" 73 "reserved" 74 "reserved" 75 "reserved" 76 "reserved" 77 "reserved" 78 "reserved" 79 "reserved" 80 "reserved" 81 "reserved" 82 "reserved" 83 "reserved" 84 "reserved" 85 "reserved" 86 "reserved" 87 "reserved" 88 "reserved" 89 "reserved" 90 "reserved" 91 "reserved" 92 "reserved" 93 "reserved" 94 "reserved" 95 "reserved" 96 "reserved" 97 "reserved" 98 "reserved" 99 "reserved" 100 "reserved" 101 "reserved" 102 "reserved" 103 "reserved" 104 "reserved" 105 "reserved" 106 "reserved" 107 "reserved" 108 "reserved" 109 "reserved" 110 "reserved" 111 "reserved" 112 "reserved" 113 "reserved" 114 "reserved" 115 "reserved" 116 "reserved" 117 "reserved" 118 "reserved" 119 "reserved" 120 "reserved" 121 "reserved" 122 "reserved" 123 "reserved" 124 "reserved" 125 "reserved" 126 "reserved" 127 "reserved" 128 "reserved" 129 "reserved" 130 "reserved" 131 "reserved" 132 "reserved" 133 "reserved" 134 "reserved" 135 "reserved" 136 "reserved" 137 "reserved" 138 "reserved" 139 "reserved" 140 "reserved" 141 "reserved" 142 "reserved" 143 "reserved" 144 "reserved" 145 "reserved" 146 "reserved" 147 "reserved" 148 "reserved" 149 "reserved" 150 "reserved" 151 "reserved" 152 "reserved" 153 "reserved" 154 "reserved" 155 "reserved" 156 "reserved" 157 "reserved" 158 "reserved" 159 "reserved" 160 "reserved" 161 "reserved" 162 "reserved" 163 "reserved" 164 "reserved" 165 "reserved" 166 "reserved" 167 "reserved" 168 "reserved" 169 "reserved" 170 "reserved" 171 "reserved" 172 "reserved" 173 "reserved" 174 "reserved" 175 "reserved" 176 "reserved" 177 "reserved" 178 "reserved" 179 "reserved" 180 "reserved" 181 "reserved" 182 "reserved" 183 "reserved" 184 "reserved" 185 "reserved" 186 "reserved" 187 "reserved" 188 "reserved" 189 "reserved" 190 "reserved" 191 "reserved" 192 "reserved" 193 "reserved" 194 "reserved" 195 "reserved" 196 "reserved" 197 "reserved" 198 "reserved" 199 "reserved" 200 "reserved" 201 "reserved" 202 "reserved" 203 "reserved" 204 "reserved" 205 "reserved" 206 "reserved" 207 "reserved" 208 "reserved" 209 "reserved" 210 "reserved" 211 "reserved" 212 "reserved" 213 "reserved" 214 "reserved" 215 "reserved" 216 "reserved" 217 "reserved" 218 "reserved" 219 "reserved" 220 "reserved" 221 "reserved" 222 "reserved" 223 "reserved" 224 "reserved" 225 "reserved" 226 "reserved" 227 "reserved" 228 "reserved" 229 "reserved" 230 "reserved" 231 "reserved" 232 "reserved" 233 "reserved" 234 "reserved" 235 "reserved" 236 "reserved" 237 "reserved" 238 "reserved" 239 "reserved" 240 "reserved" 241 "reserved" 242 "reserved" 243 "reserved" 244 "reserved" 245 "reserved" 246 "reserved" 247 "reserved" 248 "reserved" 249 "reserved" 250 "reserved" 251 "reserved" 252 "reserved" 253 "reserved" 254 "reserved" 255 "reserved" ;
VAL_ 690 SGW_IMUWorkingSts 0 "No error" 1 "Error" ;
VAL_ 692 IVI_VrState 0 "Inactive" 1 "Active" ;
VAL_ 692 IVI_MirrorInterfaceMode 0 "Normal" 1 "Tilt" ;
VAL_ 693 IVI_LV_LimitPop 0 "No request" 1 "Cancel" 2 "Open" ;
VAL_ 693 IVI_KeepWarmRequest 0 "No request" 1 "OFF" 2 "ON" ;
VAL_ 693 IVI_LockACPlug 0 "No request" 1 "UnLock" 2 "Lock" ;
VAL_ 693 IVI_AppointChargeCmd 0 "No Request" 1 "Charge ON" 2 "Charge OFF" ;
VAL_ 693 IVI_ForwardVmaxlimitSw 0 "No Request" 1 "OFF" 2 "ON" 3 "Reserved" ;
VAL_ 694 IVI_GearRequest 0 "NO request" 1 "P" 2 "N" 3 "R" 4 "D" 5 "Invaild" ;
VAL_ 710 IVI_StWLengthPos 254 "No Request" 255 "OFF" ;
VAL_ 710 IVI_StWAnglePos 254 "No Request" 255 "OFF" ;
VAL_ 721 CBM_PhoneLocation 0 "Invalid" 1 "Welcome Invalid Zone" 2 "Welcome lighting area" 3 "Stay away from the locked area" 4 "Approaching the unlocking area" 5 "In Car" 6 "Left PE area" 7 "Right PE area" 8 "PE area of back door" ;
VAL_ 721 CBM_BlePairingSetSts 0 "Invalid" 1 "Enable" 2 "Disable" ;
VAL_ 850 SGW_BLERLLockCtrlReq 0 "No Request" 1 "Unlock" 2 "Lock" 3 "Reserved" ;
VAL_ 850 SGW_BLERRLockCtrlReq 0 "No Request" 1 "Unlock" 2 "Lock" 3 "Reserved" ;
VAL_ 850 SGW_BLELockCtrlReq 0 "No Request" 1 "Unlock" 2 "Lock" 3 "Reserved" ;
VAL_ 850 SGW_BLEChrgFlaplockCtrlReq 0 "No Request" 1 "Unlock" 2 "Lock" 3 "Reserved" ;
VAL_ 850 SGW_BLEFLLockCtrlReq 0 "No Request" 1 "Unlock" 2 "Lock" 3 "Reserved" ;
VAL_ 850 SGW_BLEFRLockCtrlReq 0 "No Request" 1 "Unlock" 2 "Lock" 3 "Reserved" ;
VAL_ 850 SGW_KeyLowBatWarning 0 "NO_WARNING" 1 "WARNING" ;
VAL_ 850 SGW_BLEPowerModeReq 0 "No Request" 1 "Request Power OFF" 2 "Request Power ON" 3 "Reserve" ;
VAL_ 850 SGW_BLESystemReadyReq 0 "No Request" 1 "Request Ready_Remote 0x2" 2 "Reserve" 3 "Reserve" ;
VAL_ 850 SGW_BLETailgateCtrlReq 0 "No Request" 1 "Unlock" 2 "Lock" 3 "Reserved" ;
VAL_ 857 SGW_PRNDSts 0 "Sleep" 1 "Wake up" ;
VAL_ 857 SGW_SwichesSts 0 "Sleep" 1 "Wake up" ;
VAL_ 857 SGW_HOD_HeatingSts 0 "Sleep" 1 "Wake up" ;
VAL_ 857 SGW_SWPSts 0 "Sleep" 1 "Wake up" ;
VAL_ 857 SGW_BCMSts 0 "Sleep" 1 "Wake up" ;
VAL_ 857 SGW_BMSSts 0 "Sleep" 1 "Wake up" ;
VAL_ 857 SGW_VCUSts 0 "Sleep" 1 "Wake up" ;
VAL_ 857 SGW_ADCUSts 0 "Sleep" 1 "Wake up" ;
VAL_ 857 SGW_IVISts 0 "Sleep" 1 "Wake up" ;
VAL_ 857 SGW_MFP_FCSts 0 "Sleep" 1 "Wake up" ;
VAL_ 857 SGW_MFP_RCSts 0 "Sleep" 1 "Wake up" ;
VAL_ 857 SGW_HLLSts 0 "Sleep" 1 "Wake up" ;
VAL_ 857 SGW_HLRSts 0 "Sleep" 1 "Wake up" ;
VAL_ 857 SGW_SCU_RSts 0 "Sleep" 1 "Wake up" ;
VAL_ 857 SGW_SCU_LSts 0 "Sleep" 1 "Wake up" ;
VAL_ 857 SGW_DCM_RRSts 0 "Sleep" 1 "Wake up" ;
VAL_ 857 SGW_DCM_RLSts 0 "Sleep" 1 "Wake up" ;
VAL_ 857 SGW_DCM_FRSts 0 "Sleep" 1 "Wake up" ;
VAL_ 857 SGW_DCM_FLSts 0 "Sleep" 1 "Wake up" ;
VAL_ 857 SGW_CBMSts 0 "Sleep" 1 "Wake up" ;
VAL_ 857 SGW_CGWSts 0 "Sleep" 1 "Wake up" ;
VAL_ 857 SGW_SGWSts 0 "Sleep" 1 "Wake up" ;
VAL_ 858 CGW_PRNDSts 0 "Sleep" 1 "Wake up" ;
VAL_ 858 CGW_SwichesSts 0 "Sleep" 1 "Wake up" ;
VAL_ 858 CGW_HOD_HeatingSts 0 "Sleep" 1 "Wake up" ;
VAL_ 858 CGW_SWPSts 0 "Sleep" 1 "Wake up" ;
VAL_ 858 CGW_BCMSts 0 "Sleep" 1 "Wake up" ;
VAL_ 858 CGW_BMSSts 0 "Sleep" 1 "Wake up" ;
VAL_ 858 CGW_VCUSts 0 "Sleep" 1 "Wake up" ;
VAL_ 858 CGW_ADCUSts 0 "Sleep" 1 "Wake up" ;
VAL_ 858 CGW_IVISts 0 "Sleep" 1 "Wake up" ;
VAL_ 858 CGW_MFP_FCSts 0 "Sleep" 1 "Wake up" ;
VAL_ 858 CGW_MFP_RCSts 0 "Sleep" 1 "Wake up" ;
VAL_ 858 CGW_HLLSts 0 "Sleep" 1 "Wake up" ;
VAL_ 858 CGW_HLRSts 0 "Sleep" 1 "Wake up" ;
VAL_ 858 CGW_SCU_RSts 0 "Sleep" 1 "Wake up" ;
VAL_ 858 CGW_SCU_LSts 0 "Sleep" 1 "Wake up" ;
VAL_ 858 CGW_DCM_RRSts 0 "Sleep" 1 "Wake up" ;
VAL_ 858 CGW_DCM_RLSts 0 "Sleep" 1 "Wake up" ;
VAL_ 858 CGW_DCM_FRSts 0 "Sleep" 1 "Wake up" ;
VAL_ 858 CGW_DCM_FLSts 0 "Sleep" 1 "Wake up" ;
VAL_ 858 CGW_CBMSts 0 "Sleep" 1 "Wake up" ;
VAL_ 858 CGW_CGWSts 0 "Sleep" 1 "Wake up" ;
VAL_ 858 CGW_SGWSts 0 "Sleep" 1 "Wake up" ;
VAL_ 880 DCM_SDS_FL_SensorWorksts 0 "Reset Default" 1 "Init" 2 "Active" 3 "Pre-Sleep" 4 "ThermalProtected" 5 "Invalid PORD Error" ;
VAL_ 881 DCM_SDS_FR_SensorWorksts 0 "Reset Default" 1 "Init" 2 "Active" 3 "Pre-Sleep" 4 "ThermalProtected" 5 "Invalid PORD Error" ;
VAL_ 882 DCM_SDS_RL_SensorWorksts 0 "Reset Default" 1 "Init" 2 "Active" 3 "Pre-Sleep" 4 "ThermalProtected" 5 "Invalid PORD Error" ;
VAL_ 883 DCM_SDS_RR_SensorWorksts 0 "Reset Default" 1 "Init" 2 "Active" 3 "Pre-Sleep" 4 "ThermalProtected" 5 "Invalid PORD Error" ;
VAL_ 898 CGW_VERSION1 0 "concept" 1 "Sample A" 2 "Sample B" 3 "Sample C" 4 "Sample D" 5 "Sample SW" ;
VAL_ 914 MCU_IGBTTempRiseMax 254 "Abnormal" 255 "Invalid" ;
VAL_ 914 MCU_IGBTTempRiseW 254 "Abnormal" 255 "Invalid" ;
VAL_ 914 MCU_IGBTTempRiseV 254 "Abnormal" 255 "Invalid" ;
VAL_ 914 MCU_IGBTTempRiseU 254 "Abnormal" 255 "Invalid" ;
VAL_ 914 MCU_IGBTTempMax 254 "Abnormal" 255 "Invalid" ;
VAL_ 914 MCU_IGBTTempW 254 "Abnormal" 255 "Invalid" ;
VAL_ 914 MCU_IGBTTempV 254 "Abnormal" 255 "Invalid" ;
VAL_ 914 MCU_IGBTTempU 254 "Abnormal" 255 "Invalid" ;
VAL_ 915 MCU_TempStatus 0 "Normal Temperature" 1 "Heating alarm 1" 2 "Heating alarm 2" 3 "Over Heating" ;
VAL_ 915 MCU_TempRiseCurrStr 254 "Abnormal" 255 "Invalid" ;
VAL_ 915 MCU_TempCurrStrMax 254 "Abnormal" 255 "Invalid" ;
VAL_ 915 MCU_TempCurrStr2 254 "Abnormal" 255 "Invalid" ;
VAL_ 915 MCU_TempCurrStr1 254 "Abnormal" 255 "Invalid" ;
VAL_ 915 MCU_TempCurrCool 254 "Abnormal" 255 "Invalid" ;
VAL_ 934 BMS_BatType 1 "lead-acid battery" 2 "Ni-MH battery" 3 "Lithium iron phosphate battery" 4 "Lithium manganate battery" 5 "Lithium cobalt oxide battery" 6 "Ternary material battery" 7 "Polymer lithium ion battery" 8 "Lithium titanate battery 0x9" 9 "Reserved" 10 "Reserved" 11 "Reserved" 12 "Reserved" 13 "Reserved" 14 "Reserved" 15 "Reserved" 16 "Reserved" 17 "Reserved" 18 "Reserved" 19 "Reserved" 20 "Reserved" 21 "Reserved" 22 "Reserved" 23 "Reserved" 24 "Reserved" 25 "Reserved" 26 "Reserved" 27 "Reserved" 28 "Reserved" 29 "Reserved" 30 "Reserved" 31 "Reserved" 32 "Reserved" 33 "Reserved" 34 "Reserved" 35 "Reserved" 36 "Reserved" 37 "Reserved" 38 "Reserved" 39 "Reserved" 40 "Reserved" 41 "Reserved" 42 "Reserved" 43 "Reserved" 44 "Reserved" 45 "Reserved" 46 "Reserved" 47 "Reserved" 48 "Reserved" 49 "Reserved" 50 "Reserved" 51 "Reserved" 52 "Reserved" 53 "Reserved" 54 "Reserved" 55 "Reserved" 56 "Reserved" 57 "Reserved" 58 "Reserved" 59 "Reserved" 60 "Reserved" 61 "Reserved" 62 "Reserved" 63 "Reserved" 64 "Reserved" 65 "Reserved" 66 "Reserved" 67 "Reserved" 68 "Reserved" 69 "Reserved" 70 "Reserved" 71 "Reserved" 72 "Reserved" 73 "Reserved" 74 "Reserved" 75 "Reserved" 76 "Reserved" 77 "Reserved" 78 "Reserved" 79 "Reserved" 80 "Reserved" 81 "Reserved" 82 "Reserved" 83 "Reserved" 84 "Reserved" 85 "Reserved" 86 "Reserved" 87 "Reserved" 88 "Reserved" 89 "Reserved" 90 "Reserved" 91 "Reserved" 92 "Reserved" 93 "Reserved" 94 "Reserved" 95 "Reserved" 96 "Reserved" 97 "Reserved" 98 "Reserved" 99 "Reserved" 100 "Reserved" 101 "Reserved" 102 "Reserved" 103 "Reserved" 104 "Reserved" 105 "Reserved" 106 "Reserved" 107 "Reserved" 108 "Reserved" 109 "Reserved" 110 "Reserved" 111 "Reserved" 112 "Reserved" 113 "Reserved" 114 "Reserved" 115 "Reserved" 116 "Reserved" 117 "Reserved" 118 "Reserved" 119 "Reserved" 120 "Reserved" 121 "Reserved" 122 "Reserved" 123 "Reserved" 124 "Reserved" 125 "Reserved" 126 "Reserved" 127 "Reserved" 128 "Reserved" 129 "Reserved" 130 "Reserved" 131 "Reserved" 132 "Reserved" 133 "Reserved" 134 "Reserved" 135 "Reserved" 136 "Reserved" 137 "Reserved" 138 "Reserved" 139 "Reserved" 140 "Reserved" 141 "Reserved" 142 "Reserved" 143 "Reserved" 144 "Reserved" 145 "Reserved" 146 "Reserved" 147 "Reserved" 148 "Reserved" 149 "Reserved" 150 "Reserved" 151 "Reserved" 152 "Reserved" 153 "Reserved" 154 "Reserved" 155 "Reserved" 156 "Reserved" 157 "Reserved" 158 "Reserved" 159 "Reserved" 160 "Reserved" 161 "Reserved" 162 "Reserved" 163 "Reserved" 164 "Reserved" 165 "Reserved" 166 "Reserved" 167 "Reserved" 168 "Reserved" 169 "Reserved" 170 "Reserved" 171 "Reserved" 172 "Reserved" 173 "Reserved" 174 "Reserved" 175 "Reserved" 176 "Reserved" 177 "Reserved" 178 "Reserved" 179 "Reserved" 180 "Reserved" 181 "Reserved" 182 "Reserved" 183 "Reserved" 184 "Reserved" 185 "Reserved" 186 "Reserved" 187 "Reserved" 188 "Reserved" 189 "Reserved" 190 "Reserved" 191 "Reserved" 192 "Reserved" 193 "Reserved" 194 "Reserved" 195 "Reserved" 196 "Reserved" 197 "Reserved" 198 "Reserved" 199 "Reserved" 200 "Reserved" 201 "Reserved" 202 "Reserved" 203 "Reserved" 204 "Reserved" 205 "Reserved" 206 "Reserved" 207 "Reserved" 208 "Reserved" 209 "Reserved" 210 "Reserved" 211 "Reserved" 212 "Reserved" 213 "Reserved" 214 "Reserved" 215 "Reserved" 216 "Reserved" 217 "Reserved" 218 "Reserved" 219 "Reserved" 220 "Reserved" 221 "Reserved" 222 "Reserved" 223 "Reserved" 224 "Reserved" 225 "Reserved" 226 "Reserved" 227 "Reserved" 228 "Reserved" 229 "Reserved" 230 "Reserved" 231 "Reserved" 232 "Reserved" 233 "Reserved" 234 "Reserved" 235 "Reserved" 236 "Reserved" 237 "Reserved" 238 "Reserved" 239 "Reserved" 240 "Reserved" 241 "Reserved" 242 "Reserved" 243 "Reserved" 244 "Reserved" 245 "Reserved" 246 "Reserved" 247 "Reserved" 248 "Reserved" 249 "Reserved" 250 "Reserved" 251 "Reserved" 252 "Reserved" 253 "Reserved" 254 "Reserved" 255 "Reserved" ;
VAL_ 945 SGW_OdometerInforValid 0 "Invalid" 1 "Valid" ;
VAL_ 946 SGW_VIN 0 "Invalid" 1 "Valid" ;
VAL_ 1282 CGW_PNC39 0 "Inactive" 1 "Active" ;
VAL_ 1282 CGW_PNC38 0 "Inactive" 1 "Active" ;
VAL_ 1282 CGW_PNC37 0 "Inactive" 1 "Active" ;
VAL_ 1282 CGW_PNC36 0 "Inactive" 1 "Active" ;
VAL_ 1282 CGW_PNC35 0 "Inactive" 1 "Active" ;
VAL_ 1282 CGW_PNC34 0 "Inactive" 1 "Active" ;
VAL_ 1282 CGW_PNC33 0 "Inactive" 1 "Active" ;
VAL_ 1282 CGW_PNC32 0 "Inactive" 1 "Active" ;
VAL_ 1282 CGW_PNC31 0 "Inactive" 1 "Active" ;
VAL_ 1282 CGW_PNC30 0 "Inactive" 1 "Active" ;
VAL_ 1282 CGW_PNC29 0 "Inactive" 1 "Active" ;
VAL_ 1282 CGW_PNC28 0 "Inactive" 1 "Active" ;
VAL_ 1282 CGW_PNC27 0 "Inactive" 1 "Active" ;
VAL_ 1282 CGW_PNC26 0 "Inactive" 1 "Active" ;
VAL_ 1282 CGW_PNC25 0 "Inactive" 1 "Active" ;
VAL_ 1282 CGW_PNC24 0 "Inactive" 1 "Active" ;
VAL_ 1282 CGW_PNC23 0 "Inactive" 1 "Active" ;
VAL_ 1282 CGW_PNC22 0 "Inactive" 1 "Active" ;
VAL_ 1282 CGW_PNC21 0 "Inactive" 1 "Active" ;
VAL_ 1282 CGW_PNC20 0 "Inactive" 1 "Active" ;
VAL_ 1282 CGW_PNC19 0 "Inactive" 1 "Active" ;
VAL_ 1282 CGW_PNC18 0 "Inactive" 1 "Active" ;
VAL_ 1282 CGW_PNC17 0 "Inactive" 1 "Active" ;
VAL_ 1282 CGW_PNC16 0 "Inactive" 1 "Active" ;
VAL_ 1282 CGW_PNC15 0 "Inactive" 1 "Active" ;
VAL_ 1282 CGW_PNC14 0 "Inactive" 1 "Active" ;
VAL_ 1282 CGW_PNC13 0 "Inactive" 1 "Active" ;
VAL_ 1282 CGW_PNC12 0 "Inactive" 1 "Active" ;
VAL_ 1282 CGW_PNC11 0 "Inactive" 1 "Active" ;
VAL_ 1282 CGW_PNC10 0 "Inactive" 1 "Active" ;
VAL_ 1282 CGW_PNC9 0 "Inactive" 1 "Active" ;
VAL_ 1282 CGW_PNC8 0 "Inactive" 1 "Active" ;
VAL_ 1282 CGW_PNC7 0 "Inactive" 1 "Active" ;
VAL_ 1282 CGW_PNC6 0 "Inactive" 1 "Active" ;
VAL_ 1282 CGW_PNC5 0 "Inactive" 1 "Active" ;
VAL_ 1282 CGW_PNC4 0 "Inactive" 1 "Active" ;
VAL_ 1282 CGW_PNC3 0 "Inactive" 1 "Active" ;
VAL_ 1282 CGW_PNC2 0 "Inactive" 1 "Active" ;
VAL_ 1282 CGW_PNC1 0 "Inactive" 1 "Active" ;
VAL_ 1282 CGW_PNC0 0 "Inactive" 1 "Active" ;
VAL_ 1282 CGW_PNI 0 "The NM message does not contain Partial network management request information" 1 "The NM message contains Partial network management request information" ;
VAL_ 1282 CGW_AWB 0 "Node has not woken up the network passive wakeup" 1 "Node has woken up the network active Wakeup" ;
VAL_ 1282 CGW_RMR 0 "Repeat Message State not requested" 1 "Repeat Message State requested" ;
VAL_ 1283 SGW_PNC39 0 "Inactive" 1 "Active" ;
VAL_ 1283 SGW_PNC38 0 "Inactive" 1 "Active" ;
VAL_ 1283 SGW_PNC37 0 "Inactive" 1 "Active" ;
VAL_ 1283 SGW_PNC36 0 "Inactive" 1 "Active" ;
VAL_ 1283 SGW_PNC35 0 "Inactive" 1 "Active" ;
VAL_ 1283 SGW_PNC34 0 "Inactive" 1 "Active" ;
VAL_ 1283 SGW_PNC33 0 "Inactive" 1 "Active" ;
VAL_ 1283 SGW_PNC32 0 "Inactive" 1 "Active" ;
VAL_ 1283 SGW_PNC31 0 "Inactive" 1 "Active" ;
VAL_ 1283 SGW_PNC30 0 "Inactive" 1 "Active" ;
VAL_ 1283 SGW_PNC29 0 "Inactive" 1 "Active" ;
VAL_ 1283 SGW_PNC28 0 "Inactive" 1 "Active" ;
VAL_ 1283 SGW_PNC27 0 "Inactive" 1 "Active" ;
VAL_ 1283 SGW_PNC26 0 "Inactive" 1 "Active" ;
VAL_ 1283 SGW_PNC25 0 "Inactive" 1 "Active" ;
VAL_ 1283 SGW_PNC24 0 "Inactive" 1 "Active" ;
VAL_ 1283 SGW_PNC23 0 "Inactive" 1 "Active" ;
VAL_ 1283 SGW_PNC22 0 "Inactive" 1 "Active" ;
VAL_ 1283 SGW_PNC21 0 "Inactive" 1 "Active" ;
VAL_ 1283 SGW_PNC20 0 "Inactive" 1 "Active" ;
VAL_ 1283 SGW_PNC19 0 "Inactive" 1 "Active" ;
VAL_ 1283 SGW_PNC18 0 "Inactive" 1 "Active" ;
VAL_ 1283 SGW_PNC17 0 "Inactive" 1 "Active" ;
VAL_ 1283 SGW_PNC16 0 "Inactive" 1 "Active" ;
VAL_ 1283 SGW_PNC15 0 "Inactive" 1 "Active" ;
VAL_ 1283 SGW_PNC14 0 "Inactive" 1 "Active" ;
VAL_ 1283 SGW_PNC13 0 "Inactive" 1 "Active" ;
VAL_ 1283 SGW_PNC12 0 "Inactive" 1 "Active" ;
VAL_ 1283 SGW_PNC11 0 "Inactive" 1 "Active" ;
VAL_ 1283 SGW_PNC10 0 "Inactive" 1 "Active" ;
VAL_ 1283 SGW_PNC9 0 "Inactive" 1 "Active" ;
VAL_ 1283 SGW_PNC8 0 "Inactive" 1 "Active" ;
VAL_ 1283 SGW_PNC7 0 "Inactive" 1 "Active" ;
VAL_ 1283 SGW_PNC6 0 "Inactive" 1 "Active" ;
VAL_ 1283 SGW_PNC5 0 "Inactive" 1 "Active" ;
VAL_ 1283 SGW_PNC4 0 "Inactive" 1 "Active" ;
VAL_ 1283 SGW_PNC3 0 "Inactive" 1 "Active" ;
VAL_ 1283 SGW_PNC2 0 "Inactive" 1 "Active" ;
VAL_ 1283 SGW_PNC1 0 "Inactive" 1 "Active" ;
VAL_ 1283 SGW_PNC0 0 "Inactive" 1 "Active" ;
VAL_ 1283 SGW_PNI 0 "The NM message does not contain Partial network management request information" 1 "The NM message contains Partial network management request information" ;
VAL_ 1283 SGW_AWB 0 "Node has not woken up the network passive wakeup" 1 "Node has woken up the network active Wakeup" ;
VAL_ 1283 SGW_RMR 0 "Repeat Message State not requested" 1 "Repeat Message State requested" ;

CM_ "Revision:V1.0,
Revision:V1.0.1,
Revision:V1.0.1,
Revision:V1.0.1,
Revision:V1.0.1,
Revision:V1.0.1,
Revision:V1.0.1,
Revision:V1.0.2,
Revision:V1.0.2,
Revision:V1.0.2,
Revision:V1.0.2,
Revision:V1.0.2,
Revision:V1.0.2,
Revision:V1.0.2,
Revision:V1.0.2,
Revision:V1.0.2,
Revision:V1.0.2,
Revision:V1.0.2,
Revision:V1.0.2,
Revision:V1.0.2,
Revision:V1.0.2,
Revision:V1.0.2,
Revision:V1.0.2,
Revision:V1.0.2,
Revision:V1.0.2,
Revision:V1.0.2,
Revision:V1.0.2,
Revision:V1.0.2,
Revision:V1.0.2,
Revision:V1.0.2,
Revision:V1.0.2,
Revision:V1.0.2,
Revision:V1.0.2,
Revision:V1.0.2,
Revision:V1.1,
Revision:V1.1,
Revision:V1.1,
Revision:V1.1,
Revision:V1.1,
Revision:V1.1,
Revision:V1.1,
Revision:V1.1,
Revision:V1.1,
Revision:V1.1,
Revision:V1.1,
Revision:V1.1,
Revision:V1.1,
Revision:V1.1,
Revision:V1.1,
Revision:V1.1,
Revision:V1.1,
Revision:V1.1,
Revision:V1.1,
Revision:V1.1,
Revision:V1.1,
Revision:V1.1,
Revision:V1.1,
Revision:V1.1,
Revision:V1.1,
Revision:V1.1,
Revision:V1.1,
Revision:V1.1,
Revision:V1.1,
Revision:V1.1,
Revision:V1.1,
Revision:V1.1,
Revision:V1.1,
Revision:V1.1,
Revision:V1.1,
Revision:V1.1,
Revision:V1.1,
Revision:V1.1,
Revision:V1.2,
Revision:V0.1.3,
Revision:V0.1.3,
Revision:V0.1.3,
Revision:V0.1.3,
Revision:V0.1.3,
Revision:V0.1.3,
Revision:V0.2.0,
Revision:V0.2.0,
Revision:V0.2.0,
Revision:V0.2.0,
Revision:V0.2.0,
Revision:V0.2.0,
Revision:V0.2.0,
Revision:V0.2.0,
Revision:V0.2.0,
Revision:V0.2.0,
Revision:V1.0.0,
Revision:V1.1.0,
Revision:V1.1.0,
Revision:V1.1.0,
Revision:V1.0.0,
Revision:V1.0.0,
Revision:V1.0.0,
Revision:V1.0.0,
Revision:V1.0.0,
Revision:V1.0.0,
Revision:V1.0.0,
Revision:V1.0.0,
Revision:V1.0.0,
Revision:V1.0.0,
Revision:V1.0.0,
Revision:V1.0.0,
Revision:V1.0.0,
Revision:V1.0.0,
Revision:V1.0.0,
Revision:V1.0.0,
Revision:V1.0.0,
Revision:V1.0.0,
Revision:V1.0.0,
Revision:V1.0.0,
Revision:V1.0.0,
Revision:V1.0.0,
Revision:V1.0.0,
Revision:V1.0.0,
Revision:V1.0.0,
Revision:V1.0.0,
Revision:V1.0.0,
Revision:V1.0.0,
Revision:V1.0.0,
Revision:V1.0.0,
Revision:V1.0.0,
Revision:V1.0.0,
Revision:V1.0.0,
Revision:V1.0.0,
Revision:V1.0.0,
Revision:V1.0.0,
Revision:V1.0.0,
Revision:V1.0.0,
Revision:V1.0.0,
Revision:V1.0.0,
Revision:V1.0.0,
Revision:V1.0.0,
Revision:V1.0.0,
Revision:V1.0.0,
Revision:V1.0.0,
Revision:V1.0.0,
Revision:V1.0.0,
Revision:V1.0.0,
Revision:V1.0.0,
Revision:V1.0.0,
Revision:V1.0.0,
Revision:V1.0.0,
Revision:V1.0.0,
Revision:V1.0.0,
Revision:V1.0.0,
Revision:V1.0.0,
Revision:V1.0.0,
Revision:V1.0.0,
Revision:V1.0.0,
Revision:V1.0.0,
Revision:V1.0.0,
Revision:V1.0.0,
Revision:V1.0.0,
Revision:V1.0.0,
Revision:V1.0.0,
Revision:V1.0.0,
Revision:V1.0.0,
Revision:V1.0.0,
Revision:V1.0.0,
Revision:V1.0.0,
Revision:V1.0.0,
Revision:V1.0.0,
Revision:V1.0.0,
Revision:V1.0.0,
Revision:V1.0.0,
Revision:V1.0.0,
Revision:V1.0.0,
Revision:V1.0.0,
Revision:V1.0.0,
Revision:V1.0.0,
Revision:V1.0.0,
Revision:V1.0.0,
Revision:V1.0.0,
Revision:V1.0.0,
Revision:V1.0.0,
Revision:V1.0.0,
Revision:V1.0.0,
Revision:V1.0.0,
Revision:V1.0.0,
Revision:V1.0.0,
Revision:V1.0.0,
Revision:V1.0.0,
Revision:V1.0.0,
Revision:V1.0.0,
Revision:V1.0.0,
Revision:V1.0.0,
Revision:V1.0.0,
Revision:V1.0.0,
Revision:V1.0.0,
Revision:V1.0.0,
Revision:V1.0.0,
Revision:V1.0.0,
Revision:V1.0.0,
Revision:V1.0.0,
Revision:V1.0.0,
Revision:V1.0.0,
Revision:V1.0.0,
Revision:V1.0.0,
Revision:V1.0.0,
Revision:V1.0.0,
Revision:V1.0.0,
Revision:V1.0.0,
Revision:V1.0.0,
Revision:V1.0.0,
Revision:V1.0.0,
Revision:V1.0.0,
Revision:V1.0.0,
Revision:V1.0.0,
Revision:V1.0.0,
Revision:V1.0.0,
Revision:V1.0.0,
Revision:V1.0.0,
Revision:V1.0.0,
Revision:V1.0.0,
Revision:V1.0.0,
Revision:V1.0.0,
Revision:V1.0.0,
Revision:V1.0.0,
Revision:V1.0.0,
Revision:V1.0.0,
Revision:V1.0.0,
Revision:V1.0.0,
Revision:V1.0.0,
Revision:V1.0.0,
Revision:V1.0.0,
Revision:V1.0.0,
Revision:V1.0.0,
Revision:V1.0.0,
Revision:V1.0.0,
Revision:V1.0.0,
Revision:V1.0.0,
Revision:V1.0.0,
Revision:V1.0.0,
Revision:V1.0.0,
Revision:V1.0.0,
Revision:V1.0.0,
Revision:V1.0.0,
Revision:V1.0.0,
Revision:V1.0.0,
Revision:V1.0.0,
Revision:V1.0.0,
Revision:V1.0.0,
Revision:V1.0.0,
Revision:V1.0.0,
Revision:V1.0.0,
Revision:V1.0.0,
Revision:V1.0.0,
Revision:V1.0.0,
Revision:V1.0.0,
Revision:V1.0.0,
Revision:V1.0.0,
Revision:V1.0.0,
Revision:V1.0.0,
Revision:V1.0.0,
Revision:V1.0.0,
Revision:V1.0.0,
Revision:V1.0.0,
Revision:V1.0.0,
Revision:V1.0.0,
Revision:V1.0.0,
Revision:V1.0.0,
Revision:V1.0.0,
Revision:V1.0.0,
Revision:V1.0.0,
Revision:V1.0.0,
Revision:V1.0.0,
Revision:V1.0.0,
Revision:V1.0.0,
Revision:V1.0.0,
Revision:V1.0.0,
Revision:V1.0.0,
Revision:V1.0.0,
Revision:V1.0.0,
Revision:V1.0.0,
Revision:V1.0.0,
Revision:V1.0.0,
Revision:V1.0.0,
Revision:V1.0.0,
Revision:V1.0.0,
Revision:V1.0.0,
Revision:V1.0.0,
Revision:V1.0.0,
Revision:V1.0.0,
Revision:V1.0.0,
Revision:V1.0.0,
Revision:V1.0.0,
Revision:V1.0.0,
Revision:V1.0.0,
Revision:V1.0.0,
Revision:V1.0.0,
Revision:V1.0.0,
Revision:V1.0.0,
Revision:V1.0.0,
Revision:V1.0.0,
Revision:V1.0.0,
Revision:V1.0.0,
Revision:V1.0.0,
Revision:V1.0.0,
Revision:V1.0.0,
Revision:V1.0.0,
Revision:V1.0.0,
Revision:V1.0.0,
Revision:V1.0.0,
Revision:V1.0.0,
Revision:V1.0.0,
Revision:V1.0.0,
Revision:V1.0.0,
Revision:V1.0.0,
Revision:V1.0.0,
Revision:V1.0.0,
Revision:V1.0.0,
Revision:V1.0.0,
Revision:V1.1.0,
Revision:V1.1.0,
Revision:V1.1.0,
Revision:V1.1.0,
Revision:V1.1.0,
Revision:V1.1.0,
Revision:V1.1.0,
Revision:V1.1.0,
Revision:V1.1.0,
Revision:V1.1.0,
Revision:V1.1.0,
Revision:V1.1.0,
Revision:V1.1.0,
Revision:V1.1.0,
Revision:V1.1.0,
Revision:V1.1.0,
Revision:V1.1.0,
Revision:V1.1.0,
Revision:V1.1.0,
Revision:V1.1.0,
Revision:V1.1.0,
Revision:V1.1.0,
Revision:V1.1.0,
Revision:V1.1.0,
Revision:V1.1.0,
Revision:V1.1.0,
Revision:V1.1.0,
Revision:V1.1.0,
Revision:V1.1.0,
Revision:V1.1.0,
Revision:V1.1.0,
Revision:V1.1.0,
Revision:V1.1.0,
Revision:V1.1.0,
Revision:V1.1.0,
Revision:V1.1.0,
Revision:V1.1.0,
Revision:V1.1.0,
Revision:V1.1.0,
Revision:V1.1.0,
Revision:V1.1.0,
Revision:V1.1.0,
Revision:V1.1.0,
Revision:V1.1.0,
Revision:V1.1.0,
Revision:V1.1.0,
Revision:V1.1.0,
Revision:V1.1.0,
Revision:V1.1.0,
Revision:V1.1.0,
Revision:V1.1.0,
Revision:V1.1.0,
Revision:V1.1.0,
Revision:V1.1.0,
Revision:V1.1.0,
Revision:V1.1.0,
Revision:V1.1.0,
Revision:V1.1.0,
Revision:V1.1.0,
Revision:V1.1.0,
Revision:V1.1.0,
Revision:V1.1.0,
Revision:V1.1.0,
Revision:V1.1.0,
Revision:V1.1.0,
Revision:V1.1.0,
Revision:V1.1.0,
Revision:V1.1.0,
Revision:V1.1.0,
Revision:V1.1.0,
Revision:V1.1.0,
Revision:V1.1.0,
Revision:V1.1.0,
Revision:V1.1.0,
Revision:V1.1.0,
Revision:V1.1.0,
Revision:V1.1.0,
Revision:V1.1.0,
Revision:V1.1.0,
Revision:V1.1.0,
Revision:V1.1.0,
Revision:V1.1.0,
Revision:V1.1.0,
Revision:V1.1.0,
Revision:V1.1.0,
Revision:V1.1.0,
Revision:V1.1.0,
Revision:V1.1.0,
Revision:V1.1.0,
Revision:V1.1.0,
Revision:V1.1.0,
Revision:V1.1.0,
Revision:V1.1.0,
Revision:V1.1.0,
Revision:V1.1.0,
Revision:V1.1.0,
Revision:V1.1.0,
Revision:V1.1.0,
Revision:V1.1.0,
Revision:V1.1.0,
Revision:V1.1.0,
Revision:V1.1.0,
Revision:V1.1.0,
Revision:V1.1.0,
Revision:V1.1.0,
Revision:V1.1.0,
Revision:V1.1.0,
Revision:V1.1.0,
Revision:V1.1.0,
Revision:V1.1.0,
Revision:V1.1.0,
Revision:V1.1.0,
Revision:V1.1.0,
Revision:V1.1.0,
Revision:V1.1.0,
Revision:V1.1.0,
Revision:V1.1.0,
Revision:V1.1.0,
Revision:V1.1.0,
Revision:V1.1.0,
Revision:V1.1.0,
Revision:V1.1.0,
Revision:V1.1.0,
Revision:V1.2.0,
Revision:V1.2.0,
Revision:V1.2.0,
Revision:V1.2.0,
Revision:V1.2.0,
Revision:V1.2.0,
Revision:V1.2.0,
Revision:V1.2.0,
Revision:V1.2.0,
Revision:V1.2.0,
Revision:V1.2.0,
Revision:V1.2.0,
Revision:V1.2.0,
Revision:V1.2.0,
Revision:V1.2.0,
Revision:V1.2.0,
Revision:V1.2.0,
Revision:V1.2.0,
Revision:V1.2.0,
Revision:V1.2.0,
Revision:V1.2.0,
Revision:V1.2.0,
Revision:V1.2.0,
Revision:V1.2.0,
Revision:V1.2.0,
Revision:V1.2.0,
Revision:V1.2.0,
Revision:V1.2.0,
Revision:V1.2.0,
Revision:V1.2.0,
Revision:V1.2.0,
Revision:V1.2.0,
Revision:V1.2.0,
Revision:V1.2.0,
Revision:V1.2.0,
Revision:V1.2.0,
Revision:V1.2.0,
Revision:V1.2.0,
Revision:V1.2.0,
Revision:V1.2.0,
Revision:V1.2.0,
Revision:V1.2.0,
Revision:V1.2.0,
Revision:V1.2.0,
Revision:V1.2.0,
Revision:V1.2.0,
Revision:V1.2.0,
Revision:V1.2.0,
Revision:V1.2.0,
Revision:V1.2.0,
Revision:V1.2.0,
Revision:V1.2.0,
Revision:V1.2.0,
Revision:V1.2.0,
Revision:V1.2.0,
Revision:V1.2.0,
Revision:V1.2.0,
Revision:V1.2.0,
Revision:V1.2.0,
Revision:V1.2.0,
Revision:V1.2.0,
Revision:V1.2.0,
Revision:V1.2.0,
Revision:V1.2.0,
Revision:V1.2.0,
Revision:V1.2.0,
Revision:V1.2.0,
Revision:V1.2.0,
Revision:V1.2.0,
Revision:V1.2.0,
Revision:V1.2.0,
Revision:V1.2.0,
Revision:V1.2.0,
Revision:V1.2.0,
Revision:V1.2.0,
Revision:V1.2.0,
Revision:V1.2.0,
Revision:V1.2.0,
Revision:V1.2.0,
Revision:V1.2.0,
Revision:V1.2.0,
Revision:V1.2.0,
Revision:V1.2.0,
Revision:V1.2.0,
Revision:V1.2.0,
Revision:V1.2.0,
Revision:V1.2.0,
Revision:V1.2.0,
Revision:V1.2.0,
Revision:V1.2.0,
Revision:V1.2.0,
Revision:V1.2.0,
Revision:V1.2.0,
Revision:V1.2.0,
Revision:V1.2.0,
Revision:V1.2.0,
Revision:V1.2.0,
Revision:V1.2.0,
Revision:V1.2.0,
Revision:V1.2.0,
Revision:V1.2.0,
Revision:V1.2.0,
Revision:V1.2.0,
Revision:V1.2.0,
Revision:V1.2.0,
Revision:V1.2.0,
Revision:V1.2.0,
Revision:V1.2.0,
Revision:V1.2.0,
Revision:V1.2.0,
Revision:V1.2.0,
Revision:V1.2.0,
Revision:V1.2.0,
Revision:V1.2.0,
Revision:V1.2.0,
Revision:V1.2.0,
Revision:V1.2.0,
Revision:V1.2.0,
Revision:V1.2.0,
Revision:V1.2.0,
Revision:V1.2.0,
Revision:V1.2.0,
Revision:V1.2.0,
Revision:V1.2.0,
Revision:V1.2.0,
Revision:V1.2.0,
Revision:V1.2.0,
Revision:V1.2.0,
Revision:V1.2.0,
Revision:V1.2.0,
Revision:V1.2.0,
Revision:V1.2.0,
Revision:V1.2.0,
Revision:V1.2.0,
Revision:V1.2.0,
Revision:V1.2.0,
Revision:V1.2.0,
Revision:V1.2.0,
Revision:V1.2.0,
Revision:V1.2.0,
Revision:V1.2.0,
Revision:V1.2.0,
Revision:V1.2.0,
Revision:V1.2.0,
Revision:V1.2.0,
Revision:V1.2.0,
Revision:V1.2.0,
Revision:V1.2.0,
Revision:V1.2.0,
Revision:V1.2.0,
Revision:V1.2.0,
Revision:V1.2.0,
Revision:V1.2.0,
Revision:V1.2.0,
Revision:V1.2.0,
Revision:V1.2.0,
Revision:V1.2.0,
Revision:V1.2.0,
Revision:V1.2.0,
Revision:V1.2.0,
Revision:V1.2.0,
Revision:V1.2.0,
Revision:V1.2.0,
Revision:V1.2.0,
Revision:V1.2.0,
Revision:V1.2.0,
Revision:V1.2.0,
Revision:V1.2.0,
Revision:V1.2.0,
Revision:V1.2.0,
Revision:V1.2.0,
Revision:V1.2.0,
Revision:V1.2.0,
Revision:V1.2.0,
Revision:V1.2.0,
Revision:V1.2.0,
Revision:V1.2.0,
Revision:V1.2.0,
Revision:V1.2.0,
Revision:V1.2.0,
Revision:V1.2.0,
Revision:V1.2.0,
Revision:V1.2.0,
Revision:V1.2.0,
Revision:V1.2.0,
Revision:V1.2.0,
Revision:V1.2.0,
Revision:V1.2.0,
Revision:V1.2.0,
Revision:V1.2.0,
Revision:V1.2.0,
Revision:V1.2.0,
Revision:V1.2.0,
Revision:V1.2.0,
Revision:V1.2.0,
Revision:V1.2.0,
Revision:V1.2.0,
Revision:V1.2.0,
Revision:V1.2.0,
Revision:V1.2.0,
Revision:V1.2.0,
Revision:V1.2.0,
Revision:V1.2.0,
Revision:V1.2.0,
Revision:V1.2.0,
Revision:V1.2.0,
Revision:V1.2.0,
Revision:V1.2.0,
Revision:V1.2.0,
Revision:V1.2.0,
Revision:V1.2.0,
Revision:V1.2.0,
Revision:V1.2.0,
Revision:V1.2.0,
Revision:V1.2.0,
Revision:V1.2.0,
Revision:V1.2.0,
Revision:V1.2.0,
Revision:V1.2.0,
Revision:V1.2.0,
Revision:V1.2.0,
Revision:V1.2.0,
Revision:V1.2.0,
Revision:V1.2.0,
Revision:V1.2.0,
Revision:V1.2.0,
Revision:V1.2.0,
Revision:V1.2.0,
Revision:V1.2.0,
Revision:V1.2.0,
Revision:V1.2.0,
Revision:V1.2.0,
Revision:V1.2.0,
Revision:V1.2.0,
Revision:V1.2.0,
Revision:V1.2.0,
Revision:V1.2.0,
Revision:V1.2.0,
Revision:V1.2.0,
Revision:V1.2.0,
Revision:V1.2.0,
Revision:V1.2.0,
Revision:V1.2.0,
Revision:V1.2.0,
Revision:V1.2.0,
Revision:V1.2.0,
Revision:V1.2.0,
Revision:V1.2.0,
Revision:V1.2.0,
Revision:V1.2.0,
Revision:V1.2.0,
Revision:V1.2.0,
Revision:V1.2.0,
Revision:V1.2.0,
Revision:V1.2.0,
Revision:V1.2.0,
Revision:V1.2.0,
Revision:V1.2.0,
Revision:V1.2.0,
Revision:V1.2.0,
Revision:V1.2.0,
Revision:V1.2.0,
Revision:V1.2.0,
Revision:V1.2.0,
Revision:V1.2.0,
Revision:V1.2.0,
Revision:V1.2.0,
Revision:V1.2.0,
Revision:V1.2.0,
Revision:V1.2.0,
Revision:V1.2.0,
Revision:V1.2.0,
Revision:V1.3.0,
Revision:V1.3.0,
Revision:V1.3.0,
Revision:V1.3.0,
Revision:V1.3.0,
Revision:V1.3.0,
Revision:V1.3.0,
Revision:V1.3.0,
Revision:V1.3.0,
Revision:V1.3.0,
Revision:V1.3.0,
Revision:V1.3.0,
Revision:V1.3.0,
Revision:V1.3.0,
Revision:V1.3.0,
Revision:V1.3.0,
Revision:V1.3.0,
Revision:V1.3.0,
Revision:V1.3.0,
Revision:V1.3.0,
Revision:V1.3.0,
Revision:V1.3.0,
Revision:V1.3.0,
Revision:V1.3.0,
Revision:V1.3.0,
Revision:V1.3.0,
Revision:V1.3.0,
Revision:V1.3.0,
Revision:V1.3.0,
Revision:V1.3.0,
Revision:V1.3.0,
Revision:V1.3.0,
Revision:V1.3.0,
Revision:V1.3.0,
Revision:V1.3.0,
Revision:V1.3.0,
Revision:V1.3.0,
Revision:V1.3.0,
Revision:V1.3.0,
Revision:V1.3.0,
Revision:V1.3.0,
Revision:V1.3.0,
Revision:V1.3.0,
Revision:V1.3.0,
Revision:V1.3.0,
Revision:V1.3.0,
Revision:V1.3.0,
Revision:V1.3.0,
Revision:V1.3.0,
Revision:V1.3.0,
Revision:V1.3.0,
Revision:V1.3.0,
Revision:V1.3.0,
Revision:V1.3.0,
Revision:V1.3.0,
Revision:V1.3.0,
Revision:V1.3.0,
Revision:V1.3.0,
Revision:V1.3.0,
Revision:V1.3.0,
Revision:V1.3.0,
Revision:V1.3.0,
Revision:V1.3.0,
Revision:V1.3.0,
Revision:V1.3.0,
Revision:V1.3.0,
Revision:V1.3.0,
Revision:V1.3.0,
Revision:V1.3.0,
Revision:V1.3.0,
Revision:V1.3.0,
Revision:V1.3.0,
Revision:V1.3.0,
Revision:V1.3.0,
Revision:V1.3.0,
Revision:V1.3.0,
Revision:V1.3.0,
Revision:V1.3.0,
Revision:V1.3.0,
Revision:V1.3.0,
Revision:V1.3.0,
Revision:V1.3.0,
Revision:V1.3.0,
Revision:V1.3.0,
Revision:V1.3.0,
Revision:V1.3.0,
Revision:V1.3.0,
Revision:V1.3.0,
Revision:V1.3.0,
Revision:V1.3.0,
Revision:V1.3.0,
Revision:V1.3.0,
Revision:V1.3.0,
Revision:V1.3.0,
Revision:V1.3.0,
Revision:V1.3.0,
Revision:V1.3.0,
Revision:V1.3.0,
Revision:V1.3.0,
Revision:V1.3.0,
Revision:V1.3.0,
Revision:V1.3.0,
Revision:V1.3.0,
Revision:V1.3.0,
Revision:V1.3.0,
Revision:V1.3.0,
Revision:V1.3.0,
Revision:V1.3.0,
Revision:V1.3.0,
Revision:V1.3.0,
Revision:V1.3.0,
Revision:V1.3.0,
Revision:V1.3.0,
Revision:V1.3.0,
Revision:V1.3.0,
Revision:V1.3.0,
Revision:V1.3.0,
Revision:V1.3.0,
Revision:V1.3.0,
Revision:V1.3.0,
Revision:V1.3.0,
Revision:V1.3.0,
Revision:V1.3.0,
Revision:V1.3.0,
Revision:V1.3.0,
Revision:V1.3.0,
Revision:V1.3.0,
Revision:V1.3.0,
Revision:V1.3.0,
Revision:V1.3.0,
Revision:V1.3.0,
Revision:V1.3.0,
Revision:V1.3.0,
Revision:V1.3.0,
Revision:V1.3.0,
Revision:V1.3.0,
Revision:V1.3.0,
Revision:V1.3.0,
Revision:V1.3.0,
Revision:V1.3.0,
Revision:V1.3.0,
Revision:V1.3.0,
Revision:V1.3.0,
Revision:V1.3.0,
Revision:V1.3.0,
Revision:V1.3.0,
Revision:V1.3.0,
Revision:V1.3.0,
Revision:V1.3.0,
Revision:V1.3.0,
Revision:V1.3.0,
Revision:V1.3.0,
Revision:V1.3.0,
Revision:V1.3.0,
Revision:V1.3.0,
Revision:V1.3.0,
Revision:V1.3.0,
Revision:V1.3.0,
Revision:V1.3.0,
Revision:V1.3.0,
Revision:V1.3.0,
Revision:V1.3.0,
Revision:V1.3.0,
Revision:V1.3.0,
Revision:V1.3.0,
Revision:V1.3.0,
Revision:V1.3.0,
Revision:V1.3.0,
Revision:V1.3.0,
Revision:V1.3.0,
Revision:V1.3.0,
Revision:V1.3.0,
Revision:V1.3.0,
Revision:V1.3.0,
Revision:V1.3.0,
Revision:V1.3.0,
Revision:V1.3.0,
Revision:V1.3.0,
Revision:V1.3.0,
Revision:V1.3.0,
Revision:V1.3.0,
Revision:V1.3.0,
Revision:V1.3.0,
Revision:V1.3.0,
Revision:V1.3.0,
Revision:V1.3.0,
Revision:V1.3.0,
Revision:V1.3.0,
Revision:V1.3.0,
Revision:V1.3.0,
Revision:V1.3.0,
Revision:V1.3.0,
Revision:V1.3.0,
Revision:V1.3.0,
Revision:V1.3.0,
Revision:V1.3.0,
Revision:V1.3.0,
Revision:V1.3.0,
Revision:V1.3.0,
Revision:V1.3.0,
Revision:V1.3.0,
Revision:V1.3.0,
Revision:V1.3.0,
Revision:V1.3.0,
Revision:V1.3.0,
Revision:V1.3.0,
Revision:V1.3.0,
Revision:V1.3.0,
Revision:V1.3.0,
Revision:V1.3.0,
Revision:V1.3.0,
Revision:V1.3.0,
Revision:V1.3.0,
Revision:V1.3.0,
Revision:V1.3.0,
Revision:V1.3.0,
Revision:V1.3.0,
Revision:V1.3.0,
Revision:V1.3.0,
Revision:V1.3.0,
Revision:V1.3.0,
Revision:V1.3.0,
Revision:V1.3.0,
Revision:V1.3.0,
Revision:V1.3.0,
Revision:V1.3.0,
Revision:V1.3.0,
Revision:V1.3.0,
Revision:V1.3.0,
Revision:V1.3.0,
Revision:V1.3.0,
Revision:V1.3.0,
Revision:V1.3.0,
Revision:V1.3.0,
Revision:V1.3.0,
Revision:V1.3.0,
Revision:V1.3.0,
Revision:V1.3.0,
Revision:V1.3.0,
Revision:V1.3.0,
Revision:V1.3.0,
Revision:V1.3.0,
Revision:V1.3.0,
Revision:V1.3.0,
Revision:V1.3.0,
Revision:V1.3.0,
Revision:V1.3.0,
Revision:V1.3.0,
Revision:V1.3.0,
Revision:V1.3.0,
Revision:V1.3.0,
Revision:V1.3.0,
Revision:V1.3.0,
Revision:V1.3.0,
Revision:V1.3.0,
Revision:V1.3.0,
Revision:V1.3.0,
Revision:V1.3.0,
Revision:V1.3.0,
Revision:V1.3.0,
Revision:V1.3.0,
Revision:V1.3.0,
Revision:V1.3.0,
Revision:V1.3.0,
Revision:V1.3.0,
Revision:V1.3.0,
Revision:V1.3.0,
Revision:V1.3.0,
Revision:V1.3.0,
Revision:V1.3.0,
Revision:V1.3.0,
Revision:V1.3.0,
Revision:V1.3.0,
Revision:V1.3.0,
Revision:V1.3.0,
Revision:V1.3.0,
Revision:V1.3.0,
Revision:V1.3.0,
Revision:V1.3.0,
Revision:V1.3.0,
Revision:V1.3.0,
Revision:V1.3.0,
Revision:V1.3.0,
Revision:V1.3.0,
Revision:V1.3.0,
Revision:V1.3.0,
Revision:V1.3.0,
Revision:V1.3.0,
Revision:V1.3.0,
Revision:V1.3.0,
Revision:V1.3.0,
Revision:V1.3.0,
Revision:V1.3.0,
Revision:V1.3.0,
Revision:V1.3.0,
Revision:V1.3.0,
Revision:V1.3.0,
Revision:V1.3.0,
Revision:V1.3.0,
Revision:V1.3.0,
Revision:V1.3.0,
Revision:V1.3.0,
Revision:V1.3.0,
Revision:V1.3.0,
Revision:V1.3.0,
Revision:V1.3.0,
Revision:V1.3.0,
Revision:V1.3.0,
Revision:V1.3.0,
Revision:V1.3.0,
Revision:V1.3.0,
Revision:V1.3.0,
Revision:V1.3.0,
Revision:V1.3.0,
Revision:V1.3.0,
Revision:V1.3.0,
Revision:V1.3.0,
Revision:V1.3.0,
Revision:V1.3.0,
Revision:V1.3.0,
Revision:V1.3.0,
Revision:V1.3.0,
Revision:V1.3.0,
Revision:V1.3.0,
Revision:V1.3.0,
Revision:V1.3.0,
Revision:V1.3.0,
Revision:V1.3.0,
Revision:V1.3.0,
Revision:V1.3.0,
Revision:V1.3.0,
Revision:V1.3.0,
Revision:V1.3.0,
Revision:V1.3.0,
Revision:V1.3.0,
Revision:V1.3.0,
Revision:V1.3.0,
Revision:V1.3.0,
Revision:V1.3.0,
Revision:V1.3.0,
Revision:V1.3.0,
Revision:V1.3.0,
Revision:V1.3.0,
Revision:V1.3.0,
Revision:V1.3.0,
Revision:V1.3.0,
Revision:V1.3.0,
Revision:V1.3.0,
Revision:V1.3.0,
Revision:V1.3.0,
Revision:V1.3.0,
Revision:V1.3.0,
Revision:V1.3.0,
Revision:V1.3.0,
Revision:V1.3.0,
Revision:V1.3.0,
Revision:V1.3.0,
Revision:V1.3.0,
Revision:V1.3.0,
Revision:V1.3.0,
Revision:V1.3.0,
Revision:V1.3.0,
Revision:V1.3.0,
Revision:V1.3.0,
Revision:V1.3.0,
Revision:V1.3.0,
Revision:V1.3.0,
Revision:V1.3.0,
Revision:V1.3.0,
Revision:V1.3.0,
Revision:V1.3.0,
Revision:V1.3.0,
Revision:V1.3.0,
Revision:V1.3.0,
Revision:V1.3.0,
Revision:V1.3.0,
Revision:V1.3.0,
Revision:V1.3.0,
Revision:V1.3.0,
Revision:V1.3.0,
Revision:V1.3.0,
Revision:V1.3.0,
Revision:V1.3.0,
Revision:V1.3.0,
Revision:V1.3.0,
Revision:V1.3.0,
Revision:V1.3.0,
Revision:V1.3.0,
Revision:V1.3.0,
Revision:V1.3.0,
Revision:V1.3.0,
Revision:V1.3.0,
Revision:V1.3.0,
Revision:V1.3.0,
Revision:V1.3.0,
Revision:V1.3.0,
Revision:V1.3.0,
Revision:V1.3.0,
Revision:V1.3.0,
Revision:V1.3.0,
Revision:V1.3.0,
Revision:V1.3.0,
Revision:V1.3.0,
Revision:V1.3.0,
Revision:V1.3.0,
Revision:V1.3.0,
Revision:V1.3.0,
Revision:V1.3.0,
Revision:V1.3.0,
Revision:V1.3.0,
Revision:V1.3.0,
Revision:V1.3.0,
Revision:V1.3.0,
Revision:V1.3.0,
Revision:V1.3.0,
Revision:V1.3.0,
Revision:V1.3.0,
Revision:V1.3.0,
Revision:V1.3.0,
Revision:V1.3.0,
Revision:V1.3.0,
Revision:V1.3.0,
Revision:V1.3.0,
Revision:V1.3.0,
Revision:V1.3.0,
Revision:V1.3.0,
Revision:V1.3.0,
Revision:V1.3.0,
Revision:V1.3.0,
Revision:V1.3.0,
Revision:V1.3.0,
Revision:V1.3.0,
Revision:V1.3.0,
Revision:V1.3.0,
Revision:V1.3.0,
Revision:V1.3.0,
Revision:V1.3.0,
Revision:V1.3.0,
Revision:V1.3.0,
Revision:V1.3.0,
Revision:V1.3.0,
Revision:V1.3.0,
Revision:V1.3.0,
Revision:V1.3.0,
Revision:V1.3.0,
Revision:V1.3.0,
Revision:V1.3.0,
Revision:V1.3.0,
Revision:V1.3.0,
Revision:V1.3.0,
Revision:V1.3.0,
Revision:V1.3.0,
Revision:V1.3.0,
Revision:V1.3.0,
Revision:V1.3.0,
Revision:V1.3.0,
Revision:V1.3.0,
Revision:V1.3.0,
Revision:V1.3.0,
Revision:V1.3.0,
Revision:V1.3.0,
Revision:V1.3.0,
Revision:V1.3.0,
Revision:V1.3.0,
Revision:V1.3.0,
Revision:V1.3.0,
Revision:V1.3.0,
Revision:V1.3.0,
Revision:V1.3.0,
Revision:V1.3.0,
Revision:V1.3.0,
Revision:V1.3.0,
Revision:V1.3.0,
Revision:V1.3.0,
Revision:V1.3.0,
Revision:V1.3.0,
Revision:V1.3.0,
Revision:V1.3.0,
Revision:V1.3.0,
Revision:V1.3.0,
Revision:V1.3.0,
Revision:V1.3.0,
Revision:V1.3.0,
Revision:V1.3.0,
Revision:V1.3.0,
Revision:V1.3.0,
Revision:V1.3.0,
Revision:V1.3.0,
Revision:V1.3.0,
Revision:V1.3.0,
Revision:V1.3.0,
Revision:V1.3.0,
Revision:V1.3.0,
Revision:V1.3.0,
Revision:V1.3.0,
Revision:V1.3.0,
Revision:V1.3.0,
Revision:V1.3.0,
Revision:V1.3.0,
Revision:V1.3.0,
Revision:V1.3.0,
Revision:V1.3.0,
Revision:V1.3.0,
Revision:V1.3.0,
Revision:V1.3.0,
Revision:V1.3.0,
Revision:V1.3.0,
Revision:V1.3.0,
Revision:V1.3.0,
Revision:V1.3.0,
Revision:V1.3.0,
Revision:V1.3.0,
Revision:V1.3.0,
Revision:V1.3.0,
Revision:V1.3.0,
Revision:V1.3.0,
Revision:V1.3.0,
Revision:V1.3.0,
Revision:V1.3.0,
Revision:V1.3.0,
Revision:V1.3.0,
Revision:V1.3.0,
Revision:V1.3.0,
Revision:V1.3.0,
Revision:V1.3.0,
Revision:V1.3.0,
Revision:V1.3.0,
Revision:V1.3.0,
Revision:V1.3.0,
Revision:V1.3.0,
Revision:V1.3.0,
Revision:V1.3.0,
Revision:V1.3.0,
Revision:V1.3.0,
Revision:V1.3.0,
Revision:V1.3.0,
Revision:V1.3.0,
Revision:V1.3.0,
Revision:V1.3.0,
Revision:V1.3.0,
Revision:V1.3.0,
Revision:V1.3.0,
Revision:V1.3.0,
Revision:V1.3.0,
Revision:V1.3.0,
Revision:V1.3.0,
Revision:V1.3.0,
Revision:V1.3.0,
Revision:V1.3.0,
Revision:V1.3.0,
Revision:V1.3.0,
Revision:V1.3.0,
Revision:V1.3.0,
Revision:V1.3.0,
Revision:V1.3.0,
Revision:V1.3.0,
Revision:V1.3.0,
Revision:V1.3.0,
Revision:V1.3.0,
Revision:V1.3.0,
Revision:V1.3.0,
Revision:V1.3.0,
Revision:V1.3.0,
Revision:V1.3.0,
Revision:V1.3.0,
Revision:V1.3.0,
Revision:V1.3.0,
Revision:V1.3.0,
Revision:V1.3.0,
Revision:V1.3.0,
Revision:V1.3.0,
Revision:V1.3.0,
Revision:V1.3.0,
Revision:V1.3.0,
Revision:V1.3.0,
Revision:V1.3.0,
Revision:V1.3.0,
Revision:V1.3.0,
Revision:V1.3.0,
Revision:V1.3.0,
Revision:V1.3.0,
Revision:V1.3.0,
Revision:V1.3.0,
Revision:V1.3.0,
Revision:V1.3.0,
Revision:V1.3.0,
Revision:V1.3.0,
Revision:V1.3.0,
Revision:V1.3.0,
Revision:V1.3.0,
Revision:V1.3.0,
Revision:V1.3.0,
Revision:V1.3.0,
Revision:V1.3.0,
Revision:V1.3.0,
Revision:V1.3.0,
Revision:V1.3.0,
Revision:V1.3.0,
Revision:V1.3.0,
Revision:V1.3.0,
Revision:V1.3.0,
Revision:V1.3.0,
Revision:V1.3.0,
Revision:V1.3.0,
Revision:V1.3.0,
Revision:V1.3.0,
Revision:V1.3.0,
Revision:V1.3.0,
Revision:V1.3.0,
Revision:V1.3.0,
Revision:V1.3.0,
Revision:V1.3.0,
Revision:V1.3.0,
Revision:V1.3.0,
Revision:V1.3.0,
Revision:V1.3.0,
Revision:V1.3.0,
Revision:V1.3.0,
Revision:V1.3.0,
Revision:V1.3.0,
Revision:V1.3.0,
Revision:V1.3.0,
Revision:V1.3.0,
Revision:V1.3.0,
Revision:V1.3.0,
Revision:V1.3.0,
Revision:V1.3.0,
Revision:V1.3.0,
Revision:V1.3.0,
Revision:V1.3.0,
Revision:V1.3.0,
Revision:V1.3.0,
Revision:V1.3.0,
Revision:V1.3.0,
Revision:V1.3.0,
Revision:V1.3.0,
Revision:V1.3.0,
Revision:V1.3.0,
Revision:V1.3.0,
Revision:V1.3.0,
Revision:V1.3.0,
Revision:V1.3.0,
Revision:V1.3.0,
Revision:V1.3.0,
Revision:V1.3.0,
Revision:V1.3.0,
Revision:V1.3.0,
Revision:V1.3.0,
Revision:V1.3.0,
Revision:V1.3.0,
Revision:V1.3.0,
Revision:V1.3.0,
Revision:V1.3.0,
Revision:V1.3.0,
Revision:V1.3.0,
Revision:V1.3.0,
Revision:V1.3.0,
Revision:V1.3.0,
Revision:V1.3.0,
Revision:V1.3.0,
Revision:V1.3.0,
Revision:V1.3.0,
Revision:V1.3.0,
Revision:V1.3.0,
Revision:V1.3.0,
Revision:V1.3.0,
Revision:V1.3.0,
Revision:V1.3.0,
Revision:V1.3.0,
Revision:V1.3.0,
Revision:V1.3.0,
Revision:V1.3.0,
Revision:V1.3.0,
Revision:V1.3.0,
Revision:V1.3.0,
Revision:V1.3.0,
Revision:V1.3.0,
Revision:V1.3.0,
Revision:V1.3.0,
Revision:V1.3.0,
Revision:V1.3.0,
Revision:V1.3.0,
Revision:V1.3.0,
Revision:V1.3.0,
Revision:V1.3.0,
Revision:V1.3.0,
Revision:V1.3.0,
Revision:V1.3.0,
Revision:V1.3.0,
Revision:V1.3.0,
Revision:V1.3.0,
Revision:V1.3.0,
Revision:V1.3.0,
Revision:V1.3.0,
Revision:V1.3.0,
Revision:V1.3.0,
Revision:V1.3.0,
Revision:V1.3.0,
Revision:V1.3.0,
Revision:V1.3.0,
Revision:V1.3.0,
Revision:V1.3.0,
Revision:V1.3.0,
Revision:V1.3.0,
Revision:V1.3.0,
Revision:V1.3.0,
Revision:V1.3.0,
Revision:V1.3.0,
Revision:V1.3.0,
Revision:V1.3.0,
Revision:V1.3.0,
Revision:V1.3.0,
Revision:V1.3.0,
Revision:V1.3.0,
Revision:V1.3.0,
Revision:V1.3.0,
Revision:V1.3.0,
Revision:V1.3.0,
Revision:V1.3.0,
Revision:V1.3.0,
Revision:V1.3.0,
Revision:V1.3.0,
Revision:V1.3.0,
Revision:V1.3.0,
Revision:V1.3.0,
Revision:V1.3.0,
Revision:V1.3.0,
Revision:V1.3.0,
Revision:V1.3.0,
Revision:V1.3.0,
Revision:V1.3.0,
Revision:V1.3.0,
Revision:V1.3.0,
Revision:V1.3.0,
Revision:V1.3.0,
Revision:V1.3.0,
Revision:V1.3.0,
Revision:V1.3.0,
Revision:V1.3.0,
Revision:V1.3.0,
Revision:V1.3.0,
Revision:V1.3.0,
Revision:V1.3.0,
Revision:V1.3.0,
Revision:V1.3.0,
Revision:V1.3.0,
Revision:V1.3.0,
Revision:V1.3.0,
Revision:V1.3.0,
Revision:V1.3.0,
Revision:V1.3.0,
Revision:V1.3.0,
Revision:V1.3.0,
Revision:V1.3.0,
Revision:V1.3.0,
Revision:V1.3.0,
Revision:V1.3.0,
Revision:V1.3.0,
Revision:V1.3.0,
Revision:V1.3.0,
Revision:V1.3.0,
Revision:V1.3.0,
Revision:V1.3.0,
Revision:V1.3.0,
Revision:V1.3.0,
Revision:V1.3.0,
Revision:V1.3.0,
Revision:V1.3.0,
Revision:V1.3.0,
Revision:V1.3.0,
Revision:V1.3.0,
Revision:V1.3.0,
Revision:V1.3.0,
Revision:V1.3.0,
Revision:V1.3.0,
Revision:V1.3.0,
Revision:V1.3.0,
Revision:V1.3.0,
Revision:V1.3.0,
Revision:V1.3.0,
Revision:V1.3.0,
Revision:V1.3.0,
Revision:V1.3.0,
Revision:V1.3.0,
Revision:V1.3.0,
Revision:V1.3.0,
Revision:V1.3.0,
Revision:V1.3.0,
Revision:V1.3.0,
Revision:V1.3.0,
Revision:V1.3.0,
Revision:V1.3.0,
Revision:V1.3.0,
Revision:V1.3.0,
Revision:V1.3.0,
Revision:V1.3.0,
Revision:V1.3.0,
Revision:V1.3.0,
Revision:V1.3.0,
Revision:V1.3.0,
Revision:V1.3.0,
Revision:V1.3.0,
Revision:V1.3.0,
Revision:V1.3.0,
Revision:V1.3.0,
Revision:V1.3.0,
Revision:V1.3.0,
Revision:V1.3.0,
Revision:V1.3.0,
Revision:V1.3.0,
Revision:V1.4.0,
Revision:V1.4.0,
Revision:V1.4.0,
Revision:V1.4.0,
Revision:V1.4.0,
Revision:V1.4.0,
Revision:V1.4.0,
Revision:V1.4.0,
Revision:V1.4.0,
Revision:V1.4.0,
Revision:V1.4.0,
Revision:V1.4.0,
Revision:V1.4.0,
Revision:V1.4.0,
Revision:V1.4.0,
Revision:V1.4.0,
Revision:V1.4.0,
Revision:V1.4.0,
Revision:V1.4.0,
Revision:V1.4.0,
Revision:V1.4.0,
Revision:V1.4.0,
Revision:V1.4.0,
Revision:V1.4.0,
Revision:V1.4.0,
Revision:V1.4.0,
Revision:V1.4.0,
Revision:V1.4.0,
Revision:V1.4.0,
Revision:V1.4.0,
Revision:V1.4.0,
Revision:V1.4.0,
Revision:V1.4.0,
Revision:V1.4.0,
Revision:V1.4.0,
Revision:V1.4.0,
Revision:V1.4.0,
Revision:V1.4.0,
Revision:V1.4.0,
Revision:V1.4.0,
Revision:V1.4.0,
Revision:V1.4.0,
Revision:V1.4.0,
Revision:V1.4.0,
Revision:V1.4.0,
Revision:V1.4.0,
Revision:V1.4.0,
Revision:V1.4.0,
Revision:V1.4.0,
Revision:V1.4.0,
Revision:V1.4.0,
Revision:V1.4.0,
Revision:V1.4.0,
Revision:V1.4.0,
Revision:V1.4.0,
Revision:V1.4.0,
Revision:V1.4.0,
Revision:V1.4.0,
Revision:V1.4.0,
Revision:V1.4.0,
Revision:V1.4.0,
Revision:V1.4.0,
Revision:V1.4.0,
Revision:V1.4.0,
Revision:V1.4.0,
Revision:V1.4.0,
Revision:V1.4.0,
Revision:V1.4.0,
Revision:V1.4.0,
Revision:V1.4.0,
Revision:V1.4.0,
Revision:V1.4.0,
Revision:V1.4.0,
Revision:V1.4.0,
Revision:V1.4.0,
Revision:V1.4.0,
Revision:V1.4.0,
Revision:V1.4.0,
Revision:V1.4.0,
Revision:V1.4.0,
Revision:V1.4.0,
Revision:V1.4.0,
Revision:V1.4.0,
Revision:V1.4.0,
Revision:V1.4.0,
Revision:V1.4.0,
Revision:V1.4.0,
Revision:V1.4.0,
Revision:V1.4.0,
Revision:V1.4.0,
Revision:V1.4.0,
Revision:V1.4.0,
Revision:V1.4.0,
Revision:V1.4.0,
Revision:V1.4.0,
Revision:V1.4.0,
Revision:V1.4.0,
Revision:V1.4.0,
Revision:V1.4.0,
Revision:V1.4.0,
Revision:V1.4.0,
Revision:V1.4.0,
Revision:V1.4.0,
Revision:V1.4.0,
Revision:V1.4.0,
Revision:V1.4.0,
Revision:V1.4.0,
Revision:V1.4.0,
Revision:V1.4.0,
Revision:V1.4.0,
Revision:V1.4.0,
Revision:V1.4.0,
Revision:V1.4.0,
Revision:V1.4.0,
Revision:V1.4.0,
Revision:V1.4.0,
Revision:V1.4.0,
Revision:V1.4.0,
Revision:V1.4.0,
Revision:V1.4.0,
Revision:V1.4.0,
Revision:V1.4.0,
Revision:V1.4.0,
Revision:V1.4.0,
Revision:V1.4.0,
Revision:V1.4.0,
Revision:V1.4.0,
Revision:V1.4.0,
Revision:V1.4.0,
Revision:V1.4.0,
Revision:V1.4.0,
Revision:V1.4.0,
Revision:V1.4.0,
Revision:V1.4.0,
Revision:V1.4.0,
Revision:V1.4.0,
Revision:V1.4.0,
Revision:V1.4.0,
Revision:V1.4.0,
Revision:V1.4.0,
Revision:V1.4.0,
Revision:V1.4.0,
Revision:V1.4.0,
Revision:V1.4.0,
Revision:V1.4.0,
Revision:V1.4.0,
Revision:V1.4.0,
Revision:V1.4.0,
Revision:V1.4.0,
Revision:V1.4.0,
Revision:V1.4.0,
Revision:V1.4.0,
Revision:V1.4.0,
Revision:V1.4.0,
Revision:V1.4.0,
Revision:V1.4.0,
Revision:V1.4.0,
Revision:V1.4.0,
Revision:V1.4.0,
Revision:V1.4.0,
Revision:V1.4.0,
Revision:V1.4.0,
Revision:V1.4.0,
Revision:V1.4.0,
Revision:V1.4.0,
Revision:V1.4.0,
Revision:V1.4.0,
Revision:V1.4.0,
Revision:V1.4.0,
Revision:V1.4.0,
Revision:V1.4.0,
Revision:V1.4.0,
Revision:V1.4.0,
Revision:V1.4.0,
Revision:V1.4.0,
Revision:V1.4.0,
Revision:V1.4.0,
Revision:V1.4.0,
Revision:V1.4.0,
Revision:V1.4.0,
Revision:V1.4.0,
Revision:V1.4.0,
Revision:V1.4.0,
Revision:V1.4.0,
Revision:V1.4.0,
Revision:V1.4.0,
Revision:V1.4.0,
Revision:V1.4.0,
Revision:V1.4.0,
Revision:V1.4.0,
Revision:V1.4.0,
Revision:V1.4.0,
Revision:V1.4.0,
Revision:V1.4.0,
Revision:V1.4.0";
